VERSION "dbc-export 1 2025.20.8"

NS_ :

BS_:

BU_: ADSP APB APP APS APSB BB BMS CC CMP CMPD CP DAS DI DIF DIR DPB EPAS3P EPAS3S EPASTP EPASTS EPBL EPBR ESP EVSE FC GTW HCML HCMR HVP IBST ICR IDB LS OCS1P PARK PCS PM PMF PMR PNCD PTC RADC RCM RCM2 RCM3 RCU SCCM SCM SCS SDCR TAS TCU TPMS TRCM UI UIS UMC USM VC VCFRONT VCLEFT VCRIGHT VCSEC VEH

BO_ 969 VCSEC_BLEEndpointInfo: 8 VCSEC
 SG_ VCSEC_BLEEndpointInfoIndex M : 0|8@1+ (1,0) [0|255] "" Vector__XXX
 SG_ VCSEC_BLECENTERComponentID m1 : 8|16@1+ (1,0) [0|65535] "" Vector__XXX
 SG_ VCSEC_BLECENTERPcbaID m1 : 24|8@1+ (1,0) [0|255] "" Vector__XXX
 SG_ VCSEC_BLECENTERAssemblyID m1 : 32|8@1+ (1,0) [0|255] "" Vector__XXX
 SG_ VCSEC_BLECENTERUsageID m1 : 40|16@1+ (1,0) [0|65535] "" Vector__XXX
 SG_ VCSEC_BLECENTERCrc m2 : 8|32@1+ (1,0) [0|4294967295] "" Vector__XXX
 SG_ VCSEC_BLELEFTAppGitHashByte m3 : 8|56@1+ (1,0) [0|7.20575940379e+16] "" Vector__XXX
 SG_ VCSEC_BLELEFTComponentID m4 : 8|16@1+ (1,0) [0|65535] "" Vector__XXX
 SG_ VCSEC_BLELEFTPcbaID m4 : 24|8@1+ (1,0) [0|255] "" Vector__XXX
 SG_ VCSEC_BLELEFTAssemblyID m4 : 32|8@1+ (1,0) [0|255] "" Vector__XXX
 SG_ VCSEC_BLELEFTUsageID m4 : 40|16@1+ (1,0) [0|65535] "" Vector__XXX
 SG_ VCSEC_BLELEFTCrc m5 : 8|32@1+ (1,0) [0|4294967295] "" Vector__XXX
 SG_ VCSEC_BLERIGHTAppGitHashByte m6 : 8|56@1+ (1,0) [0|7.20575940379e+16] "" Vector__XXX
 SG_ VCSEC_BLERIGHTComponentID m7 : 8|16@1+ (1,0) [0|65535] "" Vector__XXX
 SG_ VCSEC_BLERIGHTPcbaID m7 : 24|8@1+ (1,0) [0|255] "" Vector__XXX
 SG_ VCSEC_BLERIGHTAssemblyID m7 : 32|8@1+ (1,0) [0|255] "" Vector__XXX
 SG_ VCSEC_BLERIGHTUsageID m7 : 40|16@1+ (1,0) [0|65535] "" Vector__XXX
 SG_ VCSEC_BLERIGHTCrc m8 : 8|32@1+ (1,0) [0|4294967295] "" Vector__XXX
 SG_ VCSEC_BLEREARAppGitHashByte m9 : 8|56@1+ (1,0) [0|7.20575940379e+16] "" Vector__XXX
 SG_ VCSEC_BLEREARComponentID m10 : 8|16@1+ (1,0) [0|65535] "" Vector__XXX
 SG_ VCSEC_BLEREARPcbaID m10 : 24|8@1+ (1,0) [0|255] "" Vector__XXX
 SG_ VCSEC_BLEREARAssemblyID m10 : 32|8@1+ (1,0) [0|255] "" Vector__XXX
 SG_ VCSEC_BLEREARUsageID m10 : 40|16@1+ (1,0) [0|65535] "" Vector__XXX
 SG_ VCSEC_BLEREARCrc m11 : 8|32@1+ (1,0) [0|4294967295] "" Vector__XXX
 SG_ VCSEC_UWBRightCrc m12 : 8|32@1+ (1,0) [0|4294967295] "" Vector__XXX
 SG_ VCSEC_UWBRightRadioConfigState m12 : 40|4@1+ (1,0) [0|15] "" Vector__XXX
 SG_ VCSEC_UWBRightUpdateStatus m12 : 44|3@1+ (1,0) [0|7] "" Vector__XXX
 SG_ VCSEC_UWBRightRetryLimitReached m12 : 47|1@1+ (1,0) [0|1] "" Vector__XXX
 SG_ VCSEC_UWBRightDspVersion m12 : 48|16@1+ (1,0) [0|65535] "" Vector__XXX
 SG_ VCSEC_UWBRightComponentID m13 : 8|8@1+ (1,0) [0|255] "" Vector__XXX
 SG_ VCSEC_UWBRightPcbaID m13 : 16|8@1+ (1,0) [0|255] "" Vector__XXX
 SG_ VCSEC_UWBRightAssemblyID m13 : 24|8@1+ (1,0) [0|255] "" Vector__XXX
 SG_ VCSEC_UWBRightUsageID m13 : 32|16@1+ (1,0) [0|65535] "" Vector__XXX
 SG_ VCSEC_UWBRearRightCrc m15 : 8|32@1+ (1,0) [0|4294967295] "" Vector__XXX
 SG_ VCSEC_UWBRearRightRadioConfigSta m15 : 40|4@1+ (1,0) [0|15] "" Vector__XXX
 SG_ VCSEC_UWBRearRightUpdateStatus m15 : 44|3@1+ (1,0) [0|7] "" Vector__XXX
 SG_ VCSEC_UWBRearRightRetryLimitReac m15 : 47|1@1+ (1,0) [0|1] "" Vector__XXX
 SG_ VCSEC_UWBRearRightDspVersion m15 : 48|16@1+ (1,0) [0|65535] "" Vector__XXX
 SG_ VCSEC_UWBRearRightComponentID m16 : 8|8@1+ (1,0) [0|255] "" Vector__XXX
 SG_ VCSEC_UWBRearRightPcbaID m16 : 16|8@1+ (1,0) [0|255] "" Vector__XXX
 SG_ VCSEC_UWBRearRightAssemblyID m16 : 24|8@1+ (1,0) [0|255] "" Vector__XXX
 SG_ VCSEC_UWBRearRightUsageID m16 : 32|16@1+ (1,0) [0|65535] "" Vector__XXX
 SG_ VCSEC_UWBRearLeftCrc m18 : 8|32@1+ (1,0) [0|4294967295] "" Vector__XXX
 SG_ VCSEC_UWBRearLeftRadioConfigStat m18 : 40|4@1+ (1,0) [0|15] "" Vector__XXX
 SG_ VCSEC_UWBRearLeftUpdateStatus m18 : 44|3@1+ (1,0) [0|7] "" Vector__XXX
 SG_ VCSEC_UWBRearLeftRetryLimitReach m18 : 47|1@1+ (1,0) [0|1] "" Vector__XXX
 SG_ VCSEC_UWBRearLeftDspVersion m18 : 48|16@1+ (1,0) [0|65535] "" Vector__XXX
 SG_ VCSEC_UWBRearLeftComponentID m19 : 8|8@1+ (1,0) [0|255] "" Vector__XXX
 SG_ VCSEC_UWBRearLeftPcbaID m19 : 16|8@1+ (1,0) [0|255] "" Vector__XXX
 SG_ VCSEC_UWBRearLeftAssemblyID m19 : 24|8@1+ (1,0) [0|255] "" Vector__XXX
 SG_ VCSEC_UWBRearLeftUsageID m19 : 32|16@1+ (1,0) [0|65535] "" Vector__XXX
 SG_ VCSEC_UWBRearCrc m21 : 8|32@1+ (1,0) [0|4294967295] "" Vector__XXX
 SG_ VCSEC_UWBRearRadioConfigState m21 : 40|4@1+ (1,0) [0|15] "" Vector__XXX
 SG_ VCSEC_UWBRearUpdateStatus m21 : 44|3@1+ (1,0) [0|7] "" Vector__XXX
 SG_ VCSEC_UWBRearRetryLimitReached m21 : 47|1@1+ (1,0) [0|1] "" Vector__XXX
 SG_ VCSEC_UWBRearDspVersion m21 : 48|16@1+ (1,0) [0|65535] "" Vector__XXX
 SG_ VCSEC_UWBRearComponentID m22 : 8|8@1+ (1,0) [0|255] "" Vector__XXX
 SG_ VCSEC_UWBRearPcbaID m22 : 16|8@1+ (1,0) [0|255] "" Vector__XXX
 SG_ VCSEC_UWBRearAssemblyID m22 : 24|8@1+ (1,0) [0|255] "" Vector__XXX
 SG_ VCSEC_UWBRearUsageID m22 : 32|16@1+ (1,0) [0|65535] "" Vector__XXX
 SG_ VCSEC_UWBLeftCrc m24 : 8|32@1+ (1,0) [0|4294967295] "" Vector__XXX
 SG_ VCSEC_UWBLeftRadioConfigState m24 : 40|4@1+ (1,0) [0|15] "" Vector__XXX
 SG_ VCSEC_UWBLeftUpdateStatus m24 : 44|3@1+ (1,0) [0|7] "" Vector__XXX
 SG_ VCSEC_UWBLeftRetryLimitReached m24 : 47|1@1+ (1,0) [0|1] "" Vector__XXX
 SG_ VCSEC_UWBLeftDspVersion m24 : 48|16@1+ (1,0) [0|65535] "" Vector__XXX
 SG_ VCSEC_UWBLeftComponentID m25 : 8|8@1+ (1,0) [0|255] "" Vector__XXX
 SG_ VCSEC_UWBLeftPcbaID m25 : 16|8@1+ (1,0) [0|255] "" Vector__XXX
 SG_ VCSEC_UWBLeftAssemblyID m25 : 24|8@1+ (1,0) [0|255] "" Vector__XXX
 SG_ VCSEC_UWBLeftUsageID m25 : 32|16@1+ (1,0) [0|65535] "" Vector__XXX
 SG_ VCSEC_UWBCenterCrc m27 : 8|32@1+ (1,0) [0|4294967295] "" Vector__XXX
 SG_ VCSEC_UWBCenterRadioConfigState m27 : 40|4@1+ (1,0) [0|15] "" Vector__XXX
 SG_ VCSEC_UWBCenterUpdateStatus m27 : 44|3@1+ (1,0) [0|7] "" Vector__XXX
 SG_ VCSEC_UWBCenterRetryLimitReached m27 : 47|1@1+ (1,0) [0|1] "" Vector__XXX
 SG_ VCSEC_UWBCenterDspVersion m27 : 48|16@1+ (1,0) [0|65535] "" Vector__XXX
 SG_ VCSEC_UWBCenterComponentID m28 : 8|8@1+ (1,0) [0|255] "" Vector__XXX
 SG_ VCSEC_UWBCenterPcbaID m28 : 16|8@1+ (1,0) [0|255] "" Vector__XXX
 SG_ VCSEC_UWBCenterAssemblyID m28 : 24|8@1+ (1,0) [0|255] "" Vector__XXX
 SG_ VCSEC_UWBCenterUsageID m28 : 32|16@1+ (1,0) [0|65535] "" Vector__XXX
 SG_ VCSEC_BLERIGHTREARCrc m30 : 8|32@1+ (1,0) [0|4294967295] "" Vector__XXX
 SG_ VCSEC_BLERIGHTREARComponentID m31 : 8|16@1+ (1,0) [0|65535] "" Vector__XXX
 SG_ VCSEC_BLERIGHTREARPcbaID m31 : 24|8@1+ (1,0) [0|255] "" Vector__XXX
 SG_ VCSEC_BLERIGHTREARAssemblyID m31 : 32|8@1+ (1,0) [0|255] "" Vector__XXX
 SG_ VCSEC_BLERIGHTREARUsageID m31 : 40|16@1+ (1,0) [0|65535] "" Vector__XXX
 SG_ VCSEC_BLENFCCRADLECrc m33 : 8|32@1+ (1,0) [0|4294967295] "" Vector__XXX
 SG_ VCSEC_BLENFCCRADLEComponentID m34 : 8|16@1+ (1,0) [0|65535] "" Vector__XXX
 SG_ VCSEC_BLENFCCRADLEPcbaID m34 : 24|8@1+ (1,0) [0|255] "" Vector__XXX
 SG_ VCSEC_BLENFCCRADLEAssemblyID m34 : 32|8@1+ (1,0) [0|255] "" Vector__XXX
 SG_ VCSEC_BLENFCCRADLEUsageID m34 : 40|16@1+ (1,0) [0|65535] "" Vector__XXX
 SG_ VCSEC_BLELEFTREARCrc m36 : 8|32@1+ (1,0) [0|4294967295] "" Vector__XXX
 SG_ VCSEC_BLELEFTREARComponentID m37 : 8|16@1+ (1,0) [0|65535] "" Vector__XXX
 SG_ VCSEC_BLELEFTREARPcbaID m37 : 24|8@1+ (1,0) [0|255] "" Vector__XXX
 SG_ VCSEC_BLELEFTREARAssemblyID m37 : 32|8@1+ (1,0) [0|255] "" Vector__XXX
 SG_ VCSEC_BLELEFTREARUsageID m37 : 40|16@1+ (1,0) [0|65535] "" Vector__XXX

BO_ 607 VCSEC_ChildSeatStatus: 8 VCSEC
 SG_ VCSEC_childSeat0_connectionState : 0|3@1+ (1,0) [0|7] "" Vector__XXX
 SG_ VCSEC_childSeat0_taskDisconnecti : 3|2@1+ (1,0) [0|3] "" Vector__XXX
 SG_ VCSEC_childSeat0_state : 5|4@1+ (1,0) [0|15] "" Vector__XXX
 SG_ VCSEC_childSeat0_taskErrorCode : 9|3@1+ (1,0) [0|7] "" Vector__XXX
 SG_ VCSEC_childSeat0_RSSI : 12|8@1- (1,0) [-128|127] "" Vector__XXX
 SG_ VCSEC_childSeat0_ISOFixStatus : 20|2@1+ (1,0) [0|3] "" Vector__XXX
 SG_ VCSEC_childSeat0_buckleStatus : 22|2@1+ (1,0) [0|3] "" Vector__XXX
 SG_ VCSEC_childSeat0_occupancyStatus : 24|2@1+ (1,0) [0|3] "" Vector__XXX
 SG_ VCSEC_childSeat1_connectionState : 26|3@1+ (1,0) [0|7] "" Vector__XXX
 SG_ VCSEC_childSeat1_taskDisconnecti : 29|2@1+ (1,0) [0|3] "" Vector__XXX
 SG_ VCSEC_childSeat1_state : 31|4@1+ (1,0) [0|15] "" Vector__XXX
 SG_ VCSEC_childSeat1_taskErrorCode : 35|3@1+ (1,0) [0|7] "" Vector__XXX
 SG_ VCSEC_childSeat1_RSSI : 38|8@1- (1,0) [-128|127] "" Vector__XXX
 SG_ VCSEC_childSeat1_ISOFixStatus : 46|2@1+ (1,0) [0|3] "" Vector__XXX
 SG_ VCSEC_childSeat1_buckleStatus : 48|2@1+ (1,0) [0|3] "" Vector__XXX
 SG_ VCSEC_childSeat1_occupancyStatus : 50|2@1+ (1,0) [0|3] "" Vector__XXX
 SG_ VCSEC_childPresenceDetectionWarn : 52|1@1+ (1,0) [0|1] "" Vector__XXX
 SG_ VCSEC_childSeatScanStatus : 53|2@1+ (1,0) [0|3] "" Vector__XXX
 SG_ VCSEC_childPresenceDetectionStat : 55|4@1+ (1,0) [0|15] "" Vector__XXX
 SG_ VCSEC_childPresenceDetectionSupp : 59|2@1+ (1,0) [0|3] "" Vector__XXX
 SG_ VCSEC_childPresenceDetectionNoti : 61|1@1+ (1,0) [0|1] "" Vector__XXX

BO_ 857 VCSEC_DeviceStatus: 8 VCSEC
 SG_ VCSEC_DeviceStatusIndex M : 0|7@1+ (1,0) [0|127] "" Vector__XXX
 SG_ VCSEC_Device0AuthResponseTime m0 : 7|7@1+ (50,0) [0|6300] "ms" Vector__XXX
 SG_ VCSEC_Device0Impermanent m0 : 14|1@1+ (1,0) [0|1] "" Vector__XXX
 SG_ VCSEC_Device0SELockedDown m0 : 15|1@1+ (1,0) [0|1] "" Vector__XXX
 SG_ VCSEC_Device0Version m0 : 16|16@1+ (1,0) [0|65535] "" Vector__XXX
 SG_ VCSEC_Device0WLEntry m0 : 32|5@1+ (1,0) [0|31] "" Vector__XXX
 SG_ VCSEC_Device0OSVersion m0 : 37|12@1+ (1,0) [0|4095] "" Vector__XXX
 SG_ VCSEC_Device0BatteryLevel m0 : 49|8@1+ (0.015625,0) [0|3.9] "V" Vector__XXX
 SG_ VCSEC_Device0Formfactor m0 : 57|5@1+ (1,0) [0|31] "" Vector__XXX
 SG_ VCSEC_Device0BlacklistStatus m0 : 62|1@1+ (1,0) [0|1] "" Vector__XXX
 SG_ VCSEC_Device0Stationary m0 : 63|1@1+ (1,0) [0|1] "" Vector__XXX
 SG_ VCSEC_Device0Bonded m2 : 8|1@1+ (1,0) [0|1] "" Vector__XXX
 SG_ VCSEC_Device0Role m2 : 9|4@1+ (1,0) [0|15] "" Vector__XXX
 SG_ VCSEC_Device0WhitelistActiveTime m2 : 16|16@1+ (1,0) [0|65535] "mins" Vector__XXX
 SG_ VCSEC_Device0SHA1 m2 : 32|32@1+ (1,0) [0|4294967295] "" Vector__XXX
 SG_ VCSEC_Device0Permissions m3 : 32|32@1+ (1,0) [0|4294967295] "" Vector__XXX
 SG_ VCSEC_Device0ManufacturerHashBit m5 : 8|24@1+ (1,0) [0|16777215] "" Vector__XXX
 SG_ VCSEC_Device0BuildNumberHashBits m5 : 32|32@1+ (1,0) [0|4294967295] "" Vector__XXX
 SG_ VCSEC_Device1AuthResponseTime m6 : 7|7@1+ (50,0) [0|6300] "ms" Vector__XXX
 SG_ VCSEC_Device1Impermanent m6 : 14|1@1+ (1,0) [0|1] "" Vector__XXX
 SG_ VCSEC_Device1SELockedDown m6 : 15|1@1+ (1,0) [0|1] "" Vector__XXX
 SG_ VCSEC_Device1Version m6 : 16|16@1+ (1,0) [0|65535] "" Vector__XXX
 SG_ VCSEC_Device1WLEntry m6 : 32|5@1+ (1,0) [0|31] "" Vector__XXX
 SG_ VCSEC_Device1OSVersion m6 : 37|12@1+ (1,0) [0|4095] "" Vector__XXX
 SG_ VCSEC_Device1BatteryLevel m6 : 49|8@1+ (0.015625,0) [0|3.9] "V" Vector__XXX
 SG_ VCSEC_Device1Formfactor m6 : 57|5@1+ (1,0) [0|31] "" Vector__XXX
 SG_ VCSEC_Device1BlacklistStatus m6 : 62|1@1+ (1,0) [0|1] "" Vector__XXX
 SG_ VCSEC_Device1Stationary m6 : 63|1@1+ (1,0) [0|1] "" Vector__XXX
 SG_ VCSEC_Device1Bonded m8 : 8|1@1+ (1,0) [0|1] "" Vector__XXX
 SG_ VCSEC_Device1Role m8 : 9|4@1+ (1,0) [0|15] "" Vector__XXX
 SG_ VCSEC_Device1WhitelistActiveTime m8 : 16|16@1+ (1,0) [0|65535] "mins" Vector__XXX
 SG_ VCSEC_Device1SHA1 m8 : 32|32@1+ (1,0) [0|4294967295] "" Vector__XXX
 SG_ VCSEC_Device1Permissions m9 : 32|32@1+ (1,0) [0|4294967295] "" Vector__XXX
 SG_ VCSEC_Device1ManufacturerHashBit m11 : 8|24@1+ (1,0) [0|16777215] "" Vector__XXX
 SG_ VCSEC_Device1BuildNumberHashBits m11 : 32|32@1+ (1,0) [0|4294967295] "" Vector__XXX
 SG_ VCSEC_Device2AuthResponseTime m12 : 7|7@1+ (50,0) [0|6300] "ms" Vector__XXX
 SG_ VCSEC_Device2Impermanent m12 : 14|1@1+ (1,0) [0|1] "" Vector__XXX
 SG_ VCSEC_Device2SELockedDown m12 : 15|1@1+ (1,0) [0|1] "" Vector__XXX
 SG_ VCSEC_Device2Version m12 : 16|16@1+ (1,0) [0|65535] "" Vector__XXX
 SG_ VCSEC_Device2WLEntry m12 : 32|5@1+ (1,0) [0|31] "" Vector__XXX
 SG_ VCSEC_Device2OSVersion m12 : 37|12@1+ (1,0) [0|4095] "" Vector__XXX
 SG_ VCSEC_Device2BatteryLevel m12 : 49|8@1+ (0.015625,0) [0|3.9] "V" Vector__XXX
 SG_ VCSEC_Device2Formfactor m12 : 57|5@1+ (1,0) [0|31] "" Vector__XXX
 SG_ VCSEC_Device2BlacklistStatus m12 : 62|1@1+ (1,0) [0|1] "" Vector__XXX
 SG_ VCSEC_Device2Stationary m12 : 63|1@1+ (1,0) [0|1] "" Vector__XXX
 SG_ VCSEC_Device2Bonded m14 : 8|1@1+ (1,0) [0|1] "" Vector__XXX
 SG_ VCSEC_Device2Role m14 : 9|4@1+ (1,0) [0|15] "" Vector__XXX
 SG_ VCSEC_Device2WhitelistActiveTime m14 : 16|16@1+ (1,0) [0|65535] "mins" Vector__XXX
 SG_ VCSEC_Device2SHA1 m14 : 32|32@1+ (1,0) [0|4294967295] "" Vector__XXX
 SG_ VCSEC_Device2Permissions m15 : 32|32@1+ (1,0) [0|4294967295] "" Vector__XXX
 SG_ VCSEC_Device2ManufacturerHashBit m17 : 8|24@1+ (1,0) [0|16777215] "" Vector__XXX
 SG_ VCSEC_Device2BuildNumberHashBits m17 : 32|32@1+ (1,0) [0|4294967295] "" Vector__XXX
 SG_ VCSEC_Device3AuthResponseTime m18 : 7|7@1+ (50,0) [0|6300] "ms" Vector__XXX
 SG_ VCSEC_Device3Impermanent m18 : 14|1@1+ (1,0) [0|1] "" Vector__XXX
 SG_ VCSEC_Device3SELockedDown m18 : 15|1@1+ (1,0) [0|1] "" Vector__XXX
 SG_ VCSEC_Device3Version m18 : 16|16@1+ (1,0) [0|65535] "" Vector__XXX
 SG_ VCSEC_Device3WLEntry m18 : 32|5@1+ (1,0) [0|31] "" Vector__XXX
 SG_ VCSEC_Device3OSVersion m18 : 37|12@1+ (1,0) [0|4095] "" Vector__XXX
 SG_ VCSEC_Device3BatteryLevel m18 : 49|8@1+ (0.015625,0) [0|3.9] "V" Vector__XXX
 SG_ VCSEC_Device3Formfactor m18 : 57|5@1+ (1,0) [0|31] "" Vector__XXX
 SG_ VCSEC_Device3BlacklistStatus m18 : 62|1@1+ (1,0) [0|1] "" Vector__XXX
 SG_ VCSEC_Device3Stationary m18 : 63|1@1+ (1,0) [0|1] "" Vector__XXX
 SG_ VCSEC_Device3Bonded m20 : 8|1@1+ (1,0) [0|1] "" Vector__XXX
 SG_ VCSEC_Device3Role m20 : 9|4@1+ (1,0) [0|15] "" Vector__XXX
 SG_ VCSEC_Device3WhitelistActiveTime m20 : 16|16@1+ (1,0) [0|65535] "mins" Vector__XXX
 SG_ VCSEC_Device3SHA1 m20 : 32|32@1+ (1,0) [0|4294967295] "" Vector__XXX
 SG_ VCSEC_Device3Permissions m21 : 32|32@1+ (1,0) [0|4294967295] "" Vector__XXX
 SG_ VCSEC_Device3ManufacturerHashBit m23 : 8|24@1+ (1,0) [0|16777215] "" Vector__XXX
 SG_ VCSEC_Device3BuildNumberHashBits m23 : 32|32@1+ (1,0) [0|4294967295] "" Vector__XXX
 SG_ VCSEC_Device4AuthResponseTime m24 : 7|7@1+ (50,0) [0|6300] "ms" Vector__XXX
 SG_ VCSEC_Device4Impermanent m24 : 14|1@1+ (1,0) [0|1] "" Vector__XXX
 SG_ VCSEC_Device4SELockedDown m24 : 15|1@1+ (1,0) [0|1] "" Vector__XXX
 SG_ VCSEC_Device4Version m24 : 16|16@1+ (1,0) [0|65535] "" Vector__XXX
 SG_ VCSEC_Device4WLEntry m24 : 32|5@1+ (1,0) [0|31] "" Vector__XXX
 SG_ VCSEC_Device4OSVersion m24 : 37|12@1+ (1,0) [0|4095] "" Vector__XXX
 SG_ VCSEC_Device4BatteryLevel m24 : 49|8@1+ (0.015625,0) [0|3.9] "V" Vector__XXX
 SG_ VCSEC_Device4Formfactor m24 : 57|5@1+ (1,0) [0|31] "" Vector__XXX
 SG_ VCSEC_Device4BlacklistStatus m24 : 62|1@1+ (1,0) [0|1] "" Vector__XXX
 SG_ VCSEC_Device4Stationary m24 : 63|1@1+ (1,0) [0|1] "" Vector__XXX
 SG_ VCSEC_Device4Bonded m26 : 8|1@1+ (1,0) [0|1] "" Vector__XXX
 SG_ VCSEC_Device4Role m26 : 9|4@1+ (1,0) [0|15] "" Vector__XXX
 SG_ VCSEC_Device4WhitelistActiveTime m26 : 16|16@1+ (1,0) [0|65535] "mins" Vector__XXX
 SG_ VCSEC_Device4SHA1 m26 : 32|32@1+ (1,0) [0|4294967295] "" Vector__XXX
 SG_ VCSEC_Device4Permissions m27 : 32|32@1+ (1,0) [0|4294967295] "" Vector__XXX
 SG_ VCSEC_Device4ManufacturerHashBit m29 : 8|24@1+ (1,0) [0|16777215] "" Vector__XXX
 SG_ VCSEC_Device4BuildNumberHashBits m29 : 32|32@1+ (1,0) [0|4294967295] "" Vector__XXX
 SG_ VCSEC_Device5AuthResponseTime m30 : 7|7@1+ (50,0) [0|6300] "ms" Vector__XXX
 SG_ VCSEC_Device5Impermanent m30 : 14|1@1+ (1,0) [0|1] "" Vector__XXX
 SG_ VCSEC_Device5SELockedDown m30 : 15|1@1+ (1,0) [0|1] "" Vector__XXX
 SG_ VCSEC_Device5Version m30 : 16|16@1+ (1,0) [0|65535] "" Vector__XXX
 SG_ VCSEC_Device5WLEntry m30 : 32|5@1+ (1,0) [0|31] "" Vector__XXX
 SG_ VCSEC_Device5OSVersion m30 : 37|12@1+ (1,0) [0|4095] "" Vector__XXX
 SG_ VCSEC_Device5BatteryLevel m30 : 49|8@1+ (0.015625,0) [0|3.9] "V" Vector__XXX
 SG_ VCSEC_Device5Formfactor m30 : 57|5@1+ (1,0) [0|31] "" Vector__XXX
 SG_ VCSEC_Device5BlacklistStatus m30 : 62|1@1+ (1,0) [0|1] "" Vector__XXX
 SG_ VCSEC_Device5Stationary m30 : 63|1@1+ (1,0) [0|1] "" Vector__XXX
 SG_ VCSEC_Device5Bonded m32 : 8|1@1+ (1,0) [0|1] "" Vector__XXX
 SG_ VCSEC_Device5Role m32 : 9|4@1+ (1,0) [0|15] "" Vector__XXX
 SG_ VCSEC_Device5WhitelistActiveTime m32 : 16|16@1+ (1,0) [0|65535] "mins" Vector__XXX
 SG_ VCSEC_Device5SHA1 m32 : 32|32@1+ (1,0) [0|4294967295] "" Vector__XXX
 SG_ VCSEC_Device5Permissions m33 : 32|32@1+ (1,0) [0|4294967295] "" Vector__XXX
 SG_ VCSEC_Device5ManufacturerHashBit m35 : 8|24@1+ (1,0) [0|16777215] "" Vector__XXX
 SG_ VCSEC_Device5BuildNumberHashBits m35 : 32|32@1+ (1,0) [0|4294967295] "" Vector__XXX
 SG_ VCSEC_Device6AuthResponseTime m36 : 7|7@1+ (50,0) [0|6300] "ms" Vector__XXX
 SG_ VCSEC_Device6Impermanent m36 : 14|1@1+ (1,0) [0|1] "" Vector__XXX
 SG_ VCSEC_Device6SELockedDown m36 : 15|1@1+ (1,0) [0|1] "" Vector__XXX
 SG_ VCSEC_Device6Version m36 : 16|16@1+ (1,0) [0|65535] "" Vector__XXX
 SG_ VCSEC_Device6WLEntry m36 : 32|5@1+ (1,0) [0|31] "" Vector__XXX
 SG_ VCSEC_Device6OSVersion m36 : 37|12@1+ (1,0) [0|4095] "" Vector__XXX
 SG_ VCSEC_Device6BatteryLevel m36 : 49|8@1+ (0.015625,0) [0|3.9] "V" Vector__XXX
 SG_ VCSEC_Device6Formfactor m36 : 57|5@1+ (1,0) [0|31] "" Vector__XXX
 SG_ VCSEC_Device6BlacklistStatus m36 : 62|1@1+ (1,0) [0|1] "" Vector__XXX
 SG_ VCSEC_Device6Stationary m36 : 63|1@1+ (1,0) [0|1] "" Vector__XXX
 SG_ VCSEC_Device6Bonded m38 : 8|1@1+ (1,0) [0|1] "" Vector__XXX
 SG_ VCSEC_Device6Role m38 : 9|4@1+ (1,0) [0|15] "" Vector__XXX
 SG_ VCSEC_Device6WhitelistActiveTime m38 : 16|16@1+ (1,0) [0|65535] "mins" Vector__XXX
 SG_ VCSEC_Device6SHA1 m38 : 32|32@1+ (1,0) [0|4294967295] "" Vector__XXX
 SG_ VCSEC_Device6Permissions m39 : 32|32@1+ (1,0) [0|4294967295] "" Vector__XXX
 SG_ VCSEC_Device6ManufacturerHashBit m41 : 8|24@1+ (1,0) [0|16777215] "" Vector__XXX
 SG_ VCSEC_Device6BuildNumberHashBits m41 : 32|32@1+ (1,0) [0|4294967295] "" Vector__XXX
 SG_ VCSEC_Device7AuthResponseTime m42 : 7|7@1+ (50,0) [0|6300] "ms" Vector__XXX
 SG_ VCSEC_Device7Impermanent m42 : 14|1@1+ (1,0) [0|1] "" Vector__XXX
 SG_ VCSEC_Device7SELockedDown m42 : 15|1@1+ (1,0) [0|1] "" Vector__XXX
 SG_ VCSEC_Device7Version m42 : 16|16@1+ (1,0) [0|65535] "" Vector__XXX
 SG_ VCSEC_Device7WLEntry m42 : 32|5@1+ (1,0) [0|31] "" Vector__XXX
 SG_ VCSEC_Device7OSVersion m42 : 37|12@1+ (1,0) [0|4095] "" Vector__XXX
 SG_ VCSEC_Device7BatteryLevel m42 : 49|8@1+ (0.015625,0) [0|3.9] "V" Vector__XXX
 SG_ VCSEC_Device7Formfactor m42 : 57|5@1+ (1,0) [0|31] "" Vector__XXX
 SG_ VCSEC_Device7BlacklistStatus m42 : 62|1@1+ (1,0) [0|1] "" Vector__XXX
 SG_ VCSEC_Device7Stationary m42 : 63|1@1+ (1,0) [0|1] "" Vector__XXX
 SG_ VCSEC_Device7Bonded m44 : 8|1@1+ (1,0) [0|1] "" Vector__XXX
 SG_ VCSEC_Device7Role m44 : 9|4@1+ (1,0) [0|15] "" Vector__XXX
 SG_ VCSEC_Device7WhitelistActiveTime m44 : 16|16@1+ (1,0) [0|65535] "mins" Vector__XXX
 SG_ VCSEC_Device7SHA1 m44 : 32|32@1+ (1,0) [0|4294967295] "" Vector__XXX
 SG_ VCSEC_Device7Permissions m45 : 32|32@1+ (1,0) [0|4294967295] "" Vector__XXX
 SG_ VCSEC_Device7ManufacturerHashBit m47 : 8|24@1+ (1,0) [0|16777215] "" Vector__XXX
 SG_ VCSEC_Device7BuildNumberHashBits m47 : 32|32@1+ (1,0) [0|4294967295] "" Vector__XXX
 SG_ VCSEC_Device8AuthResponseTime m48 : 7|7@1+ (50,0) [0|6300] "ms" Vector__XXX
 SG_ VCSEC_Device8Impermanent m48 : 14|1@1+ (1,0) [0|1] "" Vector__XXX
 SG_ VCSEC_Device8SELockedDown m48 : 15|1@1+ (1,0) [0|1] "" Vector__XXX
 SG_ VCSEC_Device8Version m48 : 16|16@1+ (1,0) [0|65535] "" Vector__XXX
 SG_ VCSEC_Device8WLEntry m48 : 32|5@1+ (1,0) [0|31] "" Vector__XXX
 SG_ VCSEC_Device8OSVersion m48 : 37|12@1+ (1,0) [0|4095] "" Vector__XXX
 SG_ VCSEC_Device8BatteryLevel m48 : 49|8@1+ (0.015625,0) [0|3.9] "V" Vector__XXX
 SG_ VCSEC_Device8Formfactor m48 : 57|5@1+ (1,0) [0|31] "" Vector__XXX
 SG_ VCSEC_Device8BlacklistStatus m48 : 62|1@1+ (1,0) [0|1] "" Vector__XXX
 SG_ VCSEC_Device8Stationary m48 : 63|1@1+ (1,0) [0|1] "" Vector__XXX
 SG_ VCSEC_Device8Bonded m50 : 8|1@1+ (1,0) [0|1] "" Vector__XXX
 SG_ VCSEC_Device8Role m50 : 9|4@1+ (1,0) [0|15] "" Vector__XXX
 SG_ VCSEC_Device8WhitelistActiveTime m50 : 16|16@1+ (1,0) [0|65535] "mins" Vector__XXX
 SG_ VCSEC_Device8SHA1 m50 : 32|32@1+ (1,0) [0|4294967295] "" Vector__XXX
 SG_ VCSEC_Device8Permissions m51 : 32|32@1+ (1,0) [0|4294967295] "" Vector__XXX
 SG_ VCSEC_Device8ManufacturerHashBit m53 : 8|24@1+ (1,0) [0|16777215] "" Vector__XXX
 SG_ VCSEC_Device8BuildNumberHashBits m53 : 32|32@1+ (1,0) [0|4294967295] "" Vector__XXX
 SG_ VCSEC_Device9AuthResponseTime m54 : 7|7@1+ (50,0) [0|6300] "ms" Vector__XXX
 SG_ VCSEC_Device9Impermanent m54 : 14|1@1+ (1,0) [0|1] "" Vector__XXX
 SG_ VCSEC_Device9SELockedDown m54 : 15|1@1+ (1,0) [0|1] "" Vector__XXX
 SG_ VCSEC_Device9Version m54 : 16|16@1+ (1,0) [0|65535] "" Vector__XXX
 SG_ VCSEC_Device9WLEntry m54 : 32|5@1+ (1,0) [0|31] "" Vector__XXX
 SG_ VCSEC_Device9OSVersion m54 : 37|12@1+ (1,0) [0|4095] "" Vector__XXX
 SG_ VCSEC_Device9BatteryLevel m54 : 49|8@1+ (0.015625,0) [0|3.9] "V" Vector__XXX
 SG_ VCSEC_Device9Formfactor m54 : 57|5@1+ (1,0) [0|31] "" Vector__XXX
 SG_ VCSEC_Device9BlacklistStatus m54 : 62|1@1+ (1,0) [0|1] "" Vector__XXX
 SG_ VCSEC_Device9Stationary m54 : 63|1@1+ (1,0) [0|1] "" Vector__XXX
 SG_ VCSEC_Device9Bonded m56 : 8|1@1+ (1,0) [0|1] "" Vector__XXX
 SG_ VCSEC_Device9Role m56 : 9|4@1+ (1,0) [0|15] "" Vector__XXX
 SG_ VCSEC_Device9WhitelistActiveTime m56 : 16|16@1+ (1,0) [0|65535] "mins" Vector__XXX
 SG_ VCSEC_Device9SHA1 m56 : 32|32@1+ (1,0) [0|4294967295] "" Vector__XXX
 SG_ VCSEC_Device9Permissions m57 : 32|32@1+ (1,0) [0|4294967295] "" Vector__XXX
 SG_ VCSEC_Device9ManufacturerHashBit m59 : 8|24@1+ (1,0) [0|16777215] "" Vector__XXX
 SG_ VCSEC_Device9BuildNumberHashBits m59 : 32|32@1+ (1,0) [0|4294967295] "" Vector__XXX
 SG_ VCSEC_Device10AuthResponseTime m60 : 7|7@1+ (50,0) [0|6300] "ms" Vector__XXX
 SG_ VCSEC_Device10Impermanent m60 : 14|1@1+ (1,0) [0|1] "" Vector__XXX
 SG_ VCSEC_Device10SELockedDown m60 : 15|1@1+ (1,0) [0|1] "" Vector__XXX
 SG_ VCSEC_Device10Version m60 : 16|16@1+ (1,0) [0|65535] "" Vector__XXX
 SG_ VCSEC_Device10WLEntry m60 : 32|5@1+ (1,0) [0|31] "" Vector__XXX
 SG_ VCSEC_Device10OSVersion m60 : 37|12@1+ (1,0) [0|4095] "" Vector__XXX
 SG_ VCSEC_Device10BatteryLevel m60 : 49|8@1+ (0.015625,0) [0|3.9] "V" Vector__XXX
 SG_ VCSEC_Device10Formfactor m60 : 57|5@1+ (1,0) [0|31] "" Vector__XXX
 SG_ VCSEC_Device10BlacklistStatus m60 : 62|1@1+ (1,0) [0|1] "" Vector__XXX
 SG_ VCSEC_Device10Stationary m60 : 63|1@1+ (1,0) [0|1] "" Vector__XXX
 SG_ VCSEC_Device10Bonded m62 : 8|1@1+ (1,0) [0|1] "" Vector__XXX
 SG_ VCSEC_Device10Role m62 : 9|4@1+ (1,0) [0|15] "" Vector__XXX
 SG_ VCSEC_Device10WhitelistActiveTim m62 : 16|16@1+ (1,0) [0|65535] "mins" Vector__XXX
 SG_ VCSEC_Device10SHA1 m62 : 32|32@1+ (1,0) [0|4294967295] "" Vector__XXX
 SG_ VCSEC_Device10Permissions m63 : 32|32@1+ (1,0) [0|4294967295] "" Vector__XXX
 SG_ VCSEC_Device10ManufacturerHashBi m65 : 8|24@1+ (1,0) [0|16777215] "" Vector__XXX
 SG_ VCSEC_Device10BuildNumberHashBit m65 : 32|32@1+ (1,0) [0|4294967295] "" Vector__XXX
 SG_ VCSEC_Device11AuthResponseTime m66 : 7|7@1+ (50,0) [0|6300] "ms" Vector__XXX
 SG_ VCSEC_Device11Impermanent m66 : 14|1@1+ (1,0) [0|1] "" Vector__XXX
 SG_ VCSEC_Device11SELockedDown m66 : 15|1@1+ (1,0) [0|1] "" Vector__XXX
 SG_ VCSEC_Device11Version m66 : 16|16@1+ (1,0) [0|65535] "" Vector__XXX
 SG_ VCSEC_Device11WLEntry m66 : 32|5@1+ (1,0) [0|31] "" Vector__XXX
 SG_ VCSEC_Device11OSVersion m66 : 37|12@1+ (1,0) [0|4095] "" Vector__XXX
 SG_ VCSEC_Device11BatteryLevel m66 : 49|8@1+ (0.015625,0) [0|3.9] "V" Vector__XXX
 SG_ VCSEC_Device11Formfactor m66 : 57|5@1+ (1,0) [0|31] "" Vector__XXX
 SG_ VCSEC_Device11BlacklistStatus m66 : 62|1@1+ (1,0) [0|1] "" Vector__XXX
 SG_ VCSEC_Device11Stationary m66 : 63|1@1+ (1,0) [0|1] "" Vector__XXX
 SG_ VCSEC_Device11Bonded m68 : 8|1@1+ (1,0) [0|1] "" Vector__XXX
 SG_ VCSEC_Device11Role m68 : 9|4@1+ (1,0) [0|15] "" Vector__XXX
 SG_ VCSEC_Device11WhitelistActiveTim m68 : 16|16@1+ (1,0) [0|65535] "mins" Vector__XXX
 SG_ VCSEC_Device11SHA1 m68 : 32|32@1+ (1,0) [0|4294967295] "" Vector__XXX
 SG_ VCSEC_Device11Permissions m69 : 32|32@1+ (1,0) [0|4294967295] "" Vector__XXX
 SG_ VCSEC_Device11ManufacturerHashBi m71 : 8|24@1+ (1,0) [0|16777215] "" Vector__XXX
 SG_ VCSEC_Device11BuildNumberHashBit m71 : 32|32@1+ (1,0) [0|4294967295] "" Vector__XXX
 SG_ VCSEC_Device12AuthResponseTime m72 : 7|7@1+ (50,0) [0|6300] "ms" Vector__XXX
 SG_ VCSEC_Device12Impermanent m72 : 14|1@1+ (1,0) [0|1] "" Vector__XXX
 SG_ VCSEC_Device12SELockedDown m72 : 15|1@1+ (1,0) [0|1] "" Vector__XXX
 SG_ VCSEC_Device12Version m72 : 16|16@1+ (1,0) [0|65535] "" Vector__XXX
 SG_ VCSEC_Device12WLEntry m72 : 32|5@1+ (1,0) [0|31] "" Vector__XXX
 SG_ VCSEC_Device12OSVersion m72 : 37|12@1+ (1,0) [0|4095] "" Vector__XXX
 SG_ VCSEC_Device12BatteryLevel m72 : 49|8@1+ (0.015625,0) [0|3.9] "V" Vector__XXX
 SG_ VCSEC_Device12Formfactor m72 : 57|5@1+ (1,0) [0|31] "" Vector__XXX
 SG_ VCSEC_Device12BlacklistStatus m72 : 62|1@1+ (1,0) [0|1] "" Vector__XXX
 SG_ VCSEC_Device12Stationary m72 : 63|1@1+ (1,0) [0|1] "" Vector__XXX
 SG_ VCSEC_Device12Bonded m74 : 8|1@1+ (1,0) [0|1] "" Vector__XXX
 SG_ VCSEC_Device12Role m74 : 9|4@1+ (1,0) [0|15] "" Vector__XXX
 SG_ VCSEC_Device12WhitelistActiveTim m74 : 16|16@1+ (1,0) [0|65535] "mins" Vector__XXX
 SG_ VCSEC_Device12SHA1 m74 : 32|32@1+ (1,0) [0|4294967295] "" Vector__XXX
 SG_ VCSEC_Device12Permissions m75 : 32|32@1+ (1,0) [0|4294967295] "" Vector__XXX
 SG_ VCSEC_Device12ManufacturerHashBi m77 : 8|24@1+ (1,0) [0|16777215] "" Vector__XXX
 SG_ VCSEC_Device12BuildNumberHashBit m77 : 32|32@1+ (1,0) [0|4294967295] "" Vector__XXX
 SG_ VCSEC_Device13AuthResponseTime m78 : 7|7@1+ (50,0) [0|6300] "ms" Vector__XXX
 SG_ VCSEC_Device13Impermanent m78 : 14|1@1+ (1,0) [0|1] "" Vector__XXX
 SG_ VCSEC_Device13SELockedDown m78 : 15|1@1+ (1,0) [0|1] "" Vector__XXX
 SG_ VCSEC_Device13Version m78 : 16|16@1+ (1,0) [0|65535] "" Vector__XXX
 SG_ VCSEC_Device13WLEntry m78 : 32|5@1+ (1,0) [0|31] "" Vector__XXX
 SG_ VCSEC_Device13OSVersion m78 : 37|12@1+ (1,0) [0|4095] "" Vector__XXX
 SG_ VCSEC_Device13BatteryLevel m78 : 49|8@1+ (0.015625,0) [0|3.9] "V" Vector__XXX
 SG_ VCSEC_Device13Formfactor m78 : 57|5@1+ (1,0) [0|31] "" Vector__XXX
 SG_ VCSEC_Device13BlacklistStatus m78 : 62|1@1+ (1,0) [0|1] "" Vector__XXX
 SG_ VCSEC_Device13Stationary m78 : 63|1@1+ (1,0) [0|1] "" Vector__XXX
 SG_ VCSEC_Device13Bonded m80 : 8|1@1+ (1,0) [0|1] "" Vector__XXX
 SG_ VCSEC_Device13Role m80 : 9|4@1+ (1,0) [0|15] "" Vector__XXX
 SG_ VCSEC_Device13WhitelistActiveTim m80 : 16|16@1+ (1,0) [0|65535] "mins" Vector__XXX
 SG_ VCSEC_Device13SHA1 m80 : 32|32@1+ (1,0) [0|4294967295] "" Vector__XXX
 SG_ VCSEC_Device13Permissions m81 : 32|32@1+ (1,0) [0|4294967295] "" Vector__XXX
 SG_ VCSEC_Device13ManufacturerHashBi m83 : 8|24@1+ (1,0) [0|16777215] "" Vector__XXX
 SG_ VCSEC_Device13BuildNumberHashBit m83 : 32|32@1+ (1,0) [0|4294967295] "" Vector__XXX
 SG_ VCSEC_Device14AuthResponseTime m84 : 7|7@1+ (50,0) [0|6300] "ms" Vector__XXX
 SG_ VCSEC_Device14Impermanent m84 : 14|1@1+ (1,0) [0|1] "" Vector__XXX
 SG_ VCSEC_Device14SELockedDown m84 : 15|1@1+ (1,0) [0|1] "" Vector__XXX
 SG_ VCSEC_Device14Version m84 : 16|16@1+ (1,0) [0|65535] "" Vector__XXX
 SG_ VCSEC_Device14WLEntry m84 : 32|5@1+ (1,0) [0|31] "" Vector__XXX
 SG_ VCSEC_Device14OSVersion m84 : 37|12@1+ (1,0) [0|4095] "" Vector__XXX
 SG_ VCSEC_Device14BatteryLevel m84 : 49|8@1+ (0.015625,0) [0|3.9] "V" Vector__XXX
 SG_ VCSEC_Device14Formfactor m84 : 57|5@1+ (1,0) [0|31] "" Vector__XXX
 SG_ VCSEC_Device14BlacklistStatus m84 : 62|1@1+ (1,0) [0|1] "" Vector__XXX
 SG_ VCSEC_Device14Stationary m84 : 63|1@1+ (1,0) [0|1] "" Vector__XXX
 SG_ VCSEC_Device14Bonded m86 : 8|1@1+ (1,0) [0|1] "" Vector__XXX
 SG_ VCSEC_Device14Role m86 : 9|4@1+ (1,0) [0|15] "" Vector__XXX
 SG_ VCSEC_Device14WhitelistActiveTim m86 : 16|16@1+ (1,0) [0|65535] "mins" Vector__XXX
 SG_ VCSEC_Device14SHA1 m86 : 32|32@1+ (1,0) [0|4294967295] "" Vector__XXX
 SG_ VCSEC_Device14Permissions m87 : 32|32@1+ (1,0) [0|4294967295] "" Vector__XXX
 SG_ VCSEC_Device14ManufacturerHashBi m89 : 8|24@1+ (1,0) [0|16777215] "" Vector__XXX
 SG_ VCSEC_Device14BuildNumberHashBit m89 : 32|32@1+ (1,0) [0|4294967295] "" Vector__XXX
 SG_ VCSEC_Device15AuthResponseTime m90 : 7|7@1+ (50,0) [0|6300] "ms" Vector__XXX
 SG_ VCSEC_Device15Impermanent m90 : 14|1@1+ (1,0) [0|1] "" Vector__XXX
 SG_ VCSEC_Device15SELockedDown m90 : 15|1@1+ (1,0) [0|1] "" Vector__XXX
 SG_ VCSEC_Device15Version m90 : 16|16@1+ (1,0) [0|65535] "" Vector__XXX
 SG_ VCSEC_Device15WLEntry m90 : 32|5@1+ (1,0) [0|31] "" Vector__XXX
 SG_ VCSEC_Device15OSVersion m90 : 37|12@1+ (1,0) [0|4095] "" Vector__XXX
 SG_ VCSEC_Device15BatteryLevel m90 : 49|8@1+ (0.015625,0) [0|3.9] "V" Vector__XXX
 SG_ VCSEC_Device15Formfactor m90 : 57|5@1+ (1,0) [0|31] "" Vector__XXX
 SG_ VCSEC_Device15BlacklistStatus m90 : 62|1@1+ (1,0) [0|1] "" Vector__XXX
 SG_ VCSEC_Device15Stationary m90 : 63|1@1+ (1,0) [0|1] "" Vector__XXX
 SG_ VCSEC_Device15Bonded m92 : 8|1@1+ (1,0) [0|1] "" Vector__XXX
 SG_ VCSEC_Device15Role m92 : 9|4@1+ (1,0) [0|15] "" Vector__XXX
 SG_ VCSEC_Device15WhitelistActiveTim m92 : 16|16@1+ (1,0) [0|65535] "mins" Vector__XXX
 SG_ VCSEC_Device15SHA1 m92 : 32|32@1+ (1,0) [0|4294967295] "" Vector__XXX
 SG_ VCSEC_Device15Permissions m93 : 32|32@1+ (1,0) [0|4294967295] "" Vector__XXX
 SG_ VCSEC_Device15ManufacturerHashBi m95 : 8|24@1+ (1,0) [0|16777215] "" Vector__XXX
 SG_ VCSEC_Device15BuildNumberHashBit m95 : 32|32@1+ (1,0) [0|4294967295] "" Vector__XXX
 SG_ VCSEC_Device16AuthResponseTime m96 : 7|7@1+ (50,0) [0|6300] "ms" Vector__XXX
 SG_ VCSEC_Device16Impermanent m96 : 14|1@1+ (1,0) [0|1] "" Vector__XXX
 SG_ VCSEC_Device16SELockedDown m96 : 15|1@1+ (1,0) [0|1] "" Vector__XXX
 SG_ VCSEC_Device16Version m96 : 16|16@1+ (1,0) [0|65535] "" Vector__XXX
 SG_ VCSEC_Device16WLEntry m96 : 32|5@1+ (1,0) [0|31] "" Vector__XXX
 SG_ VCSEC_Device16OSVersion m96 : 37|12@1+ (1,0) [0|4095] "" Vector__XXX
 SG_ VCSEC_Device16BatteryLevel m96 : 49|8@1+ (0.015625,0) [0|3.9] "V" Vector__XXX
 SG_ VCSEC_Device16Formfactor m96 : 57|5@1+ (1,0) [0|31] "" Vector__XXX
 SG_ VCSEC_Device16BlacklistStatus m96 : 62|1@1+ (1,0) [0|1] "" Vector__XXX
 SG_ VCSEC_Device16Stationary m96 : 63|1@1+ (1,0) [0|1] "" Vector__XXX
 SG_ VCSEC_Device16Bonded m98 : 8|1@1+ (1,0) [0|1] "" Vector__XXX
 SG_ VCSEC_Device16Role m98 : 9|4@1+ (1,0) [0|15] "" Vector__XXX
 SG_ VCSEC_Device16WhitelistActiveTim m98 : 16|16@1+ (1,0) [0|65535] "mins" Vector__XXX
 SG_ VCSEC_Device16SHA1 m98 : 32|32@1+ (1,0) [0|4294967295] "" Vector__XXX
 SG_ VCSEC_Device16Permissions m99 : 32|32@1+ (1,0) [0|4294967295] "" Vector__XXX
 SG_ VCSEC_Device16ManufacturerHashBi m101 : 8|24@1+ (1,0) [0|16777215] "" Vector__XXX
 SG_ VCSEC_Device16BuildNumberHashBit m101 : 32|32@1+ (1,0) [0|4294967295] "" Vector__XXX
 SG_ VCSEC_Device17AuthResponseTime m102 : 7|7@1+ (50,0) [0|6300] "ms" Vector__XXX
 SG_ VCSEC_Device17Impermanent m102 : 14|1@1+ (1,0) [0|1] "" Vector__XXX
 SG_ VCSEC_Device17SELockedDown m102 : 15|1@1+ (1,0) [0|1] "" Vector__XXX
 SG_ VCSEC_Device17Version m102 : 16|16@1+ (1,0) [0|65535] "" Vector__XXX
 SG_ VCSEC_Device17WLEntry m102 : 32|5@1+ (1,0) [0|31] "" Vector__XXX
 SG_ VCSEC_Device17OSVersion m102 : 37|12@1+ (1,0) [0|4095] "" Vector__XXX
 SG_ VCSEC_Device17BatteryLevel m102 : 49|8@1+ (0.015625,0) [0|3.9] "V" Vector__XXX
 SG_ VCSEC_Device17Formfactor m102 : 57|5@1+ (1,0) [0|31] "" Vector__XXX
 SG_ VCSEC_Device17BlacklistStatus m102 : 62|1@1+ (1,0) [0|1] "" Vector__XXX
 SG_ VCSEC_Device17Stationary m102 : 63|1@1+ (1,0) [0|1] "" Vector__XXX
 SG_ VCSEC_Device17Bonded m104 : 8|1@1+ (1,0) [0|1] "" Vector__XXX
 SG_ VCSEC_Device17Role m104 : 9|4@1+ (1,0) [0|15] "" Vector__XXX
 SG_ VCSEC_Device17WhitelistActiveTim m104 : 16|16@1+ (1,0) [0|65535] "mins" Vector__XXX
 SG_ VCSEC_Device17SHA1 m104 : 32|32@1+ (1,0) [0|4294967295] "" Vector__XXX
 SG_ VCSEC_Device17Permissions m105 : 32|32@1+ (1,0) [0|4294967295] "" Vector__XXX
 SG_ VCSEC_Device17ManufacturerHashBi m107 : 8|24@1+ (1,0) [0|16777215] "" Vector__XXX
 SG_ VCSEC_Device17BuildNumberHashBit m107 : 32|32@1+ (1,0) [0|4294967295] "" Vector__XXX
 SG_ VCSEC_Device18AuthResponseTime m108 : 7|7@1+ (50,0) [0|6300] "ms" Vector__XXX
 SG_ VCSEC_Device18Impermanent m108 : 14|1@1+ (1,0) [0|1] "" Vector__XXX
 SG_ VCSEC_Device18SELockedDown m108 : 15|1@1+ (1,0) [0|1] "" Vector__XXX
 SG_ VCSEC_Device18Version m108 : 16|16@1+ (1,0) [0|65535] "" Vector__XXX
 SG_ VCSEC_Device18WLEntry m108 : 32|5@1+ (1,0) [0|31] "" Vector__XXX
 SG_ VCSEC_Device18OSVersion m108 : 37|12@1+ (1,0) [0|4095] "" Vector__XXX
 SG_ VCSEC_Device18BatteryLevel m108 : 49|8@1+ (0.015625,0) [0|3.9] "V" Vector__XXX
 SG_ VCSEC_Device18Formfactor m108 : 57|5@1+ (1,0) [0|31] "" Vector__XXX
 SG_ VCSEC_Device18BlacklistStatus m108 : 62|1@1+ (1,0) [0|1] "" Vector__XXX
 SG_ VCSEC_Device18Stationary m108 : 63|1@1+ (1,0) [0|1] "" Vector__XXX
 SG_ VCSEC_Device18Bonded m110 : 8|1@1+ (1,0) [0|1] "" Vector__XXX
 SG_ VCSEC_Device18Role m110 : 9|4@1+ (1,0) [0|15] "" Vector__XXX
 SG_ VCSEC_Device18WhitelistActiveTim m110 : 16|16@1+ (1,0) [0|65535] "mins" Vector__XXX
 SG_ VCSEC_Device18SHA1 m110 : 32|32@1+ (1,0) [0|4294967295] "" Vector__XXX
 SG_ VCSEC_Device18Permissions m111 : 32|32@1+ (1,0) [0|4294967295] "" Vector__XXX
 SG_ VCSEC_Device18ManufacturerHashBi m113 : 8|24@1+ (1,0) [0|16777215] "" Vector__XXX
 SG_ VCSEC_Device18BuildNumberHashBit m113 : 32|32@1+ (1,0) [0|4294967295] "" Vector__XXX
 SG_ VCSEC_Device19AuthResponseTime m114 : 7|7@1+ (50,0) [0|6300] "ms" Vector__XXX
 SG_ VCSEC_Device19Impermanent m114 : 14|1@1+ (1,0) [0|1] "" Vector__XXX
 SG_ VCSEC_Device19SELockedDown m114 : 15|1@1+ (1,0) [0|1] "" Vector__XXX
 SG_ VCSEC_Device19Version m114 : 16|16@1+ (1,0) [0|65535] "" Vector__XXX
 SG_ VCSEC_Device19WLEntry m114 : 32|5@1+ (1,0) [0|31] "" Vector__XXX
 SG_ VCSEC_Device19OSVersion m114 : 37|12@1+ (1,0) [0|4095] "" Vector__XXX
 SG_ VCSEC_Device19BatteryLevel m114 : 49|8@1+ (0.015625,0) [0|3.9] "V" Vector__XXX
 SG_ VCSEC_Device19Formfactor m114 : 57|5@1+ (1,0) [0|31] "" Vector__XXX
 SG_ VCSEC_Device19BlacklistStatus m114 : 62|1@1+ (1,0) [0|1] "" Vector__XXX
 SG_ VCSEC_Device19Stationary m114 : 63|1@1+ (1,0) [0|1] "" Vector__XXX
 SG_ VCSEC_Device19Bonded m116 : 8|1@1+ (1,0) [0|1] "" Vector__XXX
 SG_ VCSEC_Device19Role m116 : 9|4@1+ (1,0) [0|15] "" Vector__XXX
 SG_ VCSEC_Device19WhitelistActiveTim m116 : 16|16@1+ (1,0) [0|65535] "mins" Vector__XXX
 SG_ VCSEC_Device19SHA1 m116 : 32|32@1+ (1,0) [0|4294967295] "" Vector__XXX
 SG_ VCSEC_Device19Permissions m117 : 32|32@1+ (1,0) [0|4294967295] "" Vector__XXX
 SG_ VCSEC_Device19ManufacturerHashBi m119 : 8|24@1+ (1,0) [0|16777215] "" Vector__XXX
 SG_ VCSEC_Device19BuildNumberHashBit m119 : 32|32@1+ (1,0) [0|4294967295] "" Vector__XXX

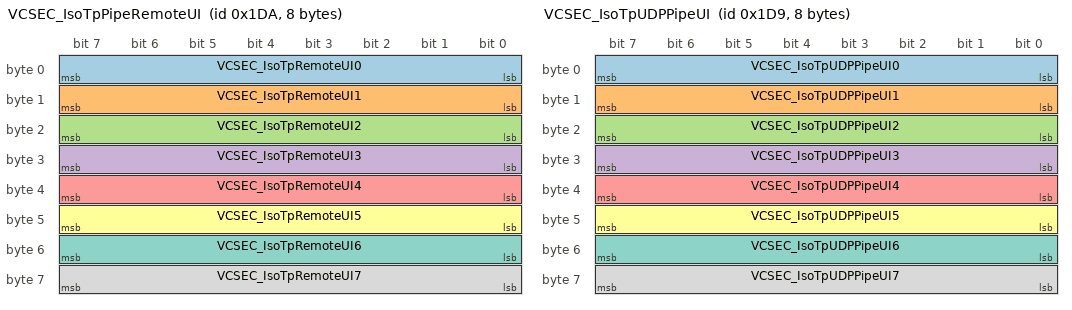
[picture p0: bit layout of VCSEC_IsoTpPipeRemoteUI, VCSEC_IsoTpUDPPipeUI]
BO_ 474 VCSEC_IsoTpPipeRemoteUI: 8 VCSEC
 SG_ VCSEC_IsoTpRemoteUI0 : 0|8@1+ (1,0) [0|255] "" Vector__XXX
 SG_ VCSEC_IsoTpRemoteUI1 : 8|8@1+ (1,0) [0|255] "" Vector__XXX
 SG_ VCSEC_IsoTpRemoteUI2 : 16|8@1+ (1,0) [0|255] "" Vector__XXX
 SG_ VCSEC_IsoTpRemoteUI3 : 24|8@1+ (1,0) [0|255] "" Vector__XXX
 SG_ VCSEC_IsoTpRemoteUI4 : 32|8@1+ (1,0) [0|255] "" Vector__XXX
 SG_ VCSEC_IsoTpRemoteUI5 : 40|8@1+ (1,0) [0|255] "" Vector__XXX
 SG_ VCSEC_IsoTpRemoteUI6 : 48|8@1+ (1,0) [0|255] "" Vector__XXX
 SG_ VCSEC_IsoTpRemoteUI7 : 56|8@1+ (1,0) [0|255] "" Vector__XXX

BO_ 473 VCSEC_IsoTpUDPPipeUI: 8 VCSEC
 SG_ VCSEC_IsoTpUDPPipeUI0 : 0|8@1+ (1,0) [0|255] "" Vector__XXX
 SG_ VCSEC_IsoTpUDPPipeUI1 : 8|8@1+ (1,0) [0|255] "" Vector__XXX
 SG_ VCSEC_IsoTpUDPPipeUI2 : 16|8@1+ (1,0) [0|255] "" Vector__XXX
 SG_ VCSEC_IsoTpUDPPipeUI3 : 24|8@1+ (1,0) [0|255] "" Vector__XXX
 SG_ VCSEC_IsoTpUDPPipeUI4 : 32|8@1+ (1,0) [0|255] "" Vector__XXX
 SG_ VCSEC_IsoTpUDPPipeUI5 : 40|8@1+ (1,0) [0|255] "" Vector__XXX
 SG_ VCSEC_IsoTpUDPPipeUI6 : 48|8@1+ (1,0) [0|255] "" Vector__XXX
 SG_ VCSEC_IsoTpUDPPipeUI7 : 56|8@1+ (1,0) [0|255] "" Vector__XXX

BO_ 1066 VCSEC_TPMSConnectionData: 8 VCSEC
 SG_ VCSEC_TPMSSensorState0 : 0|3@1+ (1,0) [0|7] "" Vector__XXX
 SG_ VCSEC_TPMSRSSI0 : 3|7@1+ (1,-127) [-127|0] "dBm" Vector__XXX
 SG_ VCSEC_TPMSConnectionTypeCurrent0 : 10|2@1+ (1,0) [0|3] "" Vector__XXX
 SG_ VCSEC_TPMSConnectionTypeDesired0 : 12|2@1+ (1,0) [0|3] "" Vector__XXX
 SG_ VCSEC_TPMSSensorState1 : 14|3@1+ (1,0) [0|7] "" Vector__XXX
 SG_ VCSEC_TPMSRSSI1 : 17|7@1+ (1,-127) [-127|0] "dBm" Vector__XXX
 SG_ VCSEC_TPMSConnectionTypeCurrent1 : 24|2@1+ (1,0) [0|3] "" Vector__XXX
 SG_ VCSEC_TPMSConnectionTypeDesired1 : 26|2@1+ (1,0) [0|3] "" Vector__XXX
 SG_ VCSEC_TPMSSensorState2 : 28|3@1+ (1,0) [0|7] "" Vector__XXX
 SG_ VCSEC_TPMSRSSI2 : 31|7@1+ (1,-127) [-127|0] "dBm" Vector__XXX
 SG_ VCSEC_TPMSConnectionTypeCurrent2 : 38|2@1+ (1,0) [0|3] "" Vector__XXX
 SG_ VCSEC_TPMSConnectionTypeDesired2 : 40|2@1+ (1,0) [0|3] "" Vector__XXX
 SG_ VCSEC_TPMSSensorState3 : 42|3@1+ (1,0) [0|7] "" Vector__XXX
 SG_ VCSEC_TPMSRSSI3 : 45|7@1+ (1,-127) [-127|0] "dBm" Vector__XXX
 SG_ VCSEC_TPMSConnectionTypeCurrent3 : 52|2@1+ (1,0) [0|3] "" Vector__XXX
 SG_ VCSEC_TPMSConnectionTypeDesired3 : 54|2@1+ (1,0) [0|3] "" Vector__XXX
 SG_ VCSEC_TPMSSensorPresence0 : 56|2@1+ (1,0) [0|3] "" Vector__XXX
 SG_ VCSEC_TPMSSensorPresence1 : 58|2@1+ (1,0) [0|3] "" Vector__XXX
 SG_ VCSEC_TPMSSensorPresence2 : 60|2@1+ (1,0) [0|3] "" Vector__XXX
 SG_ VCSEC_TPMSSensorPresence3 : 62|2@1+ (1,0) [0|3] "" Vector__XXX

BO_ 537 VCSEC_TPMSData: 8 VCSEC
 SG_ VCSEC_TPMSDataIndex M : 0|3@1+ (1,0) [0|7] "" Vector__XXX
 SG_ VCSEC_TPMSCapabilityPressureInAd m0 : 3|1@1+ (1,0) [0|1] "" Vector__XXX
 SG_ VCSEC_TPMSCapabilityConfigurable m0 : 4|1@1+ (1,0) [0|1] "" Vector__XXX
 SG_ VCSEC_TPMSPressureRateOfChange0 m0 : 5|10@1- (0.02,0) [-10.24|10.22] "kPa/S" Vector__XXX
 SG_ VCSEC_TPMSPressure0 m0 : 15|9@1+ (0.025,0) [0|12.75] "bar" Vector__XXX
 SG_ VCSEC_TPMSTemperature0 m0 : 24|8@1+ (1,-40) [-40|214] "degC" Vector__XXX
 SG_ VCSEC_TPMSBatVoltage0 m0 : 32|8@1+ (0.01,1.5) [1.5|4.04] "V" Vector__XXX
 SG_ VCSEC_TPMSLocation0 m0 : 40|3@1+ (1,0) [0|7] "" Vector__XXX
 SG_ VCSEC_TPMSTemperatureCompensated m0 : 43|9@1+ (0.025,0) [0|12.75] "bar" Vector__XXX
 SG_ VCSEC_TPMSCapabilityPressur_0001 m1 : 3|1@1+ (1,0) [0|1] "" Vector__XXX
 SG_ VCSEC_TPMSCapabilityConfigu_0001 m1 : 4|1@1+ (1,0) [0|1] "" Vector__XXX
 SG_ VCSEC_TPMSPressureRateOfChange1 m1 : 5|10@1- (0.02,0) [-10.24|10.22] "kPa/S" Vector__XXX
 SG_ VCSEC_TPMSPressure1 m1 : 15|9@1+ (0.025,0) [0|12.75] "bar" Vector__XXX
 SG_ VCSEC_TPMSTemperature1 m1 : 24|8@1+ (1,-40) [-40|214] "degC" Vector__XXX
 SG_ VCSEC_TPMSBatVoltage1 m1 : 32|8@1+ (0.01,1.5) [1.5|4.04] "V" Vector__XXX
 SG_ VCSEC_TPMSLocation1 m1 : 40|3@1+ (1,0) [0|7] "" Vector__XXX
 SG_ VCSEC_TPMSTemperatureCompen_0001 m1 : 43|9@1+ (0.025,0) [0|12.75] "bar" Vector__XXX
 SG_ VCSEC_TPMSCapabilityPressur_0002 m2 : 3|1@1+ (1,0) [0|1] "" Vector__XXX
 SG_ VCSEC_TPMSCapabilityConfigu_0002 m2 : 4|1@1+ (1,0) [0|1] "" Vector__XXX
 SG_ VCSEC_TPMSPressureRateOfChange2 m2 : 5|10@1- (0.02,0) [-10.24|10.22] "kPa/S" Vector__XXX
 SG_ VCSEC_TPMSPressure2 m2 : 15|9@1+ (0.025,0) [0|12.75] "bar" Vector__XXX
 SG_ VCSEC_TPMSTemperature2 m2 : 24|8@1+ (1,-40) [-40|214] "degC" Vector__XXX
 SG_ VCSEC_TPMSBatVoltage2 m2 : 32|8@1+ (0.01,1.5) [1.5|4.04] "V" Vector__XXX
 SG_ VCSEC_TPMSLocation2 m2 : 40|3@1+ (1,0) [0|7] "" Vector__XXX
 SG_ VCSEC_TPMSTemperatureCompen_0002 m2 : 43|9@1+ (0.025,0) [0|12.75] "bar" Vector__XXX
 SG_ VCSEC_TPMSCapabilityPressur_0003 m3 : 3|1@1+ (1,0) [0|1] "" Vector__XXX
 SG_ VCSEC_TPMSCapabilityConfigu_0003 m3 : 4|1@1+ (1,0) [0|1] "" Vector__XXX
 SG_ VCSEC_TPMSPressureRateOfChange3 m3 : 5|10@1- (0.02,0) [-10.24|10.22] "kPa/S" Vector__XXX
 SG_ VCSEC_TPMSPressure3 m3 : 15|9@1+ (0.025,0) [0|12.75] "bar" Vector__XXX
 SG_ VCSEC_TPMSTemperature3 m3 : 24|8@1+ (1,-40) [-40|214] "degC" Vector__XXX
 SG_ VCSEC_TPMSBatVoltage3 m3 : 32|8@1+ (0.01,1.5) [1.5|4.04] "V" Vector__XXX
 SG_ VCSEC_TPMSLocation3 m3 : 40|3@1+ (1,0) [0|7] "" Vector__XXX
 SG_ VCSEC_TPMSTemperatureCompen_0003 m3 : 43|9@1+ (0.025,0) [0|12.75] "bar" Vector__XXX
 SG_ VCSEC_TPMSRecommendedColdPressur m4 : 8|8@1+ (0.025,0) [0|6.35] "bar" Vector__XXX
 SG_ VCSEC_TPMSRecommendedColdPr_0001 m4 : 16|8@1+ (0.025,0) [0|6.35] "bar" Vector__XXX
 SG_ VCSEC_TPMSFeature0 m4 : 24|3@1+ (1,0) [0|7] "" Vector__XXX
 SG_ VCSEC_TPMSFeature1 m4 : 27|3@1+ (1,0) [0|7] "" Vector__XXX
 SG_ VCSEC_TPMSFeature0Count m4 : 32|4@1+ (1,0) [0|15] "" Vector__XXX
 SG_ VCSEC_TPMSFeature0TimeS m4 : 36|11@1+ (1,0) [0|2047] "" Vector__XXX

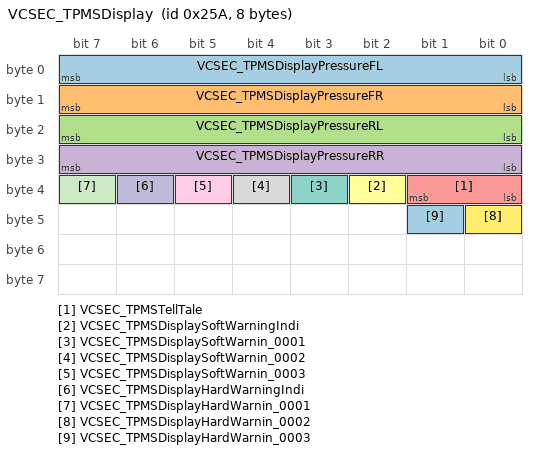
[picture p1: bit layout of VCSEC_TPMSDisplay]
BO_ 602 VCSEC_TPMSDisplay: 8 VCSEC
 SG_ VCSEC_TPMSDisplayPressureFL : 0|8@1+ (0.025,0) [0|6.35] "bar" Vector__XXX
 SG_ VCSEC_TPMSDisplayPressureFR : 8|8@1+ (0.025,0) [0|6.35] "bar" Vector__XXX
 SG_ VCSEC_TPMSDisplayPressureRL : 16|8@1+ (0.025,0) [0|6.35] "bar" Vector__XXX
 SG_ VCSEC_TPMSDisplayPressureRR : 24|8@1+ (0.025,0) [0|6.35] "bar" Vector__XXX
 SG_ VCSEC_TPMSTellTale : 32|2@1+ (1,0) [0|3] "" Vector__XXX
 SG_ VCSEC_TPMSDisplaySoftWarningIndi : 34|1@1+ (1,0) [0|1] "" Vector__XXX
 SG_ VCSEC_TPMSDisplaySoftWarnin_0001 : 35|1@1+ (1,0) [0|1] "" Vector__XXX
 SG_ VCSEC_TPMSDisplaySoftWarnin_0002 : 36|1@1+ (1,0) [0|1] "" Vector__XXX
 SG_ VCSEC_TPMSDisplaySoftWarnin_0003 : 37|1@1+ (1,0) [0|1] "" Vector__XXX
 SG_ VCSEC_TPMSDisplayHardWarningIndi : 38|1@1+ (1,0) [0|1] "" Vector__XXX
 SG_ VCSEC_TPMSDisplayHardWarnin_0001 : 39|1@1+ (1,0) [0|1] "" Vector__XXX
 SG_ VCSEC_TPMSDisplayHardWarnin_0002 : 40|1@1+ (1,0) [0|1] "" Vector__XXX
 SG_ VCSEC_TPMSDisplayHardWarnin_0003 : 41|1@1+ (1,0) [0|1] "" Vector__XXX

BO_ 570 VCSEC_TPMSStatus: 8 VCSEC
 SG_ VCSEC_TPMSStatusIndex M : 0|5@1+ (1,0) [0|31] "" Vector__XXX
 SG_ VCSEC_TPMSSystemState : 5|1@1+ (1,0) [0|1] "" Vector__XXX
 SG_ VCSEC_TPMSSensorMACAddress0 m0 : 8|48@1+ (1,0) [0|281474976710655] "" Vector__XXX
 SG_ VCSEC_TPMSSensorMACAddress1 m1 : 8|48@1+ (1,0) [0|281474976710655] "" Vector__XXX
 SG_ VCSEC_TPMSSensorMACAddress2 m2 : 8|48@1+ (1,0) [0|281474976710655] "" Vector__XXX
 SG_ VCSEC_TPMSSensorMACAddress3 m3 : 8|48@1+ (1,0) [0|281474976710655] "" Vector__XXX
 SG_ VCSEC_BLESuccessfulConnEventCoun m4 : 6|15@1+ (1,0) [0|32767] "" Vector__XXX
 SG_ VCSEC_BLEMissedConnEventCount0 m4 : 21|14@1+ (1,0) [0|16383] "" Vector__XXX
 SG_ VCSEC_BLECRCErrorConnEventCount0 m4 : 35|14@1+ (1,0) [0|16383] "" Vector__XXX
 SG_ VCSEC_BLEOtherFailuresCount0 m4 : 49|5@1+ (1,0) [0|31] "" Vector__XXX
 SG_ VCSEC_BLEUnsuccessfulConnEventRa m4 : 54|10@1+ (0.08,0) [0|81.76] "%" Vector__XXX
 SG_ VCSEC_BLESuccessfulConnEven_0001 m5 : 6|15@1+ (1,0) [0|32767] "" Vector__XXX
 SG_ VCSEC_BLEMissedConnEventCount1 m5 : 21|14@1+ (1,0) [0|16383] "" Vector__XXX
 SG_ VCSEC_BLECRCErrorConnEventCount1 m5 : 35|14@1+ (1,0) [0|16383] "" Vector__XXX
 SG_ VCSEC_BLEOtherFailuresCount1 m5 : 49|5@1+ (1,0) [0|31] "" Vector__XXX
 SG_ VCSEC_BLEUnsuccessfulConnEv_0001 m5 : 54|10@1+ (0.08,0) [0|81.76] "%" Vector__XXX
 SG_ VCSEC_BLESuccessfulConnEven_0002 m6 : 6|15@1+ (1,0) [0|32767] "" Vector__XXX
 SG_ VCSEC_BLEMissedConnEventCount2 m6 : 21|14@1+ (1,0) [0|16383] "" Vector__XXX
 SG_ VCSEC_BLECRCErrorConnEventCount2 m6 : 35|14@1+ (1,0) [0|16383] "" Vector__XXX
 SG_ VCSEC_BLEOtherFailuresCount2 m6 : 49|5@1+ (1,0) [0|31] "" Vector__XXX
 SG_ VCSEC_BLEUnsuccessfulConnEv_0002 m6 : 54|10@1+ (0.08,0) [0|81.76] "%" Vector__XXX
 SG_ VCSEC_BLESuccessfulConnEven_0003 m7 : 6|15@1+ (1,0) [0|32767] "" Vector__XXX
 SG_ VCSEC_BLEMissedConnEventCount3 m7 : 21|14@1+ (1,0) [0|16383] "" Vector__XXX
 SG_ VCSEC_BLECRCErrorConnEventCount3 m7 : 35|14@1+ (1,0) [0|16383] "" Vector__XXX
 SG_ VCSEC_BLEOtherFailuresCount3 m7 : 49|5@1+ (1,0) [0|31] "" Vector__XXX
 SG_ VCSEC_BLEUnsuccessfulConnEv_0003 m7 : 54|10@1+ (0.08,0) [0|81.76] "%" Vector__XXX
 SG_ VCSEC_TPMSSensorTIAppCRC0 m8 : 8|32@1+ (1,0) [0|4294967295] "" Vector__XXX
 SG_ VCSEC_TPMSSensorMLXAppCRC0 m8 : 40|24@1+ (1,0) [0|16777215] "" Vector__XXX
 SG_ VCSEC_TPMSSensorTIAppCRC1 m9 : 8|32@1+ (1,0) [0|4294967295] "" Vector__XXX
 SG_ VCSEC_TPMSSensorMLXAppCRC1 m9 : 40|24@1+ (1,0) [0|16777215] "" Vector__XXX
 SG_ VCSEC_TPMSSensorTIAppCRC2 m10 : 8|32@1+ (1,0) [0|4294967295] "" Vector__XXX
 SG_ VCSEC_TPMSSensorMLXAppCRC2 m10 : 40|24@1+ (1,0) [0|16777215] "" Vector__XXX
 SG_ VCSEC_TPMSSensorTIAppCRC3 m11 : 8|32@1+ (1,0) [0|4294967295] "" Vector__XXX
 SG_ VCSEC_TPMSSensorMLXAppCRC3 m11 : 40|24@1+ (1,0) [0|16777215] "" Vector__XXX
 SG_ VCSEC_TPMStotalAwakeTime0 m16 : 8|32@1+ (1,0) [0|4294967295] "" Vector__XXX
 SG_ VCSEC_TPMSTrimAdjusted0 m16 : 40|1@1+ (1,0) [0|1] "" Vector__XXX
 SG_ VCSEC_TPMSGenealogySensorState0 m16 : 41|3@1+ (1,0) [0|7] "" Vector__XXX
 SG_ VCSEC_TPMSSensorType0 m16 : 44|3@1+ (1,0) [0|7] "" Vector__XXX
 SG_ VCSEC_TPMStotalAwakeTime1 m17 : 8|32@1+ (1,0) [0|4294967295] "" Vector__XXX
 SG_ VCSEC_TPMSTrimAdjusted1 m17 : 40|1@1+ (1,0) [0|1] "" Vector__XXX
 SG_ VCSEC_TPMSGenealogySensorState1 m17 : 41|3@1+ (1,0) [0|7] "" Vector__XXX
 SG_ VCSEC_TPMSSensorType1 m17 : 44|3@1+ (1,0) [0|7] "" Vector__XXX
 SG_ VCSEC_TPMStotalAwakeTime2 m18 : 8|32@1+ (1,0) [0|4294967295] "" Vector__XXX
 SG_ VCSEC_TPMSTrimAdjusted2 m18 : 40|1@1+ (1,0) [0|1] "" Vector__XXX
 SG_ VCSEC_TPMSGenealogySensorState2 m18 : 41|3@1+ (1,0) [0|7] "" Vector__XXX
 SG_ VCSEC_TPMSSensorType2 m18 : 44|3@1+ (1,0) [0|7] "" Vector__XXX
 SG_ VCSEC_TPMStotalAwakeTime3 m19 : 8|32@1+ (1,0) [0|4294967295] "" Vector__XXX
 SG_ VCSEC_TPMSTrimAdjusted3 m19 : 40|1@1+ (1,0) [0|1] "" Vector__XXX
 SG_ VCSEC_TPMSGenealogySensorState3 m19 : 41|3@1+ (1,0) [0|7] "" Vector__XXX
 SG_ VCSEC_TPMSSensorType3 m19 : 44|3@1+ (1,0) [0|7] "" Vector__XXX

BO_ 1067 VCSEC_UWBData: 8 VCSEC
 SG_ VCSEC_UWBEndpointIndex M : 0|2@1+ (1,0) [0|3] "" Vector__XXX
 SG_ VCSEC_UWBRearRightDistance0 m0 : 2|12@1+ (1,0) [0|4095] "cm" Vector__XXX
 SG_ VCSEC_UWBRearRightDistance1 m0 : 16|12@1+ (1,0) [0|4095] "cm" Vector__XXX
 SG_ VCSEC_UWBRearRightDistance2 m0 : 28|12@1+ (1,0) [0|4095] "cm" Vector__XXX
 SG_ VCSEC_UWBLeftDistance2 m1 : 2|12@1+ (1,0) [0|4095] "cm" Vector__XXX
 SG_ VCSEC_UWBRightDistance2 m1 : 16|12@1+ (1,0) [0|4095] "cm" Vector__XXX
 SG_ VCSEC_UWBRearDistance2 m1 : 28|12@1+ (1,0) [0|4095] "cm" Vector__XXX
 SG_ VCSEC_UWBRearLeftDistance2 m1 : 40|12@1+ (1,0) [0|4095] "cm" Vector__XXX
 SG_ VCSEC_UWBCenterDistance2 m1 : 52|12@1+ (1,0) [0|4095] "cm" Vector__XXX
 SG_ VCSEC_UWBLeftDistance1 m2 : 2|12@1+ (1,0) [0|4095] "cm" Vector__XXX
 SG_ VCSEC_UWBRightDistance1 m2 : 16|12@1+ (1,0) [0|4095] "cm" Vector__XXX
 SG_ VCSEC_UWBRearDistance1 m2 : 28|12@1+ (1,0) [0|4095] "cm" Vector__XXX
 SG_ VCSEC_UWBRearLeftDistance1 m2 : 40|12@1+ (1,0) [0|4095] "cm" Vector__XXX
 SG_ VCSEC_UWBCenterDistance1 m2 : 52|12@1+ (1,0) [0|4095] "cm" Vector__XXX
 SG_ VCSEC_UWBLeftDistance0 m3 : 2|12@1+ (1,0) [0|4095] "cm" Vector__XXX
 SG_ VCSEC_UWBRightDistance0 m3 : 16|12@1+ (1,0) [0|4095] "cm" Vector__XXX
 SG_ VCSEC_UWBRearDistance0 m3 : 28|12@1+ (1,0) [0|4095] "cm" Vector__XXX
 SG_ VCSEC_UWBRearLeftDistance0 m3 : 40|12@1+ (1,0) [0|4095] "cm" Vector__XXX
 SG_ VCSEC_UWBCenterDistance0 m3 : 52|12@1+ (1,0) [0|4095] "cm" Vector__XXX

BO_ 761 VCSEC_additionalAuthInfo: 8 VCSEC
 SG_ VCSEC_activeKeyDebug : 2|5@1+ (1,0) [0|31] "" Vector__XXX
 SG_ VCSEC_bleChannelDisconnected : 7|4@1+ (1,0) [0|15] "" Vector__XXX
 SG_ VCSEC_bleDisconnectionReason : 11|8@1+ (1,0) [0|255] "" Vector__XXX
 SG_ VCSEC_bleConnetionAttemptWLEntry : 19|5@1+ (1,0) [0|31] "" Vector__XXX
 SG_ VCSEC_AdditionalAuthInfoIndex M : 27|3@1+ (1,0) [0|7] "" Vector__XXX
 SG_ VCSEC_unsecureNotificationStatus : 30|2@1+ (1,0) [0|3] "" Vector__XXX
 SG_ VCSEC_activeKeyReason m0 : 24|3@1+ (1,0) [0|7] "" Vector__XXX
 SG_ VCSEC_activeKeySHA1 m0 : 32|32@1+ (1,0) [0|4294967295] "" Vector__XXX
 SG_ VCSEC_algoUsedForSummonRange0 m1 : 0|1@1+ (1,0) [0|1] "" Vector__XXX
 SG_ VCSEC_keyWithinSummonRange0 m1 : 32|32@1+ (1,0) [0|4294967295] "" Vector__XXX
 SG_ VCSEC_algoUsedForSummonRange1 m2 : 0|1@1+ (1,0) [0|1] "" Vector__XXX
 SG_ VCSEC_keyWithinSummonRange1 m2 : 32|32@1+ (1,0) [0|4294967295] "" Vector__XXX
 SG_ VCSEC_algoUsedForSummonRange2 m3 : 0|1@1+ (1,0) [0|1] "" Vector__XXX
 SG_ VCSEC_keyWithinSummonRange2 m3 : 32|32@1+ (1,0) [0|4294967295] "" Vector__XXX
 SG_ VCSEC_BLEDeviceWithinSummonRange m4 : 32|32@1+ (1,0) [0|4294967295] "" Vector__XXX
 SG_ VCSEC_WalkupUnlockMitigationKeyI m5 : 32|5@1+ (1,0) [0|31] "" Vector__XXX
 SG_ VCSEC_WalkupUnlockMitigatio_0003 m5 : 37|5@1+ (1,0) [0|31] "" Vector__XXX
 SG_ VCSEC_WalkupUnlockMitigatio_0004 m5 : 42|5@1+ (1,0) [0|31] "" Vector__XXX
 SG_ VCSEC_WalkupUnlockMitigationDesi m5 : 47|2@1+ (1,0) [0|3] "" Vector__XXX
 SG_ VCSEC_WalkupUnlockMitigationReas m5 : 49|1@1+ (1,0) [0|1] "" Vector__XXX
 SG_ VCSEC_WalkupUnlockMitigatio_0001 m5 : 50|2@1+ (1,0) [0|3] "" Vector__XXX
 SG_ VCSEC_WalkupUnlockMitigatio_0005 m5 : 52|1@1+ (1,0) [0|1] "" Vector__XXX
 SG_ VCSEC_WalkupUnlockMitigatio_0002 m5 : 53|2@1+ (1,0) [0|3] "" Vector__XXX
 SG_ VCSEC_WalkupUnlockMitigatio_0006 m5 : 55|1@1+ (1,0) [0|1] "" Vector__XXX
 SG_ VCSEC_NFCAuthFromBPillarFormFact m5 : 56|3@1+ (1,0) [0|7] "" Vector__XXX
 SG_ VCSEC_NFCAuthFromCenterConsoleFo m5 : 59|3@1+ (1,0) [0|7] "" Vector__XXX

CM_ BO_ 969 "Vehicle security controller message: BLE endpoint info";
CM_ SG_ 969 VCSEC_BLEEndpointInfoIndex "Vehicle security controller: BLE endpoint info index";
CM_ SG_ 969 VCSEC_BLECENTERComponentID "Vehicle security controller: BLECENTER component ID";
CM_ SG_ 969 VCSEC_BLECENTERPcbaID "Vehicle security controller: BLECENTER pcba ID";
CM_ SG_ 969 VCSEC_BLECENTERAssemblyID "Vehicle security controller: BLECENTER assembly ID";
CM_ SG_ 969 VCSEC_BLECENTERUsageID "Vehicle security controller: BLECENTER usage ID";
CM_ SG_ 969 VCSEC_BLECENTERCrc "Vehicle security controller: BLECENTER crc";
CM_ SG_ 969 VCSEC_BLELEFTAppGitHashByte "Vehicle security controller: BLELEFT app git hash byte";
CM_ SG_ 969 VCSEC_BLELEFTComponentID "Vehicle security controller: BLELEFT component ID";
CM_ SG_ 969 VCSEC_BLELEFTPcbaID "Vehicle security controller: BLELEFT pcba ID";
CM_ SG_ 969 VCSEC_BLELEFTAssemblyID "Vehicle security controller: BLELEFT assembly ID";
CM_ SG_ 969 VCSEC_BLELEFTUsageID "Vehicle security controller: BLELEFT usage ID";
CM_ SG_ 969 VCSEC_BLELEFTCrc "Vehicle security controller: BLELEFT crc";
CM_ SG_ 969 VCSEC_BLERIGHTAppGitHashByte "Vehicle security controller: BLERIGHT app git hash byte";
CM_ SG_ 969 VCSEC_BLERIGHTComponentID "Vehicle security controller: BLERIGHT component ID";
CM_ SG_ 969 VCSEC_BLERIGHTPcbaID "Vehicle security controller: BLERIGHT pcba ID";
CM_ SG_ 969 VCSEC_BLERIGHTAssemblyID "Vehicle security controller: BLERIGHT assembly ID";
CM_ SG_ 969 VCSEC_BLERIGHTUsageID "Vehicle security controller: BLERIGHT usage ID";
CM_ SG_ 969 VCSEC_BLERIGHTCrc "Vehicle security controller: BLERIGHT crc";
CM_ SG_ 969 VCSEC_BLEREARAppGitHashByte "Vehicle security controller: BLEREAR app git hash byte";
CM_ SG_ 969 VCSEC_BLEREARComponentID "Vehicle security controller: BLEREAR component ID";
CM_ SG_ 969 VCSEC_BLEREARPcbaID "Vehicle security controller: BLEREAR pcba ID";
CM_ SG_ 969 VCSEC_BLEREARAssemblyID "Vehicle security controller: BLEREAR assembly ID";
CM_ SG_ 969 VCSEC_BLEREARUsageID "Vehicle security controller: BLEREAR usage ID";
CM_ SG_ 969 VCSEC_BLEREARCrc "Vehicle security controller: BLEREAR crc";
CM_ SG_ 969 VCSEC_UWBRightCrc "Vehicle security controller: UWB right crc";
CM_ SG_ 969 VCSEC_UWBRightRadioConfigState "Vehicle security controller: UWB right radio config state";
CM_ SG_ 969 VCSEC_UWBRightUpdateStatus "Vehicle security controller: UWB right update status";
CM_ SG_ 969 VCSEC_UWBRightRetryLimitReached "Vehicle security controller: UWB right retry limit reached";
CM_ SG_ 969 VCSEC_UWBRightDspVersion "Vehicle security controller: UWB right dsp version";
CM_ SG_ 969 VCSEC_UWBRightComponentID "Vehicle security controller: UWB right component ID";
CM_ SG_ 969 VCSEC_UWBRightPcbaID "Vehicle security controller: UWB right pcba ID";
CM_ SG_ 969 VCSEC_UWBRightAssemblyID "Vehicle security controller: UWB right assembly ID";
CM_ SG_ 969 VCSEC_UWBRightUsageID "Vehicle security controller: UWB right usage ID";
CM_ SG_ 969 VCSEC_UWBRearRightCrc "Vehicle security controller: UWB rear right crc";
CM_ SG_ 969 VCSEC_UWBRearRightRadioConfigSta "Vehicle security controller: UWB rear right radio config state";
CM_ SG_ 969 VCSEC_UWBRearRightUpdateStatus "Vehicle security controller: UWB rear right update status";
CM_ SG_ 969 VCSEC_UWBRearRightRetryLimitReac "Vehicle security controller: UWB rear right retry limit reached";
CM_ SG_ 969 VCSEC_UWBRearRightDspVersion "Vehicle security controller: UWB rear right dsp version";
CM_ SG_ 969 VCSEC_UWBRearRightComponentID "Vehicle security controller: UWB rear right component ID";
CM_ SG_ 969 VCSEC_UWBRearRightPcbaID "Vehicle security controller: UWB rear right pcba ID";
CM_ SG_ 969 VCSEC_UWBRearRightAssemblyID "Vehicle security controller: UWB rear right assembly ID";
CM_ SG_ 969 VCSEC_UWBRearRightUsageID "Vehicle security controller: UWB rear right usage ID";
CM_ SG_ 969 VCSEC_UWBRearLeftCrc "Vehicle security controller: UWB rear left crc";
CM_ SG_ 969 VCSEC_UWBRearLeftRadioConfigStat "Vehicle security controller: UWB rear left radio config state";
CM_ SG_ 969 VCSEC_UWBRearLeftUpdateStatus "Vehicle security controller: UWB rear left update status";
CM_ SG_ 969 VCSEC_UWBRearLeftRetryLimitReach "Vehicle security controller: UWB rear left retry limit reached";
CM_ SG_ 969 VCSEC_UWBRearLeftDspVersion "Vehicle security controller: UWB rear left dsp version";
CM_ SG_ 969 VCSEC_UWBRearLeftComponentID "Vehicle security controller: UWB rear left component ID";
CM_ SG_ 969 VCSEC_UWBRearLeftPcbaID "Vehicle security controller: UWB rear left pcba ID";
CM_ SG_ 969 VCSEC_UWBRearLeftAssemblyID "Vehicle security controller: UWB rear left assembly ID";
CM_ SG_ 969 VCSEC_UWBRearLeftUsageID "Vehicle security controller: UWB rear left usage ID";
CM_ SG_ 969 VCSEC_UWBRearCrc "Vehicle security controller: UWB rear crc";
CM_ SG_ 969 VCSEC_UWBRearRadioConfigState "Vehicle security controller: UWB rear radio config state";
CM_ SG_ 969 VCSEC_UWBRearUpdateStatus "Vehicle security controller: UWB rear update status";
CM_ SG_ 969 VCSEC_UWBRearRetryLimitReached "Vehicle security controller: UWB rear retry limit reached";
CM_ SG_ 969 VCSEC_UWBRearDspVersion "Vehicle security controller: UWB rear dsp version";
CM_ SG_ 969 VCSEC_UWBRearComponentID "Vehicle security controller: UWB rear component ID";
CM_ SG_ 969 VCSEC_UWBRearPcbaID "Vehicle security controller: UWB rear pcba ID";
CM_ SG_ 969 VCSEC_UWBRearAssemblyID "Vehicle security controller: UWB rear assembly ID";
CM_ SG_ 969 VCSEC_UWBRearUsageID "Vehicle security controller: UWB rear usage ID";
CM_ SG_ 969 VCSEC_UWBLeftCrc "Vehicle security controller: UWB left crc";
CM_ SG_ 969 VCSEC_UWBLeftRadioConfigState "Vehicle security controller: UWB left radio config state";
CM_ SG_ 969 VCSEC_UWBLeftUpdateStatus "Vehicle security controller: UWB left update status";
CM_ SG_ 969 VCSEC_UWBLeftRetryLimitReached "Vehicle security controller: UWB left retry limit reached";
CM_ SG_ 969 VCSEC_UWBLeftDspVersion "Vehicle security controller: UWB left dsp version";
CM_ SG_ 969 VCSEC_UWBLeftComponentID "Vehicle security controller: UWB left component ID";
CM_ SG_ 969 VCSEC_UWBLeftPcbaID "Vehicle security controller: UWB left pcba ID";
CM_ SG_ 969 VCSEC_UWBLeftAssemblyID "Vehicle security controller: UWB left assembly ID";
CM_ SG_ 969 VCSEC_UWBLeftUsageID "Vehicle security controller: UWB left usage ID";
CM_ SG_ 969 VCSEC_UWBCenterCrc "Vehicle security controller: UWB center crc";
CM_ SG_ 969 VCSEC_UWBCenterRadioConfigState "Vehicle security controller: UWB center radio config state";
CM_ SG_ 969 VCSEC_UWBCenterUpdateStatus "Vehicle security controller: UWB center update status";
CM_ SG_ 969 VCSEC_UWBCenterRetryLimitReached "Vehicle security controller: UWB center retry limit reached";
CM_ SG_ 969 VCSEC_UWBCenterDspVersion "Vehicle security controller: UWB center dsp version";
CM_ SG_ 969 VCSEC_UWBCenterComponentID "Vehicle security controller: UWB center component ID";
CM_ SG_ 969 VCSEC_UWBCenterPcbaID "Vehicle security controller: UWB center pcba ID";
CM_ SG_ 969 VCSEC_UWBCenterAssemblyID "Vehicle security controller: UWB center assembly ID";
CM_ SG_ 969 VCSEC_UWBCenterUsageID "Vehicle security controller: UWB center usage ID";
CM_ SG_ 969 VCSEC_BLERIGHTREARCrc "Vehicle security controller: BLERIGHTREAR crc";
CM_ SG_ 969 VCSEC_BLERIGHTREARComponentID "Vehicle security controller: BLERIGHTREAR component ID";
CM_ SG_ 969 VCSEC_BLERIGHTREARPcbaID "Vehicle security controller: BLERIGHTREAR pcba ID";
CM_ SG_ 969 VCSEC_BLERIGHTREARAssemblyID "Vehicle security controller: BLERIGHTREAR assembly ID";
CM_ SG_ 969 VCSEC_BLERIGHTREARUsageID "Vehicle security controller: BLERIGHTREAR usage ID";
CM_ SG_ 969 VCSEC_BLENFCCRADLECrc "Vehicle security controller: BLENFCCRADLE crc";
CM_ SG_ 969 VCSEC_BLENFCCRADLEComponentID "Vehicle security controller: BLENFCCRADLE component ID";
CM_ SG_ 969 VCSEC_BLENFCCRADLEPcbaID "Vehicle security controller: BLENFCCRADLE pcba ID";
CM_ SG_ 969 VCSEC_BLENFCCRADLEAssemblyID "Vehicle security controller: BLENFCCRADLE assembly ID";
CM_ SG_ 969 VCSEC_BLENFCCRADLEUsageID "Vehicle security controller: BLENFCCRADLE usage ID";
CM_ SG_ 969 VCSEC_BLELEFTREARCrc "Vehicle security controller: BLELEFTREAR crc";
CM_ SG_ 969 VCSEC_BLELEFTREARComponentID "Vehicle security controller: BLELEFTREAR component ID";
CM_ SG_ 969 VCSEC_BLELEFTREARPcbaID "Vehicle security controller: BLELEFTREAR pcba ID";
CM_ SG_ 969 VCSEC_BLELEFTREARAssemblyID "Vehicle security controller: BLELEFTREAR assembly ID";
CM_ SG_ 969 VCSEC_BLELEFTREARUsageID "Vehicle security controller: BLELEFTREAR usage ID";
CM_ BO_ 607 "Vehicle security controller message: child seat status";
CM_ SG_ 607 VCSEC_childSeat0_connectionState "Vehicle security controller: child seat0 connection state";
CM_ SG_ 607 VCSEC_childSeat0_taskDisconnecti "Vehicle security controller: child seat0 task disconnection reason";
CM_ SG_ 607 VCSEC_childSeat0_state "Vehicle security controller: child seat0 state";
CM_ SG_ 607 VCSEC_childSeat0_taskErrorCode "Vehicle security controller: child seat0 task error code";
CM_ SG_ 607 VCSEC_childSeat0_RSSI "Vehicle security controller: child seat0 RSSI";
CM_ SG_ 607 VCSEC_childSeat0_ISOFixStatus "Vehicle security controller: child seat0 ISO fix status";
CM_ SG_ 607 VCSEC_childSeat0_buckleStatus "Vehicle security controller: child seat0 buckle status";
CM_ SG_ 607 VCSEC_childSeat0_occupancyStatus "Vehicle security controller: child seat0 occupancy status";
CM_ SG_ 607 VCSEC_childSeat1_connectionState "Vehicle security controller: child seat1 connection state";
CM_ SG_ 607 VCSEC_childSeat1_taskDisconnecti "Vehicle security controller: child seat1 task disconnection reason";
CM_ SG_ 607 VCSEC_childSeat1_state "Vehicle security controller: child seat1 state";
CM_ SG_ 607 VCSEC_childSeat1_taskErrorCode "Vehicle security controller: child seat1 task error code";
CM_ SG_ 607 VCSEC_childSeat1_RSSI "Vehicle security controller: child seat1 RSSI";
CM_ SG_ 607 VCSEC_childSeat1_ISOFixStatus "Vehicle security controller: child seat1 ISO fix status";
CM_ SG_ 607 VCSEC_childSeat1_buckleStatus "Vehicle security controller: child seat1 buckle status";
CM_ SG_ 607 VCSEC_childSeat1_occupancyStatus "Vehicle security controller: child seat1 occupancy status";
CM_ SG_ 607 VCSEC_childPresenceDetectionWarn "Vehicle security controller: child presence detection warning active";
CM_ SG_ 607 VCSEC_childSeatScanStatus "Vehicle security controller: child seat scan status";
CM_ SG_ 607 VCSEC_childPresenceDetectionStat "Vehicle security controller: child presence detection state";
CM_ SG_ 607 VCSEC_childPresenceDetectionSupp "Vehicle security controller: child presence detection support type";
CM_ SG_ 607 VCSEC_childPresenceDetectionNoti "Vehicle security controller: child presence detection notification enabled";
CM_ BO_ 857 "Vehicle security controller message: device status";
CM_ SG_ 857 VCSEC_DeviceStatusIndex "Vehicle security controller: device status index";
CM_ SG_ 857 VCSEC_Device0AuthResponseTime "Slowest response of an authed key";
CM_ SG_ 857 VCSEC_Device0Impermanent "Vehicle security controller: device0 impermanent";
CM_ SG_ 857 VCSEC_Device0SELockedDown "Vehicle security controller: device0 SE locked down";
CM_ SG_ 857 VCSEC_Device0Version "Vehicle security controller: device0 version";
CM_ SG_ 857 VCSEC_Device0WLEntry "White list index of Bluetooth device 0.";
CM_ SG_ 857 VCSEC_Device0OSVersion "Vehicle security controller: device0 OS version";
CM_ SG_ 857 VCSEC_Device0BatteryLevel "Battery voltage of Bluetooth device (Only for Keyfobs)";
CM_ SG_ 857 VCSEC_Device0Formfactor "Form factor device";
CM_ SG_ 857 VCSEC_Device0BlacklistStatus "Vehicle security controller: device0 blacklist status";
CM_ SG_ 857 VCSEC_Device0Stationary "Vehicle security controller: device0 stationary";
CM_ SG_ 857 VCSEC_Device0Bonded "Vehicle security controller: device0 bonded";
CM_ SG_ 857 VCSEC_Device0Role "Vehicle security controller: device0 role";
CM_ SG_ 857 VCSEC_Device0WhitelistActiveTime "Vehicle security controller: device0 whitelist active time";
CM_ SG_ 857 VCSEC_Device0SHA1 "SHA1 of the public key of the device";
CM_ SG_ 857 VCSEC_Device0Permissions "Vehicle security controller: device0 permissions";
CM_ SG_ 857 VCSEC_Device0ManufacturerHashBit "Vehicle security controller: device0 manufacturer hash bits";
CM_ SG_ 857 VCSEC_Device0BuildNumberHashBits "Vehicle security controller: device0 build number hash bits";
CM_ SG_ 857 VCSEC_Device1AuthResponseTime "Slowest response of an authed key";
CM_ SG_ 857 VCSEC_Device1Impermanent "Vehicle security controller: device1 impermanent";
CM_ SG_ 857 VCSEC_Device1SELockedDown "Vehicle security controller: device1 SE locked down";
CM_ SG_ 857 VCSEC_Device1Version "Vehicle security controller: device1 version";
CM_ SG_ 857 VCSEC_Device1WLEntry "White list index of the device";
CM_ SG_ 857 VCSEC_Device1OSVersion "Vehicle security controller: device1 OS version";
CM_ SG_ 857 VCSEC_Device1BatteryLevel "Battery voltage of Bluetooth device (Only for Keyfobs)";
CM_ SG_ 857 VCSEC_Device1Formfactor "Form factor of the device";
CM_ SG_ 857 VCSEC_Device1BlacklistStatus "Vehicle security controller: device1 blacklist status";
CM_ SG_ 857 VCSEC_Device1Stationary "Vehicle security controller: device1 stationary";
CM_ SG_ 857 VCSEC_Device1Bonded "Vehicle security controller: device1 bonded";
CM_ SG_ 857 VCSEC_Device1Role "Vehicle security controller: device1 role";
CM_ SG_ 857 VCSEC_Device1WhitelistActiveTime "Vehicle security controller: device1 whitelist active time";
CM_ SG_ 857 VCSEC_Device1SHA1 "SHA1 of the public key of the device";
CM_ SG_ 857 VCSEC_Device1Permissions "Vehicle security controller: device1 permissions";
CM_ SG_ 857 VCSEC_Device1ManufacturerHashBit "Vehicle security controller: device1 manufacturer hash bits";
CM_ SG_ 857 VCSEC_Device1BuildNumberHashBits "Vehicle security controller: device1 build number hash bits";
CM_ SG_ 857 VCSEC_Device2AuthResponseTime "Slowest response of an authed key";
CM_ SG_ 857 VCSEC_Device2Impermanent "Vehicle security controller: device2 impermanent";
CM_ SG_ 857 VCSEC_Device2SELockedDown "Vehicle security controller: device2 SE locked down";
CM_ SG_ 857 VCSEC_Device2Version "Vehicle security controller: device2 version";
CM_ SG_ 857 VCSEC_Device2WLEntry "White list index of Bluetooth device 2.";
CM_ SG_ 857 VCSEC_Device2OSVersion "Vehicle security controller: device2 OS version";
CM_ SG_ 857 VCSEC_Device2BatteryLevel "Battery voltage of Bluetooth device (Only for Keyfobs)";
CM_ SG_ 857 VCSEC_Device2Formfactor "Form factor of the device";
CM_ SG_ 857 VCSEC_Device2BlacklistStatus "Vehicle security controller: device2 blacklist status";
CM_ SG_ 857 VCSEC_Device2Stationary "Vehicle security controller: device2 stationary";
CM_ SG_ 857 VCSEC_Device2Bonded "Vehicle security controller: device2 bonded";
CM_ SG_ 857 VCSEC_Device2Role "Vehicle security controller: device2 role";
CM_ SG_ 857 VCSEC_Device2WhitelistActiveTime "Vehicle security controller: device2 whitelist active time";
CM_ SG_ 857 VCSEC_Device2SHA1 "SHA1 of the public key of the device";
CM_ SG_ 857 VCSEC_Device2Permissions "Vehicle security controller: device2 permissions";
CM_ SG_ 857 VCSEC_Device2ManufacturerHashBit "Vehicle security controller: device2 manufacturer hash bits";
CM_ SG_ 857 VCSEC_Device2BuildNumberHashBits "Vehicle security controller: device2 build number hash bits";
CM_ SG_ 857 VCSEC_Device3AuthResponseTime "Slowest response of an authed key";
CM_ SG_ 857 VCSEC_Device3Impermanent "Vehicle security controller: device3 impermanent";
CM_ SG_ 857 VCSEC_Device3SELockedDown "Vehicle security controller: device3 SE locked down";
CM_ SG_ 857 VCSEC_Device3Version "Vehicle security controller: device3 version";
CM_ SG_ 857 VCSEC_Device3WLEntry "White list index of the device.";
CM_ SG_ 857 VCSEC_Device3OSVersion "Vehicle security controller: device3 OS version";
CM_ SG_ 857 VCSEC_Device3BatteryLevel "Battery voltage of Bluetooth device (Only for Keyfobs)";
CM_ SG_ 857 VCSEC_Device3Formfactor "Form factor of the device.";
CM_ SG_ 857 VCSEC_Device3BlacklistStatus "Vehicle security controller: device3 blacklist status";
CM_ SG_ 857 VCSEC_Device3Stationary "Vehicle security controller: device3 stationary";
CM_ SG_ 857 VCSEC_Device3Bonded "Vehicle security controller: device3 bonded";
CM_ SG_ 857 VCSEC_Device3Role "Vehicle security controller: device3 role";
CM_ SG_ 857 VCSEC_Device3WhitelistActiveTime "Vehicle security controller: device3 whitelist active time";
CM_ SG_ 857 VCSEC_Device3SHA1 "SHA1 of the public key of the device";
CM_ SG_ 857 VCSEC_Device3Permissions "Vehicle security controller: device3 permissions";
CM_ SG_ 857 VCSEC_Device3ManufacturerHashBit "Vehicle security controller: device3 manufacturer hash bits";
CM_ SG_ 857 VCSEC_Device3BuildNumberHashBits "Vehicle security controller: device3 build number hash bits";
CM_ SG_ 857 VCSEC_Device4AuthResponseTime "Slowest response of an authed key";
CM_ SG_ 857 VCSEC_Device4Impermanent "Vehicle security controller: device4 impermanent";
CM_ SG_ 857 VCSEC_Device4SELockedDown "Vehicle security controller: device4 SE locked down";
CM_ SG_ 857 VCSEC_Device4Version "Vehicle security controller: device4 version";
CM_ SG_ 857 VCSEC_Device4WLEntry "White list index of the device.";
CM_ SG_ 857 VCSEC_Device4OSVersion "Vehicle security controller: device4 OS version";
CM_ SG_ 857 VCSEC_Device4BatteryLevel "Battery voltage of Bluetooth device (Only for Keyfobs)";
CM_ SG_ 857 VCSEC_Device4Formfactor "Form factor of the device.";
CM_ SG_ 857 VCSEC_Device4BlacklistStatus "Vehicle security controller: device4 blacklist status";
CM_ SG_ 857 VCSEC_Device4Stationary "Vehicle security controller: device4 stationary";
CM_ SG_ 857 VCSEC_Device4Bonded "Vehicle security controller: device4 bonded";
CM_ SG_ 857 VCSEC_Device4Role "Vehicle security controller: device4 role";
CM_ SG_ 857 VCSEC_Device4WhitelistActiveTime "Vehicle security controller: device4 whitelist active time";
CM_ SG_ 857 VCSEC_Device4SHA1 "SHA1 of the public key of the device";
CM_ SG_ 857 VCSEC_Device4Permissions "Vehicle security controller: device4 permissions";
CM_ SG_ 857 VCSEC_Device4ManufacturerHashBit "Vehicle security controller: device4 manufacturer hash bits";
CM_ SG_ 857 VCSEC_Device4BuildNumberHashBits "Vehicle security controller: device4 build number hash bits";
CM_ SG_ 857 VCSEC_Device5AuthResponseTime "Slowest response of an authed key";
CM_ SG_ 857 VCSEC_Device5Impermanent "Vehicle security controller: device5 impermanent";
CM_ SG_ 857 VCSEC_Device5SELockedDown "Vehicle security controller: device5 SE locked down";
CM_ SG_ 857 VCSEC_Device5Version "Vehicle security controller: device5 version";
CM_ SG_ 857 VCSEC_Device5WLEntry "White list index of the device.";
CM_ SG_ 857 VCSEC_Device5OSVersion "Vehicle security controller: device5 OS version";
CM_ SG_ 857 VCSEC_Device5BatteryLevel "Battery voltage of Bluetooth device (Only for Keyfobs)";
CM_ SG_ 857 VCSEC_Device5Formfactor "Form factor of the device.";
CM_ SG_ 857 VCSEC_Device5BlacklistStatus "Vehicle security controller: device5 blacklist status";
CM_ SG_ 857 VCSEC_Device5Stationary "Vehicle security controller: device5 stationary";
CM_ SG_ 857 VCSEC_Device5Bonded "Vehicle security controller: device5 bonded";
CM_ SG_ 857 VCSEC_Device5Role "Vehicle security controller: device5 role";
CM_ SG_ 857 VCSEC_Device5WhitelistActiveTime "Vehicle security controller: device5 whitelist active time";
CM_ SG_ 857 VCSEC_Device5SHA1 "SHA1 of the public key of the device";
CM_ SG_ 857 VCSEC_Device5Permissions "Vehicle security controller: device5 permissions";
CM_ SG_ 857 VCSEC_Device5ManufacturerHashBit "Vehicle security controller: device5 manufacturer hash bits";
CM_ SG_ 857 VCSEC_Device5BuildNumberHashBits "Vehicle security controller: device5 build number hash bits";
CM_ SG_ 857 VCSEC_Device6AuthResponseTime "Slowest response of an authed key";
CM_ SG_ 857 VCSEC_Device6Impermanent "Vehicle security controller: device6 impermanent";
CM_ SG_ 857 VCSEC_Device6SELockedDown "Vehicle security controller: device6 SE locked down";
CM_ SG_ 857 VCSEC_Device6Version "Vehicle security controller: device6 version";
CM_ SG_ 857 VCSEC_Device6WLEntry "White list index of the device.";
CM_ SG_ 857 VCSEC_Device6OSVersion "Vehicle security controller: device6 OS version";
CM_ SG_ 857 VCSEC_Device6BatteryLevel "Battery voltage of Bluetooth device (Only for Keyfobs)";
CM_ SG_ 857 VCSEC_Device6Formfactor "Form factor of the device.";
CM_ SG_ 857 VCSEC_Device6BlacklistStatus "Vehicle security controller: device6 blacklist status";
CM_ SG_ 857 VCSEC_Device6Stationary "Vehicle security controller: device6 stationary";
CM_ SG_ 857 VCSEC_Device6Bonded "Vehicle security controller: device6 bonded";
CM_ SG_ 857 VCSEC_Device6Role "Vehicle security controller: device6 role";
CM_ SG_ 857 VCSEC_Device6WhitelistActiveTime "Vehicle security controller: device6 whitelist active time";
CM_ SG_ 857 VCSEC_Device6SHA1 "SHA1 of the public key of the device";
CM_ SG_ 857 VCSEC_Device6Permissions "Vehicle security controller: device6 permissions";
CM_ SG_ 857 VCSEC_Device6ManufacturerHashBit "Vehicle security controller: device6 manufacturer hash bits";
CM_ SG_ 857 VCSEC_Device6BuildNumberHashBits "Vehicle security controller: device6 build number hash bits";
CM_ SG_ 857 VCSEC_Device7AuthResponseTime "Slowest response of an authed key";
CM_ SG_ 857 VCSEC_Device7Impermanent "Vehicle security controller: device7 impermanent";
CM_ SG_ 857 VCSEC_Device7SELockedDown "Vehicle security controller: device7 SE locked down";
CM_ SG_ 857 VCSEC_Device7Version "Vehicle security controller: device7 version";
CM_ SG_ 857 VCSEC_Device7WLEntry "White list index of the device.";
CM_ SG_ 857 VCSEC_Device7OSVersion "Vehicle security controller: device7 OS version";
CM_ SG_ 857 VCSEC_Device7BatteryLevel "Battery voltage of Bluetooth device (Only for Keyfobs)";
CM_ SG_ 857 VCSEC_Device7Formfactor "Form factor of the device.";
CM_ SG_ 857 VCSEC_Device7BlacklistStatus "Vehicle security controller: device7 blacklist status";
CM_ SG_ 857 VCSEC_Device7Stationary "Vehicle security controller: device7 stationary";
CM_ SG_ 857 VCSEC_Device7Bonded "Vehicle security controller: device7 bonded";
CM_ SG_ 857 VCSEC_Device7Role "Vehicle security controller: device7 role";
CM_ SG_ 857 VCSEC_Device7WhitelistActiveTime "Vehicle security controller: device7 whitelist active time";
CM_ SG_ 857 VCSEC_Device7SHA1 "SHA1 of the public key of the device";
CM_ SG_ 857 VCSEC_Device7Permissions "Vehicle security controller: device7 permissions";
CM_ SG_ 857 VCSEC_Device7ManufacturerHashBit "Vehicle security controller: device7 manufacturer hash bits";
CM_ SG_ 857 VCSEC_Device7BuildNumberHashBits "Vehicle security controller: device7 build number hash bits";
CM_ SG_ 857 VCSEC_Device8AuthResponseTime "Slowest response of an authed key";
CM_ SG_ 857 VCSEC_Device8Impermanent "Vehicle security controller: device8 impermanent";
CM_ SG_ 857 VCSEC_Device8SELockedDown "Vehicle security controller: device8 SE locked down";
CM_ SG_ 857 VCSEC_Device8Version "Vehicle security controller: device8 version";
CM_ SG_ 857 VCSEC_Device8WLEntry "White list index of the device.";
CM_ SG_ 857 VCSEC_Device8OSVersion "Vehicle security controller: device8 OS version";
CM_ SG_ 857 VCSEC_Device8BatteryLevel "Battery voltage of Bluetooth device (Only for Keyfobs)";
CM_ SG_ 857 VCSEC_Device8Formfactor "Form factor of the device.";
CM_ SG_ 857 VCSEC_Device8BlacklistStatus "Vehicle security controller: device8 blacklist status";
CM_ SG_ 857 VCSEC_Device8Stationary "Vehicle security controller: device8 stationary";
CM_ SG_ 857 VCSEC_Device8Bonded "Vehicle security controller: device8 bonded";
CM_ SG_ 857 VCSEC_Device8Role "Vehicle security controller: device8 role";
CM_ SG_ 857 VCSEC_Device8WhitelistActiveTime "Vehicle security controller: device8 whitelist active time";
CM_ SG_ 857 VCSEC_Device8SHA1 "SHA1 of the public key of the device";
CM_ SG_ 857 VCSEC_Device8Permissions "Vehicle security controller: device8 permissions";
CM_ SG_ 857 VCSEC_Device8ManufacturerHashBit "Vehicle security controller: device8 manufacturer hash bits";
CM_ SG_ 857 VCSEC_Device8BuildNumberHashBits "Vehicle security controller: device8 build number hash bits";
CM_ SG_ 857 VCSEC_Device9AuthResponseTime "Slowest response of an authed key";
CM_ SG_ 857 VCSEC_Device9Impermanent "Vehicle security controller: device9 impermanent";
CM_ SG_ 857 VCSEC_Device9SELockedDown "Vehicle security controller: device9 SE locked down";
CM_ SG_ 857 VCSEC_Device9Version "Vehicle security controller: device9 version";
CM_ SG_ 857 VCSEC_Device9WLEntry "White list index of the device.";
CM_ SG_ 857 VCSEC_Device9OSVersion "Vehicle security controller: device9 OS version";
CM_ SG_ 857 VCSEC_Device9BatteryLevel "Battery voltage of Bluetooth device (Only for Keyfobs)";
CM_ SG_ 857 VCSEC_Device9Formfactor "Form factor of the device.";
CM_ SG_ 857 VCSEC_Device9BlacklistStatus "Vehicle security controller: device9 blacklist status";
CM_ SG_ 857 VCSEC_Device9Stationary "Vehicle security controller: device9 stationary";
CM_ SG_ 857 VCSEC_Device9Bonded "Vehicle security controller: device9 bonded";
CM_ SG_ 857 VCSEC_Device9Role "Vehicle security controller: device9 role";
CM_ SG_ 857 VCSEC_Device9WhitelistActiveTime "Vehicle security controller: device9 whitelist active time";
CM_ SG_ 857 VCSEC_Device9SHA1 "SHA1 of the public key of the device";
CM_ SG_ 857 VCSEC_Device9Permissions "Vehicle security controller: device9 permissions";
CM_ SG_ 857 VCSEC_Device9ManufacturerHashBit "Vehicle security controller: device9 manufacturer hash bits";
CM_ SG_ 857 VCSEC_Device9BuildNumberHashBits "Vehicle security controller: device9 build number hash bits";
CM_ SG_ 857 VCSEC_Device10AuthResponseTime "Slowest response of an authed key";
CM_ SG_ 857 VCSEC_Device10Impermanent "Vehicle security controller: device10 impermanent";
CM_ SG_ 857 VCSEC_Device10SELockedDown "Vehicle security controller: device10 SE locked down";
CM_ SG_ 857 VCSEC_Device10Version "Vehicle security controller: device10 version";
CM_ SG_ 857 VCSEC_Device10WLEntry "White list index of the device.";
CM_ SG_ 857 VCSEC_Device10OSVersion "Vehicle security controller: device10 OS version";
CM_ SG_ 857 VCSEC_Device10BatteryLevel "Battery voltage of Bluetooth device (Only for Keyfobs)";
CM_ SG_ 857 VCSEC_Device10Formfactor "Form factor of the device.";
CM_ SG_ 857 VCSEC_Device10BlacklistStatus "Vehicle security controller: device10 blacklist status";
CM_ SG_ 857 VCSEC_Device10Stationary "Vehicle security controller: device10 stationary";
CM_ SG_ 857 VCSEC_Device10Bonded "Vehicle security controller: device10 bonded";
CM_ SG_ 857 VCSEC_Device10Role "Vehicle security controller: device10 role";
CM_ SG_ 857 VCSEC_Device10WhitelistActiveTim "Vehicle security controller: device10 whitelist active time";
CM_ SG_ 857 VCSEC_Device10SHA1 "SHA1 of the public key of the device";
CM_ SG_ 857 VCSEC_Device10Permissions "Vehicle security controller: device10 permissions";
CM_ SG_ 857 VCSEC_Device10ManufacturerHashBi "Vehicle security controller: device10 manufacturer hash bits";
CM_ SG_ 857 VCSEC_Device10BuildNumberHashBit "Vehicle security controller: device10 build number hash bits";
CM_ SG_ 857 VCSEC_Device11AuthResponseTime "Slowest response of an authed key";
CM_ SG_ 857 VCSEC_Device11Impermanent "Vehicle security controller: device11 impermanent";
CM_ SG_ 857 VCSEC_Device11SELockedDown "Vehicle security controller: device11 SE locked down";
CM_ SG_ 857 VCSEC_Device11Version "Vehicle security controller: device11 version";
CM_ SG_ 857 VCSEC_Device11WLEntry "White list index of the device.";
CM_ SG_ 857 VCSEC_Device11OSVersion "Vehicle security controller: device11 OS version";
CM_ SG_ 857 VCSEC_Device11BatteryLevel "Battery voltage of Bluetooth device (Only for Keyfobs)";
CM_ SG_ 857 VCSEC_Device11Formfactor "Form factor of the device.";
CM_ SG_ 857 VCSEC_Device11BlacklistStatus "Vehicle security controller: device11 blacklist status";
CM_ SG_ 857 VCSEC_Device11Stationary "Vehicle security controller: device11 stationary";
CM_ SG_ 857 VCSEC_Device11Bonded "Vehicle security controller: device11 bonded";
CM_ SG_ 857 VCSEC_Device11Role "Vehicle security controller: device11 role";
CM_ SG_ 857 VCSEC_Device11WhitelistActiveTim "Vehicle security controller: device11 whitelist active time";
CM_ SG_ 857 VCSEC_Device11SHA1 "SHA1 of the public key of the device";
CM_ SG_ 857 VCSEC_Device11Permissions "Vehicle security controller: device11 permissions";
CM_ SG_ 857 VCSEC_Device11ManufacturerHashBi "Vehicle security controller: device11 manufacturer hash bits";
CM_ SG_ 857 VCSEC_Device11BuildNumberHashBit "Vehicle security controller: device11 build number hash bits";
CM_ SG_ 857 VCSEC_Device12AuthResponseTime "Slowest response of an authed key";
CM_ SG_ 857 VCSEC_Device12Impermanent "Vehicle security controller: device12 impermanent";
CM_ SG_ 857 VCSEC_Device12SELockedDown "Vehicle security controller: device12 SE locked down";
CM_ SG_ 857 VCSEC_Device12Version "Vehicle security controller: device12 version";
CM_ SG_ 857 VCSEC_Device12WLEntry "White list index of the device.";
CM_ SG_ 857 VCSEC_Device12OSVersion "Vehicle security controller: device12 OS version";
CM_ SG_ 857 VCSEC_Device12BatteryLevel "Battery voltage of Bluetooth device (Only for Keyfobs)";
CM_ SG_ 857 VCSEC_Device12Formfactor "Form factor of the device.";
CM_ SG_ 857 VCSEC_Device12BlacklistStatus "Vehicle security controller: device12 blacklist status";
CM_ SG_ 857 VCSEC_Device12Stationary "Vehicle security controller: device12 stationary";
CM_ SG_ 857 VCSEC_Device12Bonded "Vehicle security controller: device12 bonded";
CM_ SG_ 857 VCSEC_Device12Role "Vehicle security controller: device12 role";
CM_ SG_ 857 VCSEC_Device12WhitelistActiveTim "Vehicle security controller: device12 whitelist active time";
CM_ SG_ 857 VCSEC_Device12SHA1 "SHA1 of the public key of the device";
CM_ SG_ 857 VCSEC_Device12Permissions "Vehicle security controller: device12 permissions";
CM_ SG_ 857 VCSEC_Device12ManufacturerHashBi "Vehicle security controller: device12 manufacturer hash bits";
CM_ SG_ 857 VCSEC_Device12BuildNumberHashBit "Vehicle security controller: device12 build number hash bits";
CM_ SG_ 857 VCSEC_Device13AuthResponseTime "Slowest response of an authed key";
CM_ SG_ 857 VCSEC_Device13Impermanent "Vehicle security controller: device13 impermanent";
CM_ SG_ 857 VCSEC_Device13SELockedDown "Vehicle security controller: device13 SE locked down";
CM_ SG_ 857 VCSEC_Device13Version "Vehicle security controller: device13 version";
CM_ SG_ 857 VCSEC_Device13WLEntry "White list index of the device.";
CM_ SG_ 857 VCSEC_Device13OSVersion "Vehicle security controller: device13 OS version";
CM_ SG_ 857 VCSEC_Device13BatteryLevel "Battery voltage of Bluetooth device (Only for Keyfobs)";
CM_ SG_ 857 VCSEC_Device13Formfactor "Form factor of the device.";
CM_ SG_ 857 VCSEC_Device13BlacklistStatus "Vehicle security controller: device13 blacklist status";
CM_ SG_ 857 VCSEC_Device13Stationary "Vehicle security controller: device13 stationary";
CM_ SG_ 857 VCSEC_Device13Bonded "Vehicle security controller: device13 bonded";
CM_ SG_ 857 VCSEC_Device13Role "Vehicle security controller: device13 role";
CM_ SG_ 857 VCSEC_Device13WhitelistActiveTim "Vehicle security controller: device13 whitelist active time";
CM_ SG_ 857 VCSEC_Device13SHA1 "SHA1 of the public key of the device";
CM_ SG_ 857 VCSEC_Device13Permissions "Vehicle security controller: device13 permissions";
CM_ SG_ 857 VCSEC_Device13ManufacturerHashBi "Vehicle security controller: device13 manufacturer hash bits";
CM_ SG_ 857 VCSEC_Device13BuildNumberHashBit "Vehicle security controller: device13 build number hash bits";
CM_ SG_ 857 VCSEC_Device14AuthResponseTime "Slowest response of an authed key";
CM_ SG_ 857 VCSEC_Device14Impermanent "Vehicle security controller: device14 impermanent";
CM_ SG_ 857 VCSEC_Device14SELockedDown "Vehicle security controller: device14 SE locked down";
CM_ SG_ 857 VCSEC_Device14Version "Vehicle security controller: device14 version";
CM_ SG_ 857 VCSEC_Device14WLEntry "White list index of the device.";
CM_ SG_ 857 VCSEC_Device14OSVersion "Vehicle security controller: device14 OS version";
CM_ SG_ 857 VCSEC_Device14BatteryLevel "Battery voltage of Bluetooth device (Only for Keyfobs)";
CM_ SG_ 857 VCSEC_Device14Formfactor "Form factor of the device.";
CM_ SG_ 857 VCSEC_Device14BlacklistStatus "Vehicle security controller: device14 blacklist status";
CM_ SG_ 857 VCSEC_Device14Stationary "Vehicle security controller: device14 stationary";
CM_ SG_ 857 VCSEC_Device14Bonded "Vehicle security controller: device14 bonded";
CM_ SG_ 857 VCSEC_Device14Role "Vehicle security controller: device14 role";
CM_ SG_ 857 VCSEC_Device14WhitelistActiveTim "Vehicle security controller: device14 whitelist active time";
CM_ SG_ 857 VCSEC_Device14SHA1 "SHA1 of the public key of the device";
CM_ SG_ 857 VCSEC_Device14Permissions "Vehicle security controller: device14 permissions";
CM_ SG_ 857 VCSEC_Device14ManufacturerHashBi "Vehicle security controller: device14 manufacturer hash bits";
CM_ SG_ 857 VCSEC_Device14BuildNumberHashBit "Vehicle security controller: device14 build number hash bits";
CM_ SG_ 857 VCSEC_Device15AuthResponseTime "Slowest response of an authed key";
CM_ SG_ 857 VCSEC_Device15Impermanent "Vehicle security controller: device15 impermanent";
CM_ SG_ 857 VCSEC_Device15SELockedDown "Vehicle security controller: device15 SE locked down";
CM_ SG_ 857 VCSEC_Device15Version "Vehicle security controller: device15 version";
CM_ SG_ 857 VCSEC_Device15WLEntry "White list index of the device.";
CM_ SG_ 857 VCSEC_Device15OSVersion "Vehicle security controller: device15 OS version";
CM_ SG_ 857 VCSEC_Device15BatteryLevel "Battery voltage of Bluetooth device (Only for Keyfobs)";
CM_ SG_ 857 VCSEC_Device15Formfactor "Form factor of the device.";
CM_ SG_ 857 VCSEC_Device15BlacklistStatus "Vehicle security controller: device15 blacklist status";
CM_ SG_ 857 VCSEC_Device15Stationary "Vehicle security controller: device15 stationary";
CM_ SG_ 857 VCSEC_Device15Bonded "Vehicle security controller: device15 bonded";
CM_ SG_ 857 VCSEC_Device15Role "Vehicle security controller: device15 role";
CM_ SG_ 857 VCSEC_Device15WhitelistActiveTim "Vehicle security controller: device15 whitelist active time";
CM_ SG_ 857 VCSEC_Device15SHA1 "SHA1 of the public key of the device";
CM_ SG_ 857 VCSEC_Device15Permissions "Vehicle security controller: device15 permissions";
CM_ SG_ 857 VCSEC_Device15ManufacturerHashBi "Vehicle security controller: device15 manufacturer hash bits";
CM_ SG_ 857 VCSEC_Device15BuildNumberHashBit "Vehicle security controller: device15 build number hash bits";
CM_ SG_ 857 VCSEC_Device16AuthResponseTime "Slowest response of an authed key";
CM_ SG_ 857 VCSEC_Device16Impermanent "Vehicle security controller: device16 impermanent";
CM_ SG_ 857 VCSEC_Device16SELockedDown "Vehicle security controller: device16 SE locked down";
CM_ SG_ 857 VCSEC_Device16Version "Vehicle security controller: device16 version";
CM_ SG_ 857 VCSEC_Device16WLEntry "White list index of the device.";
CM_ SG_ 857 VCSEC_Device16OSVersion "Vehicle security controller: device16 OS version";
CM_ SG_ 857 VCSEC_Device16BatteryLevel "Battery voltage of Bluetooth device (Only for Keyfobs)";
CM_ SG_ 857 VCSEC_Device16Formfactor "Form factor of the device.";
CM_ SG_ 857 VCSEC_Device16BlacklistStatus "Vehicle security controller: device16 blacklist status";
CM_ SG_ 857 VCSEC_Device16Stationary "Vehicle security controller: device16 stationary";
CM_ SG_ 857 VCSEC_Device16Bonded "Vehicle security controller: device16 bonded";
CM_ SG_ 857 VCSEC_Device16Role "Vehicle security controller: device16 role";
CM_ SG_ 857 VCSEC_Device16WhitelistActiveTim "Vehicle security controller: device16 whitelist active time";
CM_ SG_ 857 VCSEC_Device16SHA1 "SHA1 of the public key of the device";
CM_ SG_ 857 VCSEC_Device16Permissions "Vehicle security controller: device16 permissions";
CM_ SG_ 857 VCSEC_Device16ManufacturerHashBi "Vehicle security controller: device16 manufacturer hash bits";
CM_ SG_ 857 VCSEC_Device16BuildNumberHashBit "Vehicle security controller: device16 build number hash bits";
CM_ SG_ 857 VCSEC_Device17AuthResponseTime "Slowest response of an authed key";
CM_ SG_ 857 VCSEC_Device17Impermanent "Vehicle security controller: device17 impermanent";
CM_ SG_ 857 VCSEC_Device17SELockedDown "Vehicle security controller: device17 SE locked down";
CM_ SG_ 857 VCSEC_Device17Version "Vehicle security controller: device17 version";
CM_ SG_ 857 VCSEC_Device17WLEntry "White list index of the device.";
CM_ SG_ 857 VCSEC_Device17OSVersion "Vehicle security controller: device17 OS version";
CM_ SG_ 857 VCSEC_Device17BatteryLevel "Battery voltage of Bluetooth device (Only for Keyfobs)";
CM_ SG_ 857 VCSEC_Device17Formfactor "Form factor of the device.";
CM_ SG_ 857 VCSEC_Device17BlacklistStatus "Vehicle security controller: device17 blacklist status";
CM_ SG_ 857 VCSEC_Device17Stationary "Vehicle security controller: device17 stationary";
CM_ SG_ 857 VCSEC_Device17Bonded "Vehicle security controller: device17 bonded";
CM_ SG_ 857 VCSEC_Device17Role "Vehicle security controller: device17 role";
CM_ SG_ 857 VCSEC_Device17WhitelistActiveTim "Vehicle security controller: device17 whitelist active time";
CM_ SG_ 857 VCSEC_Device17SHA1 "SHA1 of the public key of the device";
CM_ SG_ 857 VCSEC_Device17Permissions "Vehicle security controller: device17 permissions";
CM_ SG_ 857 VCSEC_Device17ManufacturerHashBi "Vehicle security controller: device17 manufacturer hash bits";
CM_ SG_ 857 VCSEC_Device17BuildNumberHashBit "Vehicle security controller: device17 build number hash bits";
CM_ SG_ 857 VCSEC_Device18AuthResponseTime "Slowest response of an authed key";
CM_ SG_ 857 VCSEC_Device18Impermanent "Vehicle security controller: device18 impermanent";
CM_ SG_ 857 VCSEC_Device18SELockedDown "Vehicle security controller: device18 SE locked down";
CM_ SG_ 857 VCSEC_Device18Version "Vehicle security controller: device18 version";
CM_ SG_ 857 VCSEC_Device18WLEntry "White list index of the device.";
CM_ SG_ 857 VCSEC_Device18OSVersion "Vehicle security controller: device18 OS version";
CM_ SG_ 857 VCSEC_Device18BatteryLevel "Battery voltage of Bluetooth device (Only for Keyfobs)";
CM_ SG_ 857 VCSEC_Device18Formfactor "Form factor of the device.";
CM_ SG_ 857 VCSEC_Device18BlacklistStatus "Vehicle security controller: device18 blacklist status";
CM_ SG_ 857 VCSEC_Device18Stationary "Vehicle security controller: device18 stationary";
CM_ SG_ 857 VCSEC_Device18Bonded "Vehicle security controller: device18 bonded";
CM_ SG_ 857 VCSEC_Device18Role "Vehicle security controller: device18 role";
CM_ SG_ 857 VCSEC_Device18WhitelistActiveTim "Vehicle security controller: device18 whitelist active time";
CM_ SG_ 857 VCSEC_Device18SHA1 "SHA1 of the public key of the device";
CM_ SG_ 857 VCSEC_Device18Permissions "Vehicle security controller: device18 permissions";
CM_ SG_ 857 VCSEC_Device18ManufacturerHashBi "Vehicle security controller: device18 manufacturer hash bits";
CM_ SG_ 857 VCSEC_Device18BuildNumberHashBit "Vehicle security controller: device18 build number hash bits";
CM_ SG_ 857 VCSEC_Device19AuthResponseTime "Slowest response of an authed key";
CM_ SG_ 857 VCSEC_Device19Impermanent "Vehicle security controller: device19 impermanent";
CM_ SG_ 857 VCSEC_Device19SELockedDown "Vehicle security controller: device19 SE locked down";
CM_ SG_ 857 VCSEC_Device19Version "Vehicle security controller: device19 version";
CM_ SG_ 857 VCSEC_Device19WLEntry "White list index of the device.";
CM_ SG_ 857 VCSEC_Device19OSVersion "Vehicle security controller: device19 OS version";
CM_ SG_ 857 VCSEC_Device19BatteryLevel "Battery voltage of Bluetooth device (Only for Keyfobs)";
CM_ SG_ 857 VCSEC_Device19Formfactor "Form factor of the device.";
CM_ SG_ 857 VCSEC_Device19BlacklistStatus "Vehicle security controller: device19 blacklist status";
CM_ SG_ 857 VCSEC_Device19Stationary "Vehicle security controller: device19 stationary";
CM_ SG_ 857 VCSEC_Device19Bonded "Vehicle security controller: device19 bonded";
CM_ SG_ 857 VCSEC_Device19Role "Vehicle security controller: device19 role";
CM_ SG_ 857 VCSEC_Device19WhitelistActiveTim "Vehicle security controller: device19 whitelist active time";
CM_ SG_ 857 VCSEC_Device19SHA1 "SHA1 of the public key of the device";
CM_ SG_ 857 VCSEC_Device19Permissions "Vehicle security controller: device19 permissions";
CM_ SG_ 857 VCSEC_Device19ManufacturerHashBi "Vehicle security controller: device19 manufacturer hash bits";
CM_ SG_ 857 VCSEC_Device19BuildNumberHashBit "Vehicle security controller: device19 build number hash bits";
CM_ BO_ 474 "Vehicle security controller message: iso tp pipe remote UI";
CM_ SG_ 474 VCSEC_IsoTpRemoteUI0 "Vehicle security controller: iso tp remote UI0";
CM_ SG_ 474 VCSEC_IsoTpRemoteUI1 "Vehicle security controller: iso tp remote UI1";
CM_ SG_ 474 VCSEC_IsoTpRemoteUI2 "Vehicle security controller: iso tp remote UI2";
CM_ SG_ 474 VCSEC_IsoTpRemoteUI3 "Vehicle security controller: iso tp remote UI3";
CM_ SG_ 474 VCSEC_IsoTpRemoteUI4 "Vehicle security controller: iso tp remote UI4";
CM_ SG_ 474 VCSEC_IsoTpRemoteUI5 "Vehicle security controller: iso tp remote UI5";
CM_ SG_ 474 VCSEC_IsoTpRemoteUI6 "Vehicle security controller: iso tp remote UI6";
CM_ SG_ 474 VCSEC_IsoTpRemoteUI7 "Vehicle security controller: iso tp remote UI7";
CM_ BO_ 473 "Vehicle security controller message: iso tp UDP pipe UI";
CM_ SG_ 473 VCSEC_IsoTpUDPPipeUI0 "Vehicle security controller: iso tp UDP pipe UI0";
CM_ SG_ 473 VCSEC_IsoTpUDPPipeUI1 "Vehicle security controller: iso tp UDP pipe UI1";
CM_ SG_ 473 VCSEC_IsoTpUDPPipeUI2 "Vehicle security controller: iso tp UDP pipe UI2";
CM_ SG_ 473 VCSEC_IsoTpUDPPipeUI3 "Vehicle security controller: iso tp UDP pipe UI3";
CM_ SG_ 473 VCSEC_IsoTpUDPPipeUI4 "Vehicle security controller: iso tp UDP pipe UI4";
CM_ SG_ 473 VCSEC_IsoTpUDPPipeUI5 "Vehicle security controller: iso tp UDP pipe UI5";
CM_ SG_ 473 VCSEC_IsoTpUDPPipeUI6 "Vehicle security controller: iso tp UDP pipe UI6";
CM_ SG_ 473 VCSEC_IsoTpUDPPipeUI7 "Vehicle security controller: iso tp UDP pipe UI7";
CM_ BO_ 1066 "Vehicle security controller message: TPMS connection data";
CM_ SG_ 1066 VCSEC_TPMSSensorState0 "Indicates the sensors pairing/connectivity status";
CM_ SG_ 1066 VCSEC_TPMSRSSI0 "Received Signal Strength Index reported by sensor.";
CM_ SG_ 1066 VCSEC_TPMSConnectionTypeCurrent0 "Vehicle security controller: TPMS connection type current0";
CM_ SG_ 1066 VCSEC_TPMSConnectionTypeDesired0 "Vehicle security controller: TPMS connection type desired0";
CM_ SG_ 1066 VCSEC_TPMSSensorState1 "Indicates the sensors pairing/connectivity status";
CM_ SG_ 1066 VCSEC_TPMSRSSI1 "Received Signal Strength Index reported by sensor.";
CM_ SG_ 1066 VCSEC_TPMSConnectionTypeCurrent1 "Vehicle security controller: TPMS connection type current1";
CM_ SG_ 1066 VCSEC_TPMSConnectionTypeDesired1 "Vehicle security controller: TPMS connection type desired1";
CM_ SG_ 1066 VCSEC_TPMSSensorState2 "Indicates the sensors pairing/connectivity status";
CM_ SG_ 1066 VCSEC_TPMSRSSI2 "Received Signal Strength Index reported by sensor.";
CM_ SG_ 1066 VCSEC_TPMSConnectionTypeCurrent2 "Vehicle security controller: TPMS connection type current2";
CM_ SG_ 1066 VCSEC_TPMSConnectionTypeDesired2 "Vehicle security controller: TPMS connection type desired2";
CM_ SG_ 1066 VCSEC_TPMSSensorState3 "Indicates the sensors pairing/connectivity status";
CM_ SG_ 1066 VCSEC_TPMSRSSI3 "Received Signal Strength Index reported by sensor.";
CM_ SG_ 1066 VCSEC_TPMSConnectionTypeCurrent3 "Vehicle security controller: TPMS connection type current3";
CM_ SG_ 1066 VCSEC_TPMSConnectionTypeDesired3 "Vehicle security controller: TPMS connection type desired3";
CM_ SG_ 1066 VCSEC_TPMSSensorPresence0 "Indicates the sensors detection status";
CM_ SG_ 1066 VCSEC_TPMSSensorPresence1 "Indicates the sensors detection status";
CM_ SG_ 1066 VCSEC_TPMSSensorPresence2 "Indicates the sensors detection status";
CM_ SG_ 1066 VCSEC_TPMSSensorPresence3 "Indicates the sensors detection status";
CM_ BO_ 537 "Vehicle security controller message: TPMS data";
CM_ SG_ 537 VCSEC_TPMSDataIndex "Vehicle security controller: TPMS data index";
CM_ SG_ 537 VCSEC_TPMSCapabilityPressureInAd "Vehicle security controller: TPMS capability pressure in adv0";
CM_ SG_ 537 VCSEC_TPMSCapabilityConfigurable "Vehicle security controller: TPMS capability configurable pressure0";
CM_ SG_ 537 VCSEC_TPMSPressureRateOfChange0 "Reports the raw pressure value of TPMS sensor 0.";
CM_ SG_ 537 VCSEC_TPMSPressure0 "Indicates Absolute pressure measured by wheel unit.";
CM_ SG_ 537 VCSEC_TPMSTemperature0 "Indicates temperature in tire.";
CM_ SG_ 537 VCSEC_TPMSBatVoltage0 "Sensor battery voltage.";
CM_ SG_ 537 VCSEC_TPMSLocation0 "Indicates the localization result";
CM_ SG_ 537 VCSEC_TPMSTemperatureCompensated "Indicates Absolute pressure measured by wheel unit.";
CM_ SG_ 537 VCSEC_TPMSCapabilityPressur_0001 "Vehicle security controller: TPMS capability pressure in adv1";
CM_ SG_ 537 VCSEC_TPMSCapabilityConfigu_0001 "Vehicle security controller: TPMS capability configurable pressure1";
CM_ SG_ 537 VCSEC_TPMSPressureRateOfChange1 "Reports the raw pressure value of TPMS sensor 1.";
CM_ SG_ 537 VCSEC_TPMSPressure1 "Indicates Absolute pressure measured by wheel unit.";
CM_ SG_ 537 VCSEC_TPMSTemperature1 "Indicates temperature in tire.";
CM_ SG_ 537 VCSEC_TPMSBatVoltage1 "Sensor battery voltage.";
CM_ SG_ 537 VCSEC_TPMSLocation1 "Indicates the localization result";
CM_ SG_ 537 VCSEC_TPMSTemperatureCompen_0001 "Indicates Absolute pressure measured by wheel unit.";
CM_ SG_ 537 VCSEC_TPMSCapabilityPressur_0002 "Vehicle security controller: TPMS capability pressure in adv2";
CM_ SG_ 537 VCSEC_TPMSCapabilityConfigu_0002 "Vehicle security controller: TPMS capability configurable pressure2";
CM_ SG_ 537 VCSEC_TPMSPressureRateOfChange2 "Reports the raw pressure value of TPMS sensor 2.";
CM_ SG_ 537 VCSEC_TPMSPressure2 "Indicates Absolute pressure measured by wheel unit.";
CM_ SG_ 537 VCSEC_TPMSTemperature2 "Indicates temperature in tire.";
CM_ SG_ 537 VCSEC_TPMSBatVoltage2 "Sensor battery voltage.";
CM_ SG_ 537 VCSEC_TPMSLocation2 "Indicates the localization result";
CM_ SG_ 537 VCSEC_TPMSTemperatureCompen_0002 "Indicates Absolute pressure measured by wheel unit.";
CM_ SG_ 537 VCSEC_TPMSCapabilityPressur_0003 "Vehicle security controller: TPMS capability pressure in adv3";
CM_ SG_ 537 VCSEC_TPMSCapabilityConfigu_0003 "Vehicle security controller: TPMS capability configurable pressure3";
CM_ SG_ 537 VCSEC_TPMSPressureRateOfChange3 "Reports the raw pressure value of TPMS sensor 3.";
CM_ SG_ 537 VCSEC_TPMSPressure3 "Indicates Absolute pressure measured by wheel unit.";
CM_ SG_ 537 VCSEC_TPMSTemperature3 "Indicates temperature in tire.";
CM_ SG_ 537 VCSEC_TPMSBatVoltage3 "Sensor battery voltage.";
CM_ SG_ 537 VCSEC_TPMSLocation3 "Indicates the localization result";
CM_ SG_ 537 VCSEC_TPMSTemperatureCompen_0003 "Indicates Absolute pressure measured by wheel unit.";
CM_ SG_ 537 VCSEC_TPMSRecommendedColdPressur "Indicates Absolute pressure measured by wheel unit.";
CM_ SG_ 537 VCSEC_TPMSRecommendedColdPr_0001 "Indicates Absolute pressure measured by wheel unit.";
CM_ SG_ 537 VCSEC_TPMSFeature0 "Vehicle security controller: TPMS feature0";
CM_ SG_ 537 VCSEC_TPMSFeature1 "Vehicle security controller: TPMS feature1";
CM_ SG_ 537 VCSEC_TPMSFeature0Count "Vehicle security controller: TPMS feature0 count";
CM_ SG_ 537 VCSEC_TPMSFeature0TimeS "Vehicle security controller: TPMS feature0 time s";
CM_ BO_ 602 "Vehicle security controller message: TPMS display";
CM_ SG_ 602 VCSEC_TPMSDisplayPressureFL "Indicates Absolute pressure measured by wheel unit.";
CM_ SG_ 602 VCSEC_TPMSDisplayPressureFR "Indicates Absolute pressure measured by wheel unit.";
CM_ SG_ 602 VCSEC_TPMSDisplayPressureRL "Indicates Absolute pressure measured by wheel unit.";
CM_ SG_ 602 VCSEC_TPMSDisplayPressureRR "Indicates Absolute pressure measured by wheel unit.";
CM_ SG_ 602 VCSEC_TPMSTellTale "TPMS UI telltale status to indicate";
CM_ SG_ 602 VCSEC_TPMSDisplaySoftWarningIndi "UI should indicate soft warning";
CM_ SG_ 602 VCSEC_TPMSDisplaySoftWarnin_0001 "UI should indicate soft warning";
CM_ SG_ 602 VCSEC_TPMSDisplaySoftWarnin_0002 "UI should indicate soft warning";
CM_ SG_ 602 VCSEC_TPMSDisplaySoftWarnin_0003 "UI should indicate soft warning";
CM_ SG_ 602 VCSEC_TPMSDisplayHardWarningIndi "UI should indicate soft warning";
CM_ SG_ 602 VCSEC_TPMSDisplayHardWarnin_0001 "UI should indicate soft warning";
CM_ SG_ 602 VCSEC_TPMSDisplayHardWarnin_0002 "UI should indicate soft warning";
CM_ SG_ 602 VCSEC_TPMSDisplayHardWarnin_0003 "UI should indicate soft warning";
CM_ BO_ 570 "Vehicle security controller message: TPMS status";
CM_ SG_ 570 VCSEC_TPMSStatusIndex "Vehicle security controller: TPMS status index";
CM_ SG_ 570 VCSEC_TPMSSystemState "High level state the TPMS system is in currently";
CM_ SG_ 570 VCSEC_TPMSSensorMACAddress0 "Vehicle security controller: TPMS sensor MAC address0";
CM_ SG_ 570 VCSEC_TPMSSensorMACAddress1 "Vehicle security controller: TPMS sensor MAC address1";
CM_ SG_ 570 VCSEC_TPMSSensorMACAddress2 "Vehicle security controller: TPMS sensor MAC address2";
CM_ SG_ 570 VCSEC_TPMSSensorMACAddress3 "Vehicle security controller: TPMS sensor MAC address3";
CM_ SG_ 570 VCSEC_BLESuccessfulConnEventCoun "Count of successful BLE connection events";
CM_ SG_ 570 VCSEC_BLEMissedConnEventCount0 "Count of missed BLE connection events";
CM_ SG_ 570 VCSEC_BLECRCErrorConnEventCount0 "Count of BLE connection events ended with a CRC error";
CM_ SG_ 570 VCSEC_BLEOtherFailuresCount0 "Count of other radio related failures";
CM_ SG_ 570 VCSEC_BLEUnsuccessfulConnEventRa "Vehicle security controller: BLE unsuccessful conn event rate0";
CM_ SG_ 570 VCSEC_BLESuccessfulConnEven_0001 "Count of successful BLE connection events";
CM_ SG_ 570 VCSEC_BLEMissedConnEventCount1 "Count of missed BLE connection events";
CM_ SG_ 570 VCSEC_BLECRCErrorConnEventCount1 "Count of BLE connection events ended with a CRC error";
CM_ SG_ 570 VCSEC_BLEOtherFailuresCount1 "Count of other radio related failures";
CM_ SG_ 570 VCSEC_BLEUnsuccessfulConnEv_0001 "Vehicle security controller: BLE unsuccessful conn event rate1";
CM_ SG_ 570 VCSEC_BLESuccessfulConnEven_0002 "Count of successful BLE connection events";
CM_ SG_ 570 VCSEC_BLEMissedConnEventCount2 "Count of missed BLE connection events";
CM_ SG_ 570 VCSEC_BLECRCErrorConnEventCount2 "Count of BLE connection events ended with a CRC error";
CM_ SG_ 570 VCSEC_BLEOtherFailuresCount2 "Count of other radio related failures";
CM_ SG_ 570 VCSEC_BLEUnsuccessfulConnEv_0002 "Vehicle security controller: BLE unsuccessful conn event rate2";
CM_ SG_ 570 VCSEC_BLESuccessfulConnEven_0003 "Count of successful BLE connection events";
CM_ SG_ 570 VCSEC_BLEMissedConnEventCount3 "Count of missed BLE connection events";
CM_ SG_ 570 VCSEC_BLECRCErrorConnEventCount3 "Count of BLE connection events ended with a CRC error";
CM_ SG_ 570 VCSEC_BLEOtherFailuresCount3 "Count of other radio related failures";
CM_ SG_ 570 VCSEC_BLEUnsuccessfulConnEv_0003 "Vehicle security controller: BLE unsuccessful conn event rate3";
CM_ SG_ 570 VCSEC_TPMSSensorTIAppCRC0 "Vehicle security controller: TPMS sensor TI app CRC0";
CM_ SG_ 570 VCSEC_TPMSSensorMLXAppCRC0 "Vehicle security controller: TPMS sensor MLX app CRC0";
CM_ SG_ 570 VCSEC_TPMSSensorTIAppCRC1 "Vehicle security controller: TPMS sensor TI app CRC1";
CM_ SG_ 570 VCSEC_TPMSSensorMLXAppCRC1 "Vehicle security controller: TPMS sensor MLX app CRC1";
CM_ SG_ 570 VCSEC_TPMSSensorTIAppCRC2 "Vehicle security controller: TPMS sensor TI app CRC2";
CM_ SG_ 570 VCSEC_TPMSSensorMLXAppCRC2 "Vehicle security controller: TPMS sensor MLX app CRC2";
CM_ SG_ 570 VCSEC_TPMSSensorTIAppCRC3 "Vehicle security controller: TPMS sensor TI app CRC3";
CM_ SG_ 570 VCSEC_TPMSSensorMLXAppCRC3 "Vehicle security controller: TPMS sensor MLX app CRC3";
CM_ SG_ 570 VCSEC_TPMStotalAwakeTime0 "Sleep and CPU time count";
CM_ SG_ 570 VCSEC_TPMSTrimAdjusted0 "Vehicle security controller: TPMS trim adjusted0";
CM_ SG_ 570 VCSEC_TPMSGenealogySensorState0 "TPMS genealogy state";
CM_ SG_ 570 VCSEC_TPMSSensorType0 "Tesla TPMS type";
CM_ SG_ 570 VCSEC_TPMStotalAwakeTime1 "Sleep and CPU time count";
CM_ SG_ 570 VCSEC_TPMSTrimAdjusted1 "Vehicle security controller: TPMS trim adjusted1";
CM_ SG_ 570 VCSEC_TPMSGenealogySensorState1 "TPMS genealogy state";
CM_ SG_ 570 VCSEC_TPMSSensorType1 "Tesla TPMS type";
CM_ SG_ 570 VCSEC_TPMStotalAwakeTime2 "Sleep and CPU time count";
CM_ SG_ 570 VCSEC_TPMSTrimAdjusted2 "Vehicle security controller: TPMS trim adjusted2";
CM_ SG_ 570 VCSEC_TPMSGenealogySensorState2 "TPMS genealogy state";
CM_ SG_ 570 VCSEC_TPMSSensorType2 "Tesla TPMS type";
CM_ SG_ 570 VCSEC_TPMStotalAwakeTime3 "Sleep and CPU time count";
CM_ SG_ 570 VCSEC_TPMSTrimAdjusted3 "Vehicle security controller: TPMS trim adjusted3";
CM_ SG_ 570 VCSEC_TPMSGenealogySensorState3 "TPMS genealogy state";
CM_ SG_ 570 VCSEC_TPMSSensorType3 "Tesla TPMS type";
CM_ BO_ 1067 "Vehicle security controller message: UWB data";
CM_ SG_ 1067 VCSEC_UWBEndpointIndex "Vehicle security controller: UWB endpoint index";
CM_ SG_ 1067 VCSEC_UWBRearRightDistance0 "Reports distance between the customer's phone and the endpoint.";
CM_ SG_ 1067 VCSEC_UWBRearRightDistance1 "Reports distance between the customer's phone and the endpoint.";
CM_ SG_ 1067 VCSEC_UWBRearRightDistance2 "Reports distance between the customer's phone and the endpoint.";
CM_ SG_ 1067 VCSEC_UWBLeftDistance2 "Reports distance between the customer's phone and the endpoint.";
CM_ SG_ 1067 VCSEC_UWBRightDistance2 "Reports distance between the customer's phone and the endpoint.";
CM_ SG_ 1067 VCSEC_UWBRearDistance2 "Reports distance between the customer's phone and the endpoint.";
CM_ SG_ 1067 VCSEC_UWBRearLeftDistance2 "Reports distance between the customer's phone and the endpoint.";
CM_ SG_ 1067 VCSEC_UWBCenterDistance2 "Reports distance between the customer's phone and the endpoint.";
CM_ SG_ 1067 VCSEC_UWBLeftDistance1 "Reports distance between the customer's phone and the endpoint.";
CM_ SG_ 1067 VCSEC_UWBRightDistance1 "Reports distance between the customer's phone and the endpoint.";
CM_ SG_ 1067 VCSEC_UWBRearDistance1 "Reports distance between the customer's phone and the endpoint.";
CM_ SG_ 1067 VCSEC_UWBRearLeftDistance1 "Reports distance between the customer's phone and the endpoint.";
CM_ SG_ 1067 VCSEC_UWBCenterDistance1 "Reports distance between the customer's phone and the endpoint.";
CM_ SG_ 1067 VCSEC_UWBLeftDistance0 "Reports distance between the customer's phone and the endpoint.";
CM_ SG_ 1067 VCSEC_UWBRightDistance0 "Reports distance between the customer's phone and the endpoint.";
CM_ SG_ 1067 VCSEC_UWBRearDistance0 "Reports distance between the customer's phone and the endpoint.";
CM_ SG_ 1067 VCSEC_UWBRearLeftDistance0 "Reports distance between the customer's phone and the endpoint.";
CM_ SG_ 1067 VCSEC_UWBCenterDistance0 "Reports distance between the customer's phone and the endpoint.";
CM_ BO_ 761 "Vehicle security controller message: additional auth info";
CM_ SG_ 761 VCSEC_activeKeyDebug "Vehicle security controller: active key debug";
CM_ SG_ 761 VCSEC_bleChannelDisconnected "Connection between vehicle and the BLE authentication device is interrupted.";
CM_ SG_ 761 VCSEC_bleDisconnectionReason "Reasons of the disconnection between vehicle and BLE authentication device.";
CM_ SG_ 761 VCSEC_bleConnetionAttemptWLEntry "Vehicle security controller: ble connetion attempt WL entry";
CM_ SG_ 761 VCSEC_AdditionalAuthInfoIndex "Vehicle security controller: additional auth info index";
CM_ SG_ 761 VCSEC_unsecureNotificationStatus "Vehicle security controller: unsecure notification status";
CM_ SG_ 761 VCSEC_activeKeyReason "Reason for picking the currently active key";
CM_ SG_ 761 VCSEC_activeKeySHA1 "Vehicle security controller: active key SHA1";
CM_ SG_ 761 VCSEC_algoUsedForSummonRange0 "Vehicle security controller: algo used for summon range0";
CM_ SG_ 761 VCSEC_keyWithinSummonRange0 "Vehicle security controller: key within summon range0";
CM_ SG_ 761 VCSEC_algoUsedForSummonRange1 "Vehicle security controller: algo used for summon range1";
CM_ SG_ 761 VCSEC_keyWithinSummonRange1 "Vehicle security controller: key within summon range1";
CM_ SG_ 761 VCSEC_algoUsedForSummonRange2 "Vehicle security controller: algo used for summon range2";
CM_ SG_ 761 VCSEC_keyWithinSummonRange2 "Vehicle security controller: key within summon range2";
CM_ SG_ 761 VCSEC_BLEDeviceWithinSummonRange "Vehicle security controller: BLE device within summon range";
CM_ SG_ 761 VCSEC_WalkupUnlockMitigationKeyI "Vehicle security controller: walkup unlock mitigation key index0";
CM_ SG_ 761 VCSEC_WalkupUnlockMitigatio_0003 "Vehicle security controller: walkup unlock mitigation key index1";
CM_ SG_ 761 VCSEC_WalkupUnlockMitigatio_0004 "Vehicle security controller: walkup unlock mitigation key index2";
CM_ SG_ 761 VCSEC_WalkupUnlockMitigationDesi "Vehicle security controller: walkup unlock mitigation desire0";
CM_ SG_ 761 VCSEC_WalkupUnlockMitigationReas "Vehicle security controller: walkup unlock mitigation reason0";
CM_ SG_ 761 VCSEC_WalkupUnlockMitigatio_0001 "Vehicle security controller: walkup unlock mitigation desire1";
CM_ SG_ 761 VCSEC_WalkupUnlockMitigatio_0005 "Vehicle security controller: walkup unlock mitigation reason1";
CM_ SG_ 761 VCSEC_WalkupUnlockMitigatio_0002 "Vehicle security controller: walkup unlock mitigation desire2";
CM_ SG_ 761 VCSEC_WalkupUnlockMitigatio_0006 "Vehicle security controller: walkup unlock mitigation reason2";
CM_ SG_ 761 VCSEC_NFCAuthFromBPillarFormFact "Reports the form factor authentication at B-pillar Near Field Communication (NFC) reader.";
CM_ SG_ 761 VCSEC_NFCAuthFromCenterConsoleFo "Reports the form factor authenticating at center console Near Field Communication (NFC) reader.";
BA_DEF_ BO_ "GenMsgCycleTime" INT 0 3600000;
BA_DEF_ BO_ "GenMsgSendType" ENUM "Cyclic","NotUsed","NotUsed","NotUsed","NotUsed","NotUsed","NotUsed","IfActive","NoMsgSendType","NotUsed";
BA_DEF_ BO_ "VFrameFormat" ENUM "StandardCAN","ExtendedCAN","reserved","J1939PG","reserved","reserved","reserved","reserved","reserved","reserved","reserved","reserved","reserved","reserved","StandardCAN_FD","ExtendedCAN_FD";
BA_DEF_ BO_ "CANFD_BRS" ENUM "0","1";
BA_DEF_ SG_ "SystemSignalLongSymbol" STRING;
BA_DEF_ SG_ "Confidence" ENUM "layout-only","plausible","validated";
BA_DEF_DEF_ "GenMsgCycleTime" 0;
BA_DEF_DEF_ "GenMsgSendType" "NoMsgSendType";
BA_DEF_DEF_ "VFrameFormat" "StandardCAN";
BA_DEF_DEF_ "CANFD_BRS" "1";
BA_DEF_DEF_ "SystemSignalLongSymbol" "";
BA_DEF_DEF_ "Confidence" "layout-only";
BA_ "Confidence" SG_ 969 VCSEC_UWBRightRadioConfigState 1;
BA_ "Confidence" SG_ 969 VCSEC_UWBRightUpdateStatus 1;
BA_ "Confidence" SG_ 969 VCSEC_UWBRearRightRadioConfigSta 1;
BA_ "SystemSignalLongSymbol" SG_ 969 VCSEC_UWBRearRightRadioConfigSta "VCSEC_UWBRearRightRadioConfigState";
BA_ "Confidence" SG_ 969 VCSEC_UWBRearRightUpdateStatus 1;
BA_ "SystemSignalLongSymbol" SG_ 969 VCSEC_UWBRearRightRetryLimitReac "VCSEC_UWBRearRightRetryLimitReached";
BA_ "Confidence" SG_ 969 VCSEC_UWBRearLeftRadioConfigStat 1;
BA_ "SystemSignalLongSymbol" SG_ 969 VCSEC_UWBRearLeftRadioConfigStat "VCSEC_UWBRearLeftRadioConfigState";
BA_ "Confidence" SG_ 969 VCSEC_UWBRearLeftUpdateStatus 1;
BA_ "SystemSignalLongSymbol" SG_ 969 VCSEC_UWBRearLeftRetryLimitReach "VCSEC_UWBRearLeftRetryLimitReached";
BA_ "Confidence" SG_ 969 VCSEC_UWBRearRadioConfigState 1;
BA_ "Confidence" SG_ 969 VCSEC_UWBRearUpdateStatus 1;
BA_ "Confidence" SG_ 969 VCSEC_UWBLeftRadioConfigState 1;
BA_ "Confidence" SG_ 969 VCSEC_UWBLeftUpdateStatus 1;
BA_ "Confidence" SG_ 969 VCSEC_UWBCenterRadioConfigState 1;
BA_ "Confidence" SG_ 969 VCSEC_UWBCenterUpdateStatus 1;
BA_ "Confidence" SG_ 607 VCSEC_childSeat0_connectionState 1;
BA_ "Confidence" SG_ 607 VCSEC_childSeat0_taskDisconnecti 1;
BA_ "SystemSignalLongSymbol" SG_ 607 VCSEC_childSeat0_taskDisconnecti "VCSEC_childSeat0_taskDisconnectionReason";
BA_ "Confidence" SG_ 607 VCSEC_childSeat0_state 1;
BA_ "Confidence" SG_ 607 VCSEC_childSeat0_taskErrorCode 1;
BA_ "Confidence" SG_ 607 VCSEC_childSeat0_ISOFixStatus 1;
BA_ "Confidence" SG_ 607 VCSEC_childSeat0_buckleStatus 1;
BA_ "Confidence" SG_ 607 VCSEC_childSeat0_occupancyStatus 1;
BA_ "Confidence" SG_ 607 VCSEC_childSeat1_connectionState 1;
BA_ "Confidence" SG_ 607 VCSEC_childSeat1_taskDisconnecti 1;
BA_ "SystemSignalLongSymbol" SG_ 607 VCSEC_childSeat1_taskDisconnecti "VCSEC_childSeat1_taskDisconnectionReason";
BA_ "Confidence" SG_ 607 VCSEC_childSeat1_state 1;
BA_ "Confidence" SG_ 607 VCSEC_childSeat1_taskErrorCode 1;
BA_ "Confidence" SG_ 607 VCSEC_childSeat1_ISOFixStatus 1;
BA_ "Confidence" SG_ 607 VCSEC_childSeat1_buckleStatus 1;
BA_ "Confidence" SG_ 607 VCSEC_childSeat1_occupancyStatus 1;
BA_ "SystemSignalLongSymbol" SG_ 607 VCSEC_childPresenceDetectionWarn "VCSEC_childPresenceDetectionWarningActive";
BA_ "Confidence" SG_ 607 VCSEC_childSeatScanStatus 1;
BA_ "Confidence" SG_ 607 VCSEC_childPresenceDetectionStat 1;
BA_ "SystemSignalLongSymbol" SG_ 607 VCSEC_childPresenceDetectionStat "VCSEC_childPresenceDetectionState";
BA_ "Confidence" SG_ 607 VCSEC_childPresenceDetectionSupp 1;
BA_ "SystemSignalLongSymbol" SG_ 607 VCSEC_childPresenceDetectionSupp "VCSEC_childPresenceDetectionSupportType";
BA_ "SystemSignalLongSymbol" SG_ 607 VCSEC_childPresenceDetectionNoti "VCSEC_childPresenceDetectionNotificationEnabled";
BA_ "Confidence" SG_ 857 VCSEC_Device0AuthResponseTime 1;
BA_ "Confidence" SG_ 857 VCSEC_Device0WLEntry 1;
BA_ "Confidence" SG_ 857 VCSEC_Device0BatteryLevel 1;
BA_ "Confidence" SG_ 857 VCSEC_Device0Formfactor 1;
BA_ "Confidence" SG_ 857 VCSEC_Device0Role 1;
BA_ "Confidence" SG_ 857 VCSEC_Device0WhitelistActiveTime 1;
BA_ "Confidence" SG_ 857 VCSEC_Device0SHA1 1;
BA_ "SystemSignalLongSymbol" SG_ 857 VCSEC_Device0ManufacturerHashBit "VCSEC_Device0ManufacturerHashBits";
BA_ "Confidence" SG_ 857 VCSEC_Device1AuthResponseTime 1;
BA_ "Confidence" SG_ 857 VCSEC_Device1WLEntry 1;
BA_ "Confidence" SG_ 857 VCSEC_Device1BatteryLevel 1;
BA_ "Confidence" SG_ 857 VCSEC_Device1Formfactor 1;
BA_ "Confidence" SG_ 857 VCSEC_Device1Role 1;
BA_ "Confidence" SG_ 857 VCSEC_Device1WhitelistActiveTime 1;
BA_ "Confidence" SG_ 857 VCSEC_Device1SHA1 1;
BA_ "SystemSignalLongSymbol" SG_ 857 VCSEC_Device1ManufacturerHashBit "VCSEC_Device1ManufacturerHashBits";
BA_ "Confidence" SG_ 857 VCSEC_Device2AuthResponseTime 1;
BA_ "Confidence" SG_ 857 VCSEC_Device2WLEntry 1;
BA_ "Confidence" SG_ 857 VCSEC_Device2BatteryLevel 1;
BA_ "Confidence" SG_ 857 VCSEC_Device2Formfactor 1;
BA_ "Confidence" SG_ 857 VCSEC_Device2Role 1;
BA_ "Confidence" SG_ 857 VCSEC_Device2WhitelistActiveTime 1;
BA_ "Confidence" SG_ 857 VCSEC_Device2SHA1 1;
BA_ "SystemSignalLongSymbol" SG_ 857 VCSEC_Device2ManufacturerHashBit "VCSEC_Device2ManufacturerHashBits";
BA_ "Confidence" SG_ 857 VCSEC_Device3AuthResponseTime 1;
BA_ "Confidence" SG_ 857 VCSEC_Device3WLEntry 1;
BA_ "Confidence" SG_ 857 VCSEC_Device3BatteryLevel 1;
BA_ "Confidence" SG_ 857 VCSEC_Device3Formfactor 1;
BA_ "Confidence" SG_ 857 VCSEC_Device3Role 1;
BA_ "Confidence" SG_ 857 VCSEC_Device3WhitelistActiveTime 1;
BA_ "Confidence" SG_ 857 VCSEC_Device3SHA1 1;
BA_ "SystemSignalLongSymbol" SG_ 857 VCSEC_Device3ManufacturerHashBit "VCSEC_Device3ManufacturerHashBits";
BA_ "Confidence" SG_ 857 VCSEC_Device4AuthResponseTime 1;
BA_ "Confidence" SG_ 857 VCSEC_Device4WLEntry 1;
BA_ "Confidence" SG_ 857 VCSEC_Device4BatteryLevel 1;
BA_ "Confidence" SG_ 857 VCSEC_Device4Formfactor 1;
BA_ "Confidence" SG_ 857 VCSEC_Device4Role 1;
BA_ "Confidence" SG_ 857 VCSEC_Device4WhitelistActiveTime 1;
BA_ "Confidence" SG_ 857 VCSEC_Device4SHA1 1;
BA_ "SystemSignalLongSymbol" SG_ 857 VCSEC_Device4ManufacturerHashBit "VCSEC_Device4ManufacturerHashBits";
BA_ "Confidence" SG_ 857 VCSEC_Device5AuthResponseTime 1;
BA_ "Confidence" SG_ 857 VCSEC_Device5WLEntry 1;
BA_ "Confidence" SG_ 857 VCSEC_Device5BatteryLevel 1;
BA_ "Confidence" SG_ 857 VCSEC_Device5Formfactor 1;
BA_ "Confidence" SG_ 857 VCSEC_Device5Role 1;
BA_ "Confidence" SG_ 857 VCSEC_Device5WhitelistActiveTime 1;
BA_ "Confidence" SG_ 857 VCSEC_Device5SHA1 1;
BA_ "SystemSignalLongSymbol" SG_ 857 VCSEC_Device5ManufacturerHashBit "VCSEC_Device5ManufacturerHashBits";
BA_ "Confidence" SG_ 857 VCSEC_Device6AuthResponseTime 1;
BA_ "Confidence" SG_ 857 VCSEC_Device6WLEntry 1;
BA_ "Confidence" SG_ 857 VCSEC_Device6BatteryLevel 1;
BA_ "Confidence" SG_ 857 VCSEC_Device6Formfactor 1;
BA_ "Confidence" SG_ 857 VCSEC_Device6Role 1;
BA_ "Confidence" SG_ 857 VCSEC_Device6WhitelistActiveTime 1;
BA_ "Confidence" SG_ 857 VCSEC_Device6SHA1 1;
BA_ "SystemSignalLongSymbol" SG_ 857 VCSEC_Device6ManufacturerHashBit "VCSEC_Device6ManufacturerHashBits";
BA_ "Confidence" SG_ 857 VCSEC_Device7AuthResponseTime 1;
BA_ "Confidence" SG_ 857 VCSEC_Device7WLEntry 1;
BA_ "Confidence" SG_ 857 VCSEC_Device7BatteryLevel 1;
BA_ "Confidence" SG_ 857 VCSEC_Device7Formfactor 1;
BA_ "Confidence" SG_ 857 VCSEC_Device7Role 1;
BA_ "Confidence" SG_ 857 VCSEC_Device7WhitelistActiveTime 1;
BA_ "Confidence" SG_ 857 VCSEC_Device7SHA1 1;
BA_ "SystemSignalLongSymbol" SG_ 857 VCSEC_Device7ManufacturerHashBit "VCSEC_Device7ManufacturerHashBits";
BA_ "Confidence" SG_ 857 VCSEC_Device8AuthResponseTime 1;
BA_ "Confidence" SG_ 857 VCSEC_Device8WLEntry 1;
BA_ "Confidence" SG_ 857 VCSEC_Device8BatteryLevel 1;
BA_ "Confidence" SG_ 857 VCSEC_Device8Formfactor 1;
BA_ "Confidence" SG_ 857 VCSEC_Device8Role 1;
BA_ "Confidence" SG_ 857 VCSEC_Device8WhitelistActiveTime 1;
BA_ "Confidence" SG_ 857 VCSEC_Device8SHA1 1;
BA_ "SystemSignalLongSymbol" SG_ 857 VCSEC_Device8ManufacturerHashBit "VCSEC_Device8ManufacturerHashBits";
BA_ "Confidence" SG_ 857 VCSEC_Device9AuthResponseTime 1;
BA_ "Confidence" SG_ 857 VCSEC_Device9WLEntry 1;
BA_ "Confidence" SG_ 857 VCSEC_Device9BatteryLevel 1;
BA_ "Confidence" SG_ 857 VCSEC_Device9Formfactor 1;
BA_ "Confidence" SG_ 857 VCSEC_Device9Role 1;
BA_ "Confidence" SG_ 857 VCSEC_Device9WhitelistActiveTime 1;
BA_ "Confidence" SG_ 857 VCSEC_Device9SHA1 1;
BA_ "SystemSignalLongSymbol" SG_ 857 VCSEC_Device9ManufacturerHashBit "VCSEC_Device9ManufacturerHashBits";
BA_ "Confidence" SG_ 857 VCSEC_Device10AuthResponseTime 1;
BA_ "Confidence" SG_ 857 VCSEC_Device10WLEntry 1;
BA_ "Confidence" SG_ 857 VCSEC_Device10BatteryLevel 1;
BA_ "Confidence" SG_ 857 VCSEC_Device10Formfactor 1;
BA_ "Confidence" SG_ 857 VCSEC_Device10Role 1;
BA_ "Confidence" SG_ 857 VCSEC_Device10WhitelistActiveTim 1;
BA_ "SystemSignalLongSymbol" SG_ 857 VCSEC_Device10WhitelistActiveTim "VCSEC_Device10WhitelistActiveTime";
BA_ "Confidence" SG_ 857 VCSEC_Device10SHA1 1;
BA_ "SystemSignalLongSymbol" SG_ 857 VCSEC_Device10ManufacturerHashBi "VCSEC_Device10ManufacturerHashBits";
BA_ "SystemSignalLongSymbol" SG_ 857 VCSEC_Device10BuildNumberHashBit "VCSEC_Device10BuildNumberHashBits";
BA_ "Confidence" SG_ 857 VCSEC_Device11AuthResponseTime 1;
BA_ "Confidence" SG_ 857 VCSEC_Device11WLEntry 1;
BA_ "Confidence" SG_ 857 VCSEC_Device11BatteryLevel 1;
BA_ "Confidence" SG_ 857 VCSEC_Device11Formfactor 1;
BA_ "Confidence" SG_ 857 VCSEC_Device11Role 1;
BA_ "Confidence" SG_ 857 VCSEC_Device11WhitelistActiveTim 1;
BA_ "SystemSignalLongSymbol" SG_ 857 VCSEC_Device11WhitelistActiveTim "VCSEC_Device11WhitelistActiveTime";
BA_ "Confidence" SG_ 857 VCSEC_Device11SHA1 1;
BA_ "SystemSignalLongSymbol" SG_ 857 VCSEC_Device11ManufacturerHashBi "VCSEC_Device11ManufacturerHashBits";
BA_ "SystemSignalLongSymbol" SG_ 857 VCSEC_Device11BuildNumberHashBit "VCSEC_Device11BuildNumberHashBits";
BA_ "Confidence" SG_ 857 VCSEC_Device12AuthResponseTime 1;
BA_ "Confidence" SG_ 857 VCSEC_Device12WLEntry 1;
BA_ "Confidence" SG_ 857 VCSEC_Device12BatteryLevel 1;
BA_ "Confidence" SG_ 857 VCSEC_Device12Formfactor 1;
BA_ "Confidence" SG_ 857 VCSEC_Device12Role 1;
BA_ "Confidence" SG_ 857 VCSEC_Device12WhitelistActiveTim 1;
BA_ "SystemSignalLongSymbol" SG_ 857 VCSEC_Device12WhitelistActiveTim "VCSEC_Device12WhitelistActiveTime";
BA_ "Confidence" SG_ 857 VCSEC_Device12SHA1 1;
BA_ "SystemSignalLongSymbol" SG_ 857 VCSEC_Device12ManufacturerHashBi "VCSEC_Device12ManufacturerHashBits";
BA_ "SystemSignalLongSymbol" SG_ 857 VCSEC_Device12BuildNumberHashBit "VCSEC_Device12BuildNumberHashBits";
BA_ "Confidence" SG_ 857 VCSEC_Device13AuthResponseTime 1;
BA_ "Confidence" SG_ 857 VCSEC_Device13WLEntry 1;
BA_ "Confidence" SG_ 857 VCSEC_Device13BatteryLevel 1;
BA_ "Confidence" SG_ 857 VCSEC_Device13Formfactor 1;
BA_ "Confidence" SG_ 857 VCSEC_Device13Role 1;
BA_ "Confidence" SG_ 857 VCSEC_Device13WhitelistActiveTim 1;
BA_ "SystemSignalLongSymbol" SG_ 857 VCSEC_Device13WhitelistActiveTim "VCSEC_Device13WhitelistActiveTime";
BA_ "Confidence" SG_ 857 VCSEC_Device13SHA1 1;
BA_ "SystemSignalLongSymbol" SG_ 857 VCSEC_Device13ManufacturerHashBi "VCSEC_Device13ManufacturerHashBits";
BA_ "SystemSignalLongSymbol" SG_ 857 VCSEC_Device13BuildNumberHashBit "VCSEC_Device13BuildNumberHashBits";
BA_ "Confidence" SG_ 857 VCSEC_Device14AuthResponseTime 1;
BA_ "Confidence" SG_ 857 VCSEC_Device14WLEntry 1;
BA_ "Confidence" SG_ 857 VCSEC_Device14BatteryLevel 1;
BA_ "Confidence" SG_ 857 VCSEC_Device14Formfactor 1;
BA_ "Confidence" SG_ 857 VCSEC_Device14Role 1;
BA_ "Confidence" SG_ 857 VCSEC_Device14WhitelistActiveTim 1;
BA_ "SystemSignalLongSymbol" SG_ 857 VCSEC_Device14WhitelistActiveTim "VCSEC_Device14WhitelistActiveTime";
BA_ "Confidence" SG_ 857 VCSEC_Device14SHA1 1;
BA_ "SystemSignalLongSymbol" SG_ 857 VCSEC_Device14ManufacturerHashBi "VCSEC_Device14ManufacturerHashBits";
BA_ "SystemSignalLongSymbol" SG_ 857 VCSEC_Device14BuildNumberHashBit "VCSEC_Device14BuildNumberHashBits";
BA_ "Confidence" SG_ 857 VCSEC_Device15AuthResponseTime 1;
BA_ "Confidence" SG_ 857 VCSEC_Device15WLEntry 1;
BA_ "Confidence" SG_ 857 VCSEC_Device15BatteryLevel 1;
BA_ "Confidence" SG_ 857 VCSEC_Device15Formfactor 1;
BA_ "Confidence" SG_ 857 VCSEC_Device15Role 1;
BA_ "Confidence" SG_ 857 VCSEC_Device15WhitelistActiveTim 1;
BA_ "SystemSignalLongSymbol" SG_ 857 VCSEC_Device15WhitelistActiveTim "VCSEC_Device15WhitelistActiveTime";
BA_ "Confidence" SG_ 857 VCSEC_Device15SHA1 1;
BA_ "SystemSignalLongSymbol" SG_ 857 VCSEC_Device15ManufacturerHashBi "VCSEC_Device15ManufacturerHashBits";
BA_ "SystemSignalLongSymbol" SG_ 857 VCSEC_Device15BuildNumberHashBit "VCSEC_Device15BuildNumberHashBits";
BA_ "Confidence" SG_ 857 VCSEC_Device16AuthResponseTime 1;
BA_ "Confidence" SG_ 857 VCSEC_Device16WLEntry 1;
BA_ "Confidence" SG_ 857 VCSEC_Device16BatteryLevel 1;
BA_ "Confidence" SG_ 857 VCSEC_Device16Formfactor 1;
BA_ "Confidence" SG_ 857 VCSEC_Device16Role 1;
BA_ "Confidence" SG_ 857 VCSEC_Device16WhitelistActiveTim 1;
BA_ "SystemSignalLongSymbol" SG_ 857 VCSEC_Device16WhitelistActiveTim "VCSEC_Device16WhitelistActiveTime";
BA_ "Confidence" SG_ 857 VCSEC_Device16SHA1 1;
BA_ "SystemSignalLongSymbol" SG_ 857 VCSEC_Device16ManufacturerHashBi "VCSEC_Device16ManufacturerHashBits";
BA_ "SystemSignalLongSymbol" SG_ 857 VCSEC_Device16BuildNumberHashBit "VCSEC_Device16BuildNumberHashBits";
BA_ "Confidence" SG_ 857 VCSEC_Device17AuthResponseTime 1;
BA_ "Confidence" SG_ 857 VCSEC_Device17WLEntry 1;
BA_ "Confidence" SG_ 857 VCSEC_Device17BatteryLevel 1;
BA_ "Confidence" SG_ 857 VCSEC_Device17Formfactor 1;
BA_ "Confidence" SG_ 857 VCSEC_Device17Role 1;
BA_ "Confidence" SG_ 857 VCSEC_Device17WhitelistActiveTim 1;
BA_ "SystemSignalLongSymbol" SG_ 857 VCSEC_Device17WhitelistActiveTim "VCSEC_Device17WhitelistActiveTime";
BA_ "Confidence" SG_ 857 VCSEC_Device17SHA1 1;
BA_ "SystemSignalLongSymbol" SG_ 857 VCSEC_Device17ManufacturerHashBi "VCSEC_Device17ManufacturerHashBits";
BA_ "SystemSignalLongSymbol" SG_ 857 VCSEC_Device17BuildNumberHashBit "VCSEC_Device17BuildNumberHashBits";
BA_ "Confidence" SG_ 857 VCSEC_Device18AuthResponseTime 1;
BA_ "Confidence" SG_ 857 VCSEC_Device18WLEntry 1;
BA_ "Confidence" SG_ 857 VCSEC_Device18BatteryLevel 1;
BA_ "Confidence" SG_ 857 VCSEC_Device18Formfactor 1;
BA_ "Confidence" SG_ 857 VCSEC_Device18Role 1;
BA_ "Confidence" SG_ 857 VCSEC_Device18WhitelistActiveTim 1;
BA_ "SystemSignalLongSymbol" SG_ 857 VCSEC_Device18WhitelistActiveTim "VCSEC_Device18WhitelistActiveTime";
BA_ "Confidence" SG_ 857 VCSEC_Device18SHA1 1;
BA_ "SystemSignalLongSymbol" SG_ 857 VCSEC_Device18ManufacturerHashBi "VCSEC_Device18ManufacturerHashBits";
BA_ "SystemSignalLongSymbol" SG_ 857 VCSEC_Device18BuildNumberHashBit "VCSEC_Device18BuildNumberHashBits";
BA_ "Confidence" SG_ 857 VCSEC_Device19AuthResponseTime 1;
BA_ "Confidence" SG_ 857 VCSEC_Device19WLEntry 1;
BA_ "Confidence" SG_ 857 VCSEC_Device19BatteryLevel 1;
BA_ "Confidence" SG_ 857 VCSEC_Device19Formfactor 1;
BA_ "Confidence" SG_ 857 VCSEC_Device19Role 1;
BA_ "Confidence" SG_ 857 VCSEC_Device19WhitelistActiveTim 1;
BA_ "SystemSignalLongSymbol" SG_ 857 VCSEC_Device19WhitelistActiveTim "VCSEC_Device19WhitelistActiveTime";
BA_ "Confidence" SG_ 857 VCSEC_Device19SHA1 1;
BA_ "SystemSignalLongSymbol" SG_ 857 VCSEC_Device19ManufacturerHashBi "VCSEC_Device19ManufacturerHashBits";
BA_ "SystemSignalLongSymbol" SG_ 857 VCSEC_Device19BuildNumberHashBit "VCSEC_Device19BuildNumberHashBits";
BA_ "Confidence" SG_ 1066 VCSEC_TPMSSensorState0 1;
BA_ "Confidence" SG_ 1066 VCSEC_TPMSRSSI0 1;
BA_ "Confidence" SG_ 1066 VCSEC_TPMSConnectionTypeCurrent0 1;
BA_ "Confidence" SG_ 1066 VCSEC_TPMSConnectionTypeDesired0 1;
BA_ "Confidence" SG_ 1066 VCSEC_TPMSSensorState1 1;
BA_ "Confidence" SG_ 1066 VCSEC_TPMSRSSI1 1;
BA_ "Confidence" SG_ 1066 VCSEC_TPMSConnectionTypeCurrent1 1;
BA_ "Confidence" SG_ 1066 VCSEC_TPMSConnectionTypeDesired1 1;
BA_ "Confidence" SG_ 1066 VCSEC_TPMSSensorState2 1;
BA_ "Confidence" SG_ 1066 VCSEC_TPMSRSSI2 1;
BA_ "Confidence" SG_ 1066 VCSEC_TPMSConnectionTypeCurrent2 1;
BA_ "Confidence" SG_ 1066 VCSEC_TPMSConnectionTypeDesired2 1;
BA_ "Confidence" SG_ 1066 VCSEC_TPMSSensorState3 1;
BA_ "Confidence" SG_ 1066 VCSEC_TPMSRSSI3 1;
BA_ "Confidence" SG_ 1066 VCSEC_TPMSConnectionTypeCurrent3 1;
BA_ "Confidence" SG_ 1066 VCSEC_TPMSConnectionTypeDesired3 1;
BA_ "Confidence" SG_ 1066 VCSEC_TPMSSensorPresence0 1;
BA_ "Confidence" SG_ 1066 VCSEC_TPMSSensorPresence1 1;
BA_ "Confidence" SG_ 1066 VCSEC_TPMSSensorPresence2 1;
BA_ "Confidence" SG_ 1066 VCSEC_TPMSSensorPresence3 1;
BA_ "SystemSignalLongSymbol" SG_ 537 VCSEC_TPMSCapabilityPressureInAd "VCSEC_TPMSCapabilityPressureInAdv0";
BA_ "SystemSignalLongSymbol" SG_ 537 VCSEC_TPMSCapabilityConfigurable "VCSEC_TPMSCapabilityConfigurablePressure0";
BA_ "Confidence" SG_ 537 VCSEC_TPMSPressureRateOfChange0 1;
BA_ "Confidence" SG_ 537 VCSEC_TPMSPressure0 1;
BA_ "Confidence" SG_ 537 VCSEC_TPMSTemperature0 1;
BA_ "Confidence" SG_ 537 VCSEC_TPMSBatVoltage0 1;
BA_ "Confidence" SG_ 537 VCSEC_TPMSLocation0 1;
BA_ "Confidence" SG_ 537 VCSEC_TPMSTemperatureCompensated 1;
BA_ "SystemSignalLongSymbol" SG_ 537 VCSEC_TPMSTemperatureCompensated "VCSEC_TPMSTemperatureCompensatedPressure0";
BA_ "SystemSignalLongSymbol" SG_ 537 VCSEC_TPMSCapabilityPressur_0001 "VCSEC_TPMSCapabilityPressureInAdv1";
BA_ "SystemSignalLongSymbol" SG_ 537 VCSEC_TPMSCapabilityConfigu_0001 "VCSEC_TPMSCapabilityConfigurablePressure1";
BA_ "Confidence" SG_ 537 VCSEC_TPMSPressureRateOfChange1 1;
BA_ "Confidence" SG_ 537 VCSEC_TPMSPressure1 1;
BA_ "Confidence" SG_ 537 VCSEC_TPMSTemperature1 1;
BA_ "Confidence" SG_ 537 VCSEC_TPMSBatVoltage1 1;
BA_ "Confidence" SG_ 537 VCSEC_TPMSLocation1 1;
BA_ "Confidence" SG_ 537 VCSEC_TPMSTemperatureCompen_0001 1;
BA_ "SystemSignalLongSymbol" SG_ 537 VCSEC_TPMSTemperatureCompen_0001 "VCSEC_TPMSTemperatureCompensatedPressure1";
BA_ "SystemSignalLongSymbol" SG_ 537 VCSEC_TPMSCapabilityPressur_0002 "VCSEC_TPMSCapabilityPressureInAdv2";
BA_ "SystemSignalLongSymbol" SG_ 537 VCSEC_TPMSCapabilityConfigu_0002 "VCSEC_TPMSCapabilityConfigurablePressure2";
BA_ "Confidence" SG_ 537 VCSEC_TPMSPressureRateOfChange2 1;
BA_ "Confidence" SG_ 537 VCSEC_TPMSPressure2 1;
BA_ "Confidence" SG_ 537 VCSEC_TPMSTemperature2 1;
BA_ "Confidence" SG_ 537 VCSEC_TPMSBatVoltage2 1;
BA_ "Confidence" SG_ 537 VCSEC_TPMSLocation2 1;
BA_ "Confidence" SG_ 537 VCSEC_TPMSTemperatureCompen_0002 1;
BA_ "SystemSignalLongSymbol" SG_ 537 VCSEC_TPMSTemperatureCompen_0002 "VCSEC_TPMSTemperatureCompensatedPressure2";
BA_ "SystemSignalLongSymbol" SG_ 537 VCSEC_TPMSCapabilityPressur_0003 "VCSEC_TPMSCapabilityPressureInAdv3";
BA_ "SystemSignalLongSymbol" SG_ 537 VCSEC_TPMSCapabilityConfigu_0003 "VCSEC_TPMSCapabilityConfigurablePressure3";
BA_ "Confidence" SG_ 537 VCSEC_TPMSPressureRateOfChange3 1;
BA_ "Confidence" SG_ 537 VCSEC_TPMSPressure3 1;
BA_ "Confidence" SG_ 537 VCSEC_TPMSTemperature3 1;
BA_ "Confidence" SG_ 537 VCSEC_TPMSBatVoltage3 1;
BA_ "Confidence" SG_ 537 VCSEC_TPMSLocation3 1;
BA_ "Confidence" SG_ 537 VCSEC_TPMSTemperatureCompen_0003 1;
BA_ "SystemSignalLongSymbol" SG_ 537 VCSEC_TPMSTemperatureCompen_0003 "VCSEC_TPMSTemperatureCompensatedPressure3";
BA_ "Confidence" SG_ 537 VCSEC_TPMSRecommendedColdPressur 1;
BA_ "SystemSignalLongSymbol" SG_ 537 VCSEC_TPMSRecommendedColdPressur "VCSEC_TPMSRecommendedColdPressureFront";
BA_ "Confidence" SG_ 537 VCSEC_TPMSRecommendedColdPr_0001 1;
BA_ "SystemSignalLongSymbol" SG_ 537 VCSEC_TPMSRecommendedColdPr_0001 "VCSEC_TPMSRecommendedColdPressureRear";
BA_ "Confidence" SG_ 537 VCSEC_TPMSFeature0 1;
BA_ "Confidence" SG_ 537 VCSEC_TPMSFeature1 1;
BA_ "Confidence" SG_ 602 VCSEC_TPMSDisplayPressureFL 1;
BA_ "Confidence" SG_ 602 VCSEC_TPMSDisplayPressureFR 1;
BA_ "Confidence" SG_ 602 VCSEC_TPMSDisplayPressureRL 1;
BA_ "Confidence" SG_ 602 VCSEC_TPMSDisplayPressureRR 1;
BA_ "Confidence" SG_ 602 VCSEC_TPMSTellTale 1;
BA_ "Confidence" SG_ 602 VCSEC_TPMSDisplaySoftWarningIndi 1;
BA_ "SystemSignalLongSymbol" SG_ 602 VCSEC_TPMSDisplaySoftWarningIndi "VCSEC_TPMSDisplaySoftWarningIndicationFL";
BA_ "Confidence" SG_ 602 VCSEC_TPMSDisplaySoftWarnin_0001 1;
BA_ "SystemSignalLongSymbol" SG_ 602 VCSEC_TPMSDisplaySoftWarnin_0001 "VCSEC_TPMSDisplaySoftWarningIndicationFR";
BA_ "Confidence" SG_ 602 VCSEC_TPMSDisplaySoftWarnin_0002 1;
BA_ "SystemSignalLongSymbol" SG_ 602 VCSEC_TPMSDisplaySoftWarnin_0002 "VCSEC_TPMSDisplaySoftWarningIndicationRL";
BA_ "Confidence" SG_ 602 VCSEC_TPMSDisplaySoftWarnin_0003 1;
BA_ "SystemSignalLongSymbol" SG_ 602 VCSEC_TPMSDisplaySoftWarnin_0003 "VCSEC_TPMSDisplaySoftWarningIndicationRR";
BA_ "Confidence" SG_ 602 VCSEC_TPMSDisplayHardWarningIndi 1;
BA_ "SystemSignalLongSymbol" SG_ 602 VCSEC_TPMSDisplayHardWarningIndi "VCSEC_TPMSDisplayHardWarningIndicationFL";
BA_ "Confidence" SG_ 602 VCSEC_TPMSDisplayHardWarnin_0001 1;
BA_ "SystemSignalLongSymbol" SG_ 602 VCSEC_TPMSDisplayHardWarnin_0001 "VCSEC_TPMSDisplayHardWarningIndicationFR";
BA_ "Confidence" SG_ 602 VCSEC_TPMSDisplayHardWarnin_0002 1;
BA_ "SystemSignalLongSymbol" SG_ 602 VCSEC_TPMSDisplayHardWarnin_0002 "VCSEC_TPMSDisplayHardWarningIndicationRL";
BA_ "Confidence" SG_ 602 VCSEC_TPMSDisplayHardWarnin_0003 1;
BA_ "SystemSignalLongSymbol" SG_ 602 VCSEC_TPMSDisplayHardWarnin_0003 "VCSEC_TPMSDisplayHardWarningIndicationRR";
BA_ "Confidence" SG_ 570 VCSEC_TPMSSystemState 1;
BA_ "Confidence" SG_ 570 VCSEC_BLESuccessfulConnEventCoun 1;
BA_ "SystemSignalLongSymbol" SG_ 570 VCSEC_BLESuccessfulConnEventCoun "VCSEC_BLESuccessfulConnEventCount0";
BA_ "Confidence" SG_ 570 VCSEC_BLEMissedConnEventCount0 1;
BA_ "Confidence" SG_ 570 VCSEC_BLECRCErrorConnEventCount0 1;
BA_ "Confidence" SG_ 570 VCSEC_BLEOtherFailuresCount0 1;
BA_ "Confidence" SG_ 570 VCSEC_BLEUnsuccessfulConnEventRa 1;
BA_ "SystemSignalLongSymbol" SG_ 570 VCSEC_BLEUnsuccessfulConnEventRa "VCSEC_BLEUnsuccessfulConnEventRate0";
BA_ "Confidence" SG_ 570 VCSEC_BLESuccessfulConnEven_0001 1;
BA_ "SystemSignalLongSymbol" SG_ 570 VCSEC_BLESuccessfulConnEven_0001 "VCSEC_BLESuccessfulConnEventCount1";
BA_ "Confidence" SG_ 570 VCSEC_BLEMissedConnEventCount1 1;
BA_ "Confidence" SG_ 570 VCSEC_BLECRCErrorConnEventCount1 1;
BA_ "Confidence" SG_ 570 VCSEC_BLEOtherFailuresCount1 1;
BA_ "Confidence" SG_ 570 VCSEC_BLEUnsuccessfulConnEv_0001 1;
BA_ "SystemSignalLongSymbol" SG_ 570 VCSEC_BLEUnsuccessfulConnEv_0001 "VCSEC_BLEUnsuccessfulConnEventRate1";
BA_ "Confidence" SG_ 570 VCSEC_BLESuccessfulConnEven_0002 1;
BA_ "SystemSignalLongSymbol" SG_ 570 VCSEC_BLESuccessfulConnEven_0002 "VCSEC_BLESuccessfulConnEventCount2";
BA_ "Confidence" SG_ 570 VCSEC_BLEMissedConnEventCount2 1;
BA_ "Confidence" SG_ 570 VCSEC_BLECRCErrorConnEventCount2 1;
BA_ "Confidence" SG_ 570 VCSEC_BLEOtherFailuresCount2 1;
BA_ "Confidence" SG_ 570 VCSEC_BLEUnsuccessfulConnEv_0002 1;
BA_ "SystemSignalLongSymbol" SG_ 570 VCSEC_BLEUnsuccessfulConnEv_0002 "VCSEC_BLEUnsuccessfulConnEventRate2";
BA_ "Confidence" SG_ 570 VCSEC_BLESuccessfulConnEven_0003 1;
BA_ "SystemSignalLongSymbol" SG_ 570 VCSEC_BLESuccessfulConnEven_0003 "VCSEC_BLESuccessfulConnEventCount3";
BA_ "Confidence" SG_ 570 VCSEC_BLEMissedConnEventCount3 1;
BA_ "Confidence" SG_ 570 VCSEC_BLECRCErrorConnEventCount3 1;
BA_ "Confidence" SG_ 570 VCSEC_BLEOtherFailuresCount3 1;
BA_ "Confidence" SG_ 570 VCSEC_BLEUnsuccessfulConnEv_0003 1;
BA_ "SystemSignalLongSymbol" SG_ 570 VCSEC_BLEUnsuccessfulConnEv_0003 "VCSEC_BLEUnsuccessfulConnEventRate3";
BA_ "Confidence" SG_ 570 VCSEC_TPMStotalAwakeTime0 1;
BA_ "Confidence" SG_ 570 VCSEC_TPMSGenealogySensorState0 1;
BA_ "Confidence" SG_ 570 VCSEC_TPMSSensorType0 1;
BA_ "Confidence" SG_ 570 VCSEC_TPMStotalAwakeTime1 1;
BA_ "Confidence" SG_ 570 VCSEC_TPMSGenealogySensorState1 1;
BA_ "Confidence" SG_ 570 VCSEC_TPMSSensorType1 1;
BA_ "Confidence" SG_ 570 VCSEC_TPMStotalAwakeTime2 1;
BA_ "Confidence" SG_ 570 VCSEC_TPMSGenealogySensorState2 1;
BA_ "Confidence" SG_ 570 VCSEC_TPMSSensorType2 1;
BA_ "Confidence" SG_ 570 VCSEC_TPMStotalAwakeTime3 1;
BA_ "Confidence" SG_ 570 VCSEC_TPMSGenealogySensorState3 1;
BA_ "Confidence" SG_ 570 VCSEC_TPMSSensorType3 1;
BA_ "Confidence" SG_ 1067 VCSEC_UWBRearRightDistance0 1;
BA_ "Confidence" SG_ 1067 VCSEC_UWBRearRightDistance1 1;
BA_ "Confidence" SG_ 1067 VCSEC_UWBRearRightDistance2 1;
BA_ "Confidence" SG_ 1067 VCSEC_UWBLeftDistance2 1;
BA_ "Confidence" SG_ 1067 VCSEC_UWBRightDistance2 1;
BA_ "Confidence" SG_ 1067 VCSEC_UWBRearDistance2 1;
BA_ "Confidence" SG_ 1067 VCSEC_UWBRearLeftDistance2 1;
BA_ "Confidence" SG_ 1067 VCSEC_UWBCenterDistance2 1;
BA_ "Confidence" SG_ 1067 VCSEC_UWBLeftDistance1 1;
BA_ "Confidence" SG_ 1067 VCSEC_UWBRightDistance1 1;
BA_ "Confidence" SG_ 1067 VCSEC_UWBRearDistance1 1;
BA_ "Confidence" SG_ 1067 VCSEC_UWBRearLeftDistance1 1;
BA_ "Confidence" SG_ 1067 VCSEC_UWBCenterDistance1 1;
BA_ "Confidence" SG_ 1067 VCSEC_UWBLeftDistance0 1;
BA_ "Confidence" SG_ 1067 VCSEC_UWBRightDistance0 1;
BA_ "Confidence" SG_ 1067 VCSEC_UWBRearDistance0 1;
BA_ "Confidence" SG_ 1067 VCSEC_UWBRearLeftDistance0 1;
BA_ "Confidence" SG_ 1067 VCSEC_UWBCenterDistance0 1;
BA_ "Confidence" SG_ 761 VCSEC_bleChannelDisconnected 1;
BA_ "Confidence" SG_ 761 VCSEC_bleDisconnectionReason 1;
BA_ "Confidence" SG_ 761 VCSEC_activeKeyReason 1;
BA_ "Confidence" SG_ 761 VCSEC_algoUsedForSummonRange0 1;
BA_ "Confidence" SG_ 761 VCSEC_algoUsedForSummonRange1 1;
BA_ "Confidence" SG_ 761 VCSEC_algoUsedForSummonRange2 1;
BA_ "SystemSignalLongSymbol" SG_ 761 VCSEC_WalkupUnlockMitigationKeyI "VCSEC_WalkupUnlockMitigationKeyIndex0";
BA_ "SystemSignalLongSymbol" SG_ 761 VCSEC_WalkupUnlockMitigatio_0003 "VCSEC_WalkupUnlockMitigationKeyIndex1";
BA_ "SystemSignalLongSymbol" SG_ 761 VCSEC_WalkupUnlockMitigatio_0004 "VCSEC_WalkupUnlockMitigationKeyIndex2";
BA_ "SystemSignalLongSymbol" SG_ 761 VCSEC_WalkupUnlockMitigationDesi "VCSEC_WalkupUnlockMitigationDesire0";
BA_ "SystemSignalLongSymbol" SG_ 761 VCSEC_WalkupUnlockMitigationReas "VCSEC_WalkupUnlockMitigationReason0";
BA_ "SystemSignalLongSymbol" SG_ 761 VCSEC_WalkupUnlockMitigatio_0001 "VCSEC_WalkupUnlockMitigationDesire1";
BA_ "SystemSignalLongSymbol" SG_ 761 VCSEC_WalkupUnlockMitigatio_0005 "VCSEC_WalkupUnlockMitigationReason1";
BA_ "SystemSignalLongSymbol" SG_ 761 VCSEC_WalkupUnlockMitigatio_0002 "VCSEC_WalkupUnlockMitigationDesire2";
BA_ "SystemSignalLongSymbol" SG_ 761 VCSEC_WalkupUnlockMitigatio_0006 "VCSEC_WalkupUnlockMitigationReason2";
BA_ "Confidence" SG_ 761 VCSEC_NFCAuthFromBPillarFormFact 1;
BA_ "SystemSignalLongSymbol" SG_ 761 VCSEC_NFCAuthFromBPillarFormFact "VCSEC_NFCAuthFromBPillarFormFactor";
BA_ "Confidence" SG_ 761 VCSEC_NFCAuthFromCenterConsoleFo 1;
BA_ "SystemSignalLongSymbol" SG_ 761 VCSEC_NFCAuthFromCenterConsoleFo "VCSEC_NFCAuthFromCenterConsoleFormFactor";
VAL_ 969 VCSEC_UWBRightRadioConfigState 13 "DONE_VERIFYING_RADIO_CONFIG" 12 "WAIT_FOR_LOOPBACK_CALIBRATION" 11 "START_LOOPBACK_CALIBRATION" 10 "WAIT_FOR_PROGRAM_FLASH" 9 "PROGRAM_FLASH" 8 "WAIT_FOR_DOWNLOAD_DATA" 7 "DOWNLOAD_DATA" 6 "WAIT_FOR_INIT_CONFIGURATION" 5 "INIT_CONFIGURATION" 4 "PREPARE_UPDATE" 3 "WAIT_TO_GET_CURRENT_CRC" 2 "GET_CURRENT_CRC" 1 "WAIT_AFTER_TRIGGER" 0 "WAIT_FOR_TRIGGER" ;
VAL_ 969 VCSEC_UWBRightUpdateStatus 3 "IN_PROGRESS" 2 "FAIL" 1 "UP_TO_DATE" 0 "NOT_STARTED" ;
VAL_ 969 VCSEC_UWBRearRightRadioConfigSta 13 "DONE_VERIFYING_RADIO_CONFIG" 12 "WAIT_FOR_LOOPBACK_CALIBRATION" 11 "START_LOOPBACK_CALIBRATION" 10 "WAIT_FOR_PROGRAM_FLASH" 9 "PROGRAM_FLASH" 8 "WAIT_FOR_DOWNLOAD_DATA" 7 "DOWNLOAD_DATA" 6 "WAIT_FOR_INIT_CONFIGURATION" 5 "INIT_CONFIGURATION" 4 "PREPARE_UPDATE" 3 "WAIT_TO_GET_CURRENT_CRC" 2 "GET_CURRENT_CRC" 1 "WAIT_AFTER_TRIGGER" 0 "WAIT_FOR_TRIGGER" ;
VAL_ 969 VCSEC_UWBRearRightUpdateStatus 3 "IN_PROGRESS" 2 "FAIL" 1 "UP_TO_DATE" 0 "NOT_STARTED" ;
VAL_ 969 VCSEC_UWBRearLeftRadioConfigStat 13 "DONE_VERIFYING_RADIO_CONFIG" 12 "WAIT_FOR_LOOPBACK_CALIBRATION" 11 "START_LOOPBACK_CALIBRATION" 10 "WAIT_FOR_PROGRAM_FLASH" 9 "PROGRAM_FLASH" 8 "WAIT_FOR_DOWNLOAD_DATA" 7 "DOWNLOAD_DATA" 6 "WAIT_FOR_INIT_CONFIGURATION" 5 "INIT_CONFIGURATION" 4 "PREPARE_UPDATE" 3 "WAIT_TO_GET_CURRENT_CRC" 2 "GET_CURRENT_CRC" 1 "WAIT_AFTER_TRIGGER" 0 "WAIT_FOR_TRIGGER" ;
VAL_ 969 VCSEC_UWBRearLeftUpdateStatus 3 "IN_PROGRESS" 2 "FAIL" 1 "UP_TO_DATE" 0 "NOT_STARTED" ;
VAL_ 969 VCSEC_UWBRearRadioConfigState 13 "DONE_VERIFYING_RADIO_CONFIG" 12 "WAIT_FOR_LOOPBACK_CALIBRATION" 11 "START_LOOPBACK_CALIBRATION" 10 "WAIT_FOR_PROGRAM_FLASH" 9 "PROGRAM_FLASH" 8 "WAIT_FOR_DOWNLOAD_DATA" 7 "DOWNLOAD_DATA" 6 "WAIT_FOR_INIT_CONFIGURATION" 5 "INIT_CONFIGURATION" 4 "PREPARE_UPDATE" 3 "WAIT_TO_GET_CURRENT_CRC" 2 "GET_CURRENT_CRC" 1 "WAIT_AFTER_TRIGGER" 0 "WAIT_FOR_TRIGGER" ;
VAL_ 969 VCSEC_UWBRearUpdateStatus 3 "IN_PROGRESS" 2 "FAIL" 1 "UP_TO_DATE" 0 "NOT_STARTED" ;
VAL_ 969 VCSEC_UWBLeftRadioConfigState 13 "DONE_VERIFYING_RADIO_CONFIG" 12 "WAIT_FOR_LOOPBACK_CALIBRATION" 11 "START_LOOPBACK_CALIBRATION" 10 "WAIT_FOR_PROGRAM_FLASH" 9 "PROGRAM_FLASH" 8 "WAIT_FOR_DOWNLOAD_DATA" 7 "DOWNLOAD_DATA" 6 "WAIT_FOR_INIT_CONFIGURATION" 5 "INIT_CONFIGURATION" 4 "PREPARE_UPDATE" 3 "WAIT_TO_GET_CURRENT_CRC" 2 "GET_CURRENT_CRC" 1 "WAIT_AFTER_TRIGGER" 0 "WAIT_FOR_TRIGGER" ;
VAL_ 969 VCSEC_UWBLeftUpdateStatus 3 "IN_PROGRESS" 2 "FAIL" 1 "UP_TO_DATE" 0 "NOT_STARTED" ;
VAL_ 969 VCSEC_UWBCenterRadioConfigState 13 "DONE_VERIFYING_RADIO_CONFIG" 12 "WAIT_FOR_LOOPBACK_CALIBRATION" 11 "START_LOOPBACK_CALIBRATION" 10 "WAIT_FOR_PROGRAM_FLASH" 9 "PROGRAM_FLASH" 8 "WAIT_FOR_DOWNLOAD_DATA" 7 "DOWNLOAD_DATA" 6 "WAIT_FOR_INIT_CONFIGURATION" 5 "INIT_CONFIGURATION" 4 "PREPARE_UPDATE" 3 "WAIT_TO_GET_CURRENT_CRC" 2 "GET_CURRENT_CRC" 1 "WAIT_AFTER_TRIGGER" 0 "WAIT_FOR_TRIGGER" ;
VAL_ 969 VCSEC_UWBCenterUpdateStatus 3 "IN_PROGRESS" 2 "FAIL" 1 "UP_TO_DATE" 0 "NOT_STARTED" ;
VAL_ 607 VCSEC_childSeat0_connectionState 5 "DISCONNECTING" 4 "CONNECTED" 3 "WAIT_FOR_CONNECTION" 2 "CONNECTION_REQUEST" 1 "WAIT_FOR_ADV" 0 "INVALID" ;
VAL_ 607 VCSEC_childSeat0_taskDisconnecti 3 "CONNECTION_STATE_MISMATCH" 2 "BAD_CONNECTION_DROPPED" 1 "REQUESTED" 0 "NONE" ;
VAL_ 607 VCSEC_childSeat0_state 8 "DEVICE_READY" 7 "DEVICE_READ_STATUS_WAIT_FOR_RESPONSE" 6 "DEVICE_READ_STATUS" 5 "DEVICE_SIGNUP_NOTIFICATION_WAIT_FOR_RESPONSE" 4 "DEVICE_SIGNUP_NOTIFICATION" 3 "DEVICE_INIT_RESPONSE" 2 "DEVICE_INIT_WAIT_FOR_RESPONSE" 1 "DEVICE_INIT_REQUEST" 0 "DEVICE_IDLE" ;
VAL_ 607 VCSEC_childSeat0_taskErrorCode 4 "TIMEOUT" 3 "READ_STATUS_ERROR" 2 "SIGN_UP_NOTIFICATION_ERROR" 1 "INIT_ERROR" 0 "NONE" ;
VAL_ 607 VCSEC_childSeat0_ISOFixStatus 2 "INSTALLED" 1 "NOT_INSTALLED" 0 "INVALID" ;
VAL_ 607 VCSEC_childSeat0_buckleStatus 2 "BUCKLED" 1 "NOT_BUCKLED" 0 "INVALID" ;
VAL_ 607 VCSEC_childSeat0_occupancyStatus 2 "OCCUPIED" 1 "NOT_OCCUPIED" 0 "INVALID" ;
VAL_ 607 VCSEC_childSeat1_connectionState 5 "DISCONNECTING" 4 "CONNECTED" 3 "WAIT_FOR_CONNECTION" 2 "CONNECTION_REQUEST" 1 "WAIT_FOR_ADV" 0 "INVALID" ;
VAL_ 607 VCSEC_childSeat1_taskDisconnecti 3 "CONNECTION_STATE_MISMATCH" 2 "BAD_CONNECTION_DROPPED" 1 "REQUESTED" 0 "NONE" ;
VAL_ 607 VCSEC_childSeat1_state 8 "DEVICE_READY" 7 "DEVICE_READ_STATUS_WAIT_FOR_RESPONSE" 6 "DEVICE_READ_STATUS" 5 "DEVICE_SIGNUP_NOTIFICATION_WAIT_FOR_RESPONSE" 4 "DEVICE_SIGNUP_NOTIFICATION" 3 "DEVICE_INIT_RESPONSE" 2 "DEVICE_INIT_WAIT_FOR_RESPONSE" 1 "DEVICE_INIT_REQUEST" 0 "DEVICE_IDLE" ;
VAL_ 607 VCSEC_childSeat1_taskErrorCode 4 "TIMEOUT" 3 "READ_STATUS_ERROR" 2 "SIGN_UP_NOTIFICATION_ERROR" 1 "INIT_ERROR" 0 "NONE" ;
VAL_ 607 VCSEC_childSeat1_ISOFixStatus 2 "INSTALLED" 1 "NOT_INSTALLED" 0 "INVALID" ;
VAL_ 607 VCSEC_childSeat1_buckleStatus 2 "BUCKLED" 1 "NOT_BUCKLED" 0 "INVALID" ;
VAL_ 607 VCSEC_childSeat1_occupancyStatus 2 "OCCUPIED" 1 "NOT_OCCUPIED" 0 "INVALID" ;
VAL_ 607 VCSEC_childSeatScanStatus 2 "TIMEOUT" 1 "SCANNING" 0 "IDLE" ;
VAL_ 607 VCSEC_childPresenceDetectionStat 8 "ESCALATED_WARNING" 7 "INTERVENTION" 6 "INITIAL_WARNING" 5 "ARMED" 4 "WAIT_FOR_LOCK" 3 "IDLE" 2 "DEACTIVE" 1 "FAULTED" 0 "NOT_CONFIGURED" ;
VAL_ 607 VCSEC_childPresenceDetectionSupp 2 "EU_REG" 1 "CN_REG" 0 "NONE" ;
VAL_ 857 VCSEC_Device0Formfactor 19 "KEY_FORM_FACTOR_HARMONY_OS_NEXT_DEVICE" 18 "KEY_FORM_FACTOR_NFC_CARD_WATCHDATA_PLASTIC_CARD" 17 "KEY_FORM_FACTOR_APPLE_WATCH" 16 "KEY_FORM_FACTOR_NFC_CARD_IDEMIA_PLASTIC_CARD" 15 "KEY_FORM_FACTOR_NFC_CARD_IDEMIA_METAL_CARD" 14 "KEY_FORM_FACTOR_NFC_CARD_P71" 13 "KEY_FORM_FACTOR_3_BUTTON_GEN2_CAR_KEYFOB_P60_V3" 12 "KEY_FORM_FACTOR_3_BUTTON_GEN2_CAR_KEYFOB_P60_V2" 11 "KEY_FORM_FACTOR_5_BUTTON_GEN2_CAR_KEYFOB_P60" 10 "KEY_FORM_FACTOR_3_BUTTON_GEN2_CAR_KEYFOB_P60" 9 "KEY_FORM_FACTOR_CLOUD_KEY" 8 "KEY_FORM_FACTOR_3_BUTTON_BLE_CAR_KEYFOB_P60" 7 "KEY_FORM_FACTOR_ANDROID_DEVICE" 6 "KEY_FORM_FACTOR_IOS_DEVICE" 5 "KEY_FORM_FACTOR_BLE_AND_NFC_DEVICE" 4 "KEY_FORM_FACTOR_NFC_DEVICE" 3 "KEY_FORM_FACTOR_BLE_DEVICE" 2 "KEY_FORM_FACTOR_3_BUTTON_BLE_CAR_KEYFOB" 1 "KEY_FORM_FACTOR_NFC_CARD" 0 "KEY_FORM_FACTOR_UNKNOWN" ;
VAL_ 857 VCSEC_Device0Role 10 "DEVICE_ROLE_PREDELIVERY_KEY" 9 "DEVICE_ROLE_RIDER_KEY" 8 "DEVICE_ROLE_GUEST_KEY" 7 "DEVICE_ROLE_SERVICE_TECH_KEY" 6 "DEVICE_ROLE_CHARGING_MANAGER_KEY" 5 "DEVICE_ROLE_VEHICLE_MONITOR_KEY" 4 "DEVICE_ROLE_FM_KEY" 3 "DEVICE_ROLE_DRIVER_KEY" 2 "DEVICE_ROLE_OWNER_KEY" 1 "DEVICE_ROLE_SERVICE_KEY" 0 "DEVICE_ROLE_NONE" ;
VAL_ 857 VCSEC_Device1Formfactor 19 "KEY_FORM_FACTOR_HARMONY_OS_NEXT_DEVICE" 18 "KEY_FORM_FACTOR_NFC_CARD_WATCHDATA_PLASTIC_CARD" 17 "KEY_FORM_FACTOR_APPLE_WATCH" 16 "KEY_FORM_FACTOR_NFC_CARD_IDEMIA_PLASTIC_CARD" 15 "KEY_FORM_FACTOR_NFC_CARD_IDEMIA_METAL_CARD" 14 "KEY_FORM_FACTOR_NFC_CARD_P71" 13 "KEY_FORM_FACTOR_3_BUTTON_GEN2_CAR_KEYFOB_P60_V3" 12 "KEY_FORM_FACTOR_3_BUTTON_GEN2_CAR_KEYFOB_P60_V2" 11 "KEY_FORM_FACTOR_5_BUTTON_GEN2_CAR_KEYFOB_P60" 10 "KEY_FORM_FACTOR_3_BUTTON_GEN2_CAR_KEYFOB_P60" 9 "KEY_FORM_FACTOR_CLOUD_KEY" 8 "KEY_FORM_FACTOR_3_BUTTON_BLE_CAR_KEYFOB_P60" 7 "KEY_FORM_FACTOR_ANDROID_DEVICE" 6 "KEY_FORM_FACTOR_IOS_DEVICE" 5 "KEY_FORM_FACTOR_BLE_AND_NFC_DEVICE" 4 "KEY_FORM_FACTOR_NFC_DEVICE" 3 "KEY_FORM_FACTOR_BLE_DEVICE" 2 "KEY_FORM_FACTOR_3_BUTTON_BLE_CAR_KEYFOB" 1 "KEY_FORM_FACTOR_NFC_CARD" 0 "KEY_FORM_FACTOR_UNKNOWN" ;
VAL_ 857 VCSEC_Device1Role 10 "DEVICE_ROLE_PREDELIVERY_KEY" 9 "DEVICE_ROLE_RIDER_KEY" 8 "DEVICE_ROLE_GUEST_KEY" 7 "DEVICE_ROLE_SERVICE_TECH_KEY" 6 "DEVICE_ROLE_CHARGING_MANAGER_KEY" 5 "DEVICE_ROLE_VEHICLE_MONITOR_KEY" 4 "DEVICE_ROLE_FM_KEY" 3 "DEVICE_ROLE_DRIVER_KEY" 2 "DEVICE_ROLE_OWNER_KEY" 1 "DEVICE_ROLE_SERVICE_KEY" 0 "DEVICE_ROLE_NONE" ;
VAL_ 857 VCSEC_Device2Formfactor 19 "KEY_FORM_FACTOR_HARMONY_OS_NEXT_DEVICE" 18 "KEY_FORM_FACTOR_NFC_CARD_WATCHDATA_PLASTIC_CARD" 17 "KEY_FORM_FACTOR_APPLE_WATCH" 16 "KEY_FORM_FACTOR_NFC_CARD_IDEMIA_PLASTIC_CARD" 15 "KEY_FORM_FACTOR_NFC_CARD_IDEMIA_METAL_CARD" 14 "KEY_FORM_FACTOR_NFC_CARD_P71" 13 "KEY_FORM_FACTOR_3_BUTTON_GEN2_CAR_KEYFOB_P60_V3" 12 "KEY_FORM_FACTOR_3_BUTTON_GEN2_CAR_KEYFOB_P60_V2" 11 "KEY_FORM_FACTOR_5_BUTTON_GEN2_CAR_KEYFOB_P60" 10 "KEY_FORM_FACTOR_3_BUTTON_GEN2_CAR_KEYFOB_P60" 9 "KEY_FORM_FACTOR_CLOUD_KEY" 8 "KEY_FORM_FACTOR_3_BUTTON_BLE_CAR_KEYFOB_P60" 7 "KEY_FORM_FACTOR_ANDROID_DEVICE" 6 "KEY_FORM_FACTOR_IOS_DEVICE" 5 "KEY_FORM_FACTOR_BLE_AND_NFC_DEVICE" 4 "KEY_FORM_FACTOR_NFC_DEVICE" 3 "KEY_FORM_FACTOR_BLE_DEVICE" 2 "KEY_FORM_FACTOR_3_BUTTON_BLE_CAR_KEYFOB" 1 "KEY_FORM_FACTOR_NFC_CARD" 0 "KEY_FORM_FACTOR_UNKNOWN" ;
VAL_ 857 VCSEC_Device2Role 10 "DEVICE_ROLE_PREDELIVERY_KEY" 9 "DEVICE_ROLE_RIDER_KEY" 8 "DEVICE_ROLE_GUEST_KEY" 7 "DEVICE_ROLE_SERVICE_TECH_KEY" 6 "DEVICE_ROLE_CHARGING_MANAGER_KEY" 5 "DEVICE_ROLE_VEHICLE_MONITOR_KEY" 4 "DEVICE_ROLE_FM_KEY" 3 "DEVICE_ROLE_DRIVER_KEY" 2 "DEVICE_ROLE_OWNER_KEY" 1 "DEVICE_ROLE_SERVICE_KEY" 0 "DEVICE_ROLE_NONE" ;
VAL_ 857 VCSEC_Device3Formfactor 19 "KEY_FORM_FACTOR_HARMONY_OS_NEXT_DEVICE" 18 "KEY_FORM_FACTOR_NFC_CARD_WATCHDATA_PLASTIC_CARD" 17 "KEY_FORM_FACTOR_APPLE_WATCH" 16 "KEY_FORM_FACTOR_NFC_CARD_IDEMIA_PLASTIC_CARD" 15 "KEY_FORM_FACTOR_NFC_CARD_IDEMIA_METAL_CARD" 14 "KEY_FORM_FACTOR_NFC_CARD_P71" 13 "KEY_FORM_FACTOR_3_BUTTON_GEN2_CAR_KEYFOB_P60_V3" 12 "KEY_FORM_FACTOR_3_BUTTON_GEN2_CAR_KEYFOB_P60_V2" 11 "KEY_FORM_FACTOR_5_BUTTON_GEN2_CAR_KEYFOB_P60" 10 "KEY_FORM_FACTOR_3_BUTTON_GEN2_CAR_KEYFOB_P60" 9 "KEY_FORM_FACTOR_CLOUD_KEY" 8 "KEY_FORM_FACTOR_3_BUTTON_BLE_CAR_KEYFOB_P60" 7 "KEY_FORM_FACTOR_ANDROID_DEVICE" 6 "KEY_FORM_FACTOR_IOS_DEVICE" 5 "KEY_FORM_FACTOR_BLE_AND_NFC_DEVICE" 4 "KEY_FORM_FACTOR_NFC_DEVICE" 3 "KEY_FORM_FACTOR_BLE_DEVICE" 2 "KEY_FORM_FACTOR_3_BUTTON_BLE_CAR_KEYFOB" 1 "KEY_FORM_FACTOR_NFC_CARD" 0 "KEY_FORM_FACTOR_UNKNOWN" ;
VAL_ 857 VCSEC_Device3Role 10 "DEVICE_ROLE_PREDELIVERY_KEY" 9 "DEVICE_ROLE_RIDER_KEY" 8 "DEVICE_ROLE_GUEST_KEY" 7 "DEVICE_ROLE_SERVICE_TECH_KEY" 6 "DEVICE_ROLE_CHARGING_MANAGER_KEY" 5 "DEVICE_ROLE_VEHICLE_MONITOR_KEY" 4 "DEVICE_ROLE_FM_KEY" 3 "DEVICE_ROLE_DRIVER_KEY" 2 "DEVICE_ROLE_OWNER_KEY" 1 "DEVICE_ROLE_SERVICE_KEY" 0 "DEVICE_ROLE_NONE" ;
VAL_ 857 VCSEC_Device4Formfactor 19 "KEY_FORM_FACTOR_HARMONY_OS_NEXT_DEVICE" 18 "KEY_FORM_FACTOR_NFC_CARD_WATCHDATA_PLASTIC_CARD" 17 "KEY_FORM_FACTOR_APPLE_WATCH" 16 "KEY_FORM_FACTOR_NFC_CARD_IDEMIA_PLASTIC_CARD" 15 "KEY_FORM_FACTOR_NFC_CARD_IDEMIA_METAL_CARD" 14 "KEY_FORM_FACTOR_NFC_CARD_P71" 13 "KEY_FORM_FACTOR_3_BUTTON_GEN2_CAR_KEYFOB_P60_V3" 12 "KEY_FORM_FACTOR_3_BUTTON_GEN2_CAR_KEYFOB_P60_V2" 11 "KEY_FORM_FACTOR_5_BUTTON_GEN2_CAR_KEYFOB_P60" 10 "KEY_FORM_FACTOR_3_BUTTON_GEN2_CAR_KEYFOB_P60" 9 "KEY_FORM_FACTOR_CLOUD_KEY" 8 "KEY_FORM_FACTOR_3_BUTTON_BLE_CAR_KEYFOB_P60" 7 "KEY_FORM_FACTOR_ANDROID_DEVICE" 6 "KEY_FORM_FACTOR_IOS_DEVICE" 5 "KEY_FORM_FACTOR_BLE_AND_NFC_DEVICE" 4 "KEY_FORM_FACTOR_NFC_DEVICE" 3 "KEY_FORM_FACTOR_BLE_DEVICE" 2 "KEY_FORM_FACTOR_3_BUTTON_BLE_CAR_KEYFOB" 1 "KEY_FORM_FACTOR_NFC_CARD" 0 "KEY_FORM_FACTOR_UNKNOWN" ;
VAL_ 857 VCSEC_Device4Role 10 "DEVICE_ROLE_PREDELIVERY_KEY" 9 "DEVICE_ROLE_RIDER_KEY" 8 "DEVICE_ROLE_GUEST_KEY" 7 "DEVICE_ROLE_SERVICE_TECH_KEY" 6 "DEVICE_ROLE_CHARGING_MANAGER_KEY" 5 "DEVICE_ROLE_VEHICLE_MONITOR_KEY" 4 "DEVICE_ROLE_FM_KEY" 3 "DEVICE_ROLE_DRIVER_KEY" 2 "DEVICE_ROLE_OWNER_KEY" 1 "DEVICE_ROLE_SERVICE_KEY" 0 "DEVICE_ROLE_NONE" ;
VAL_ 857 VCSEC_Device5Formfactor 19 "KEY_FORM_FACTOR_HARMONY_OS_NEXT_DEVICE" 18 "KEY_FORM_FACTOR_NFC_CARD_WATCHDATA_PLASTIC_CARD" 17 "KEY_FORM_FACTOR_APPLE_WATCH" 16 "KEY_FORM_FACTOR_NFC_CARD_IDEMIA_PLASTIC_CARD" 15 "KEY_FORM_FACTOR_NFC_CARD_IDEMIA_METAL_CARD" 14 "KEY_FORM_FACTOR_NFC_CARD_P71" 13 "KEY_FORM_FACTOR_3_BUTTON_GEN2_CAR_KEYFOB_P60_V3" 12 "KEY_FORM_FACTOR_3_BUTTON_GEN2_CAR_KEYFOB_P60_V2" 11 "KEY_FORM_FACTOR_5_BUTTON_GEN2_CAR_KEYFOB_P60" 10 "KEY_FORM_FACTOR_3_BUTTON_GEN2_CAR_KEYFOB_P60" 9 "KEY_FORM_FACTOR_CLOUD_KEY" 8 "KEY_FORM_FACTOR_3_BUTTON_BLE_CAR_KEYFOB_P60" 7 "KEY_FORM_FACTOR_ANDROID_DEVICE" 6 "KEY_FORM_FACTOR_IOS_DEVICE" 5 "KEY_FORM_FACTOR_BLE_AND_NFC_DEVICE" 4 "KEY_FORM_FACTOR_NFC_DEVICE" 3 "KEY_FORM_FACTOR_BLE_DEVICE" 2 "KEY_FORM_FACTOR_3_BUTTON_BLE_CAR_KEYFOB" 1 "KEY_FORM_FACTOR_NFC_CARD" 0 "KEY_FORM_FACTOR_UNKNOWN" ;
VAL_ 857 VCSEC_Device5Role 10 "DEVICE_ROLE_PREDELIVERY_KEY" 9 "DEVICE_ROLE_RIDER_KEY" 8 "DEVICE_ROLE_GUEST_KEY" 7 "DEVICE_ROLE_SERVICE_TECH_KEY" 6 "DEVICE_ROLE_CHARGING_MANAGER_KEY" 5 "DEVICE_ROLE_VEHICLE_MONITOR_KEY" 4 "DEVICE_ROLE_FM_KEY" 3 "DEVICE_ROLE_DRIVER_KEY" 2 "DEVICE_ROLE_OWNER_KEY" 1 "DEVICE_ROLE_SERVICE_KEY" 0 "DEVICE_ROLE_NONE" ;
VAL_ 857 VCSEC_Device6Formfactor 19 "KEY_FORM_FACTOR_HARMONY_OS_NEXT_DEVICE" 18 "KEY_FORM_FACTOR_NFC_CARD_WATCHDATA_PLASTIC_CARD" 17 "KEY_FORM_FACTOR_APPLE_WATCH" 16 "KEY_FORM_FACTOR_NFC_CARD_IDEMIA_PLASTIC_CARD" 15 "KEY_FORM_FACTOR_NFC_CARD_IDEMIA_METAL_CARD" 14 "KEY_FORM_FACTOR_NFC_CARD_P71" 13 "KEY_FORM_FACTOR_3_BUTTON_GEN2_CAR_KEYFOB_P60_V3" 12 "KEY_FORM_FACTOR_3_BUTTON_GEN2_CAR_KEYFOB_P60_V2" 11 "KEY_FORM_FACTOR_5_BUTTON_GEN2_CAR_KEYFOB_P60" 10 "KEY_FORM_FACTOR_3_BUTTON_GEN2_CAR_KEYFOB_P60" 9 "KEY_FORM_FACTOR_CLOUD_KEY" 8 "KEY_FORM_FACTOR_3_BUTTON_BLE_CAR_KEYFOB_P60" 7 "KEY_FORM_FACTOR_ANDROID_DEVICE" 6 "KEY_FORM_FACTOR_IOS_DEVICE" 5 "KEY_FORM_FACTOR_BLE_AND_NFC_DEVICE" 4 "KEY_FORM_FACTOR_NFC_DEVICE" 3 "KEY_FORM_FACTOR_BLE_DEVICE" 2 "KEY_FORM_FACTOR_3_BUTTON_BLE_CAR_KEYFOB" 1 "KEY_FORM_FACTOR_NFC_CARD" 0 "KEY_FORM_FACTOR_UNKNOWN" ;
VAL_ 857 VCSEC_Device6Role 10 "DEVICE_ROLE_PREDELIVERY_KEY" 9 "DEVICE_ROLE_RIDER_KEY" 8 "DEVICE_ROLE_GUEST_KEY" 7 "DEVICE_ROLE_SERVICE_TECH_KEY" 6 "DEVICE_ROLE_CHARGING_MANAGER_KEY" 5 "DEVICE_ROLE_VEHICLE_MONITOR_KEY" 4 "DEVICE_ROLE_FM_KEY" 3 "DEVICE_ROLE_DRIVER_KEY" 2 "DEVICE_ROLE_OWNER_KEY" 1 "DEVICE_ROLE_SERVICE_KEY" 0 "DEVICE_ROLE_NONE" ;
VAL_ 857 VCSEC_Device7Formfactor 19 "KEY_FORM_FACTOR_HARMONY_OS_NEXT_DEVICE" 18 "KEY_FORM_FACTOR_NFC_CARD_WATCHDATA_PLASTIC_CARD" 17 "KEY_FORM_FACTOR_APPLE_WATCH" 16 "KEY_FORM_FACTOR_NFC_CARD_IDEMIA_PLASTIC_CARD" 15 "KEY_FORM_FACTOR_NFC_CARD_IDEMIA_METAL_CARD" 14 "KEY_FORM_FACTOR_NFC_CARD_P71" 13 "KEY_FORM_FACTOR_3_BUTTON_GEN2_CAR_KEYFOB_P60_V3" 12 "KEY_FORM_FACTOR_3_BUTTON_GEN2_CAR_KEYFOB_P60_V2" 11 "KEY_FORM_FACTOR_5_BUTTON_GEN2_CAR_KEYFOB_P60" 10 "KEY_FORM_FACTOR_3_BUTTON_GEN2_CAR_KEYFOB_P60" 9 "KEY_FORM_FACTOR_CLOUD_KEY" 8 "KEY_FORM_FACTOR_3_BUTTON_BLE_CAR_KEYFOB_P60" 7 "KEY_FORM_FACTOR_ANDROID_DEVICE" 6 "KEY_FORM_FACTOR_IOS_DEVICE" 5 "KEY_FORM_FACTOR_BLE_AND_NFC_DEVICE" 4 "KEY_FORM_FACTOR_NFC_DEVICE" 3 "KEY_FORM_FACTOR_BLE_DEVICE" 2 "KEY_FORM_FACTOR_3_BUTTON_BLE_CAR_KEYFOB" 1 "KEY_FORM_FACTOR_NFC_CARD" 0 "KEY_FORM_FACTOR_UNKNOWN" ;
VAL_ 857 VCSEC_Device7Role 10 "DEVICE_ROLE_PREDELIVERY_KEY" 9 "DEVICE_ROLE_RIDER_KEY" 8 "DEVICE_ROLE_GUEST_KEY" 7 "DEVICE_ROLE_SERVICE_TECH_KEY" 6 "DEVICE_ROLE_CHARGING_MANAGER_KEY" 5 "DEVICE_ROLE_VEHICLE_MONITOR_KEY" 4 "DEVICE_ROLE_FM_KEY" 3 "DEVICE_ROLE_DRIVER_KEY" 2 "DEVICE_ROLE_OWNER_KEY" 1 "DEVICE_ROLE_SERVICE_KEY" 0 "DEVICE_ROLE_NONE" ;
VAL_ 857 VCSEC_Device8Formfactor 19 "KEY_FORM_FACTOR_HARMONY_OS_NEXT_DEVICE" 18 "KEY_FORM_FACTOR_NFC_CARD_WATCHDATA_PLASTIC_CARD" 17 "KEY_FORM_FACTOR_APPLE_WATCH" 16 "KEY_FORM_FACTOR_NFC_CARD_IDEMIA_PLASTIC_CARD" 15 "KEY_FORM_FACTOR_NFC_CARD_IDEMIA_METAL_CARD" 14 "KEY_FORM_FACTOR_NFC_CARD_P71" 13 "KEY_FORM_FACTOR_3_BUTTON_GEN2_CAR_KEYFOB_P60_V3" 12 "KEY_FORM_FACTOR_3_BUTTON_GEN2_CAR_KEYFOB_P60_V2" 11 "KEY_FORM_FACTOR_5_BUTTON_GEN2_CAR_KEYFOB_P60" 10 "KEY_FORM_FACTOR_3_BUTTON_GEN2_CAR_KEYFOB_P60" 9 "KEY_FORM_FACTOR_CLOUD_KEY" 8 "KEY_FORM_FACTOR_3_BUTTON_BLE_CAR_KEYFOB_P60" 7 "KEY_FORM_FACTOR_ANDROID_DEVICE" 6 "KEY_FORM_FACTOR_IOS_DEVICE" 5 "KEY_FORM_FACTOR_BLE_AND_NFC_DEVICE" 4 "KEY_FORM_FACTOR_NFC_DEVICE" 3 "KEY_FORM_FACTOR_BLE_DEVICE" 2 "KEY_FORM_FACTOR_3_BUTTON_BLE_CAR_KEYFOB" 1 "KEY_FORM_FACTOR_NFC_CARD" 0 "KEY_FORM_FACTOR_UNKNOWN" ;
VAL_ 857 VCSEC_Device8Role 10 "DEVICE_ROLE_PREDELIVERY_KEY" 9 "DEVICE_ROLE_RIDER_KEY" 8 "DEVICE_ROLE_GUEST_KEY" 7 "DEVICE_ROLE_SERVICE_TECH_KEY" 6 "DEVICE_ROLE_CHARGING_MANAGER_KEY" 5 "DEVICE_ROLE_VEHICLE_MONITOR_KEY" 4 "DEVICE_ROLE_FM_KEY" 3 "DEVICE_ROLE_DRIVER_KEY" 2 "DEVICE_ROLE_OWNER_KEY" 1 "DEVICE_ROLE_SERVICE_KEY" 0 "DEVICE_ROLE_NONE" ;
VAL_ 857 VCSEC_Device9Formfactor 19 "KEY_FORM_FACTOR_HARMONY_OS_NEXT_DEVICE" 18 "KEY_FORM_FACTOR_NFC_CARD_WATCHDATA_PLASTIC_CARD" 17 "KEY_FORM_FACTOR_APPLE_WATCH" 16 "KEY_FORM_FACTOR_NFC_CARD_IDEMIA_PLASTIC_CARD" 15 "KEY_FORM_FACTOR_NFC_CARD_IDEMIA_METAL_CARD" 14 "KEY_FORM_FACTOR_NFC_CARD_P71" 13 "KEY_FORM_FACTOR_3_BUTTON_GEN2_CAR_KEYFOB_P60_V3" 12 "KEY_FORM_FACTOR_3_BUTTON_GEN2_CAR_KEYFOB_P60_V2" 11 "KEY_FORM_FACTOR_5_BUTTON_GEN2_CAR_KEYFOB_P60" 10 "KEY_FORM_FACTOR_3_BUTTON_GEN2_CAR_KEYFOB_P60" 9 "KEY_FORM_FACTOR_CLOUD_KEY" 8 "KEY_FORM_FACTOR_3_BUTTON_BLE_CAR_KEYFOB_P60" 7 "KEY_FORM_FACTOR_ANDROID_DEVICE" 6 "KEY_FORM_FACTOR_IOS_DEVICE" 5 "KEY_FORM_FACTOR_BLE_AND_NFC_DEVICE" 4 "KEY_FORM_FACTOR_NFC_DEVICE" 3 "KEY_FORM_FACTOR_BLE_DEVICE" 2 "KEY_FORM_FACTOR_3_BUTTON_BLE_CAR_KEYFOB" 1 "KEY_FORM_FACTOR_NFC_CARD" 0 "KEY_FORM_FACTOR_UNKNOWN" ;
VAL_ 857 VCSEC_Device9Role 10 "DEVICE_ROLE_PREDELIVERY_KEY" 9 "DEVICE_ROLE_RIDER_KEY" 8 "DEVICE_ROLE_GUEST_KEY" 7 "DEVICE_ROLE_SERVICE_TECH_KEY" 6 "DEVICE_ROLE_CHARGING_MANAGER_KEY" 5 "DEVICE_ROLE_VEHICLE_MONITOR_KEY" 4 "DEVICE_ROLE_FM_KEY" 3 "DEVICE_ROLE_DRIVER_KEY" 2 "DEVICE_ROLE_OWNER_KEY" 1 "DEVICE_ROLE_SERVICE_KEY" 0 "DEVICE_ROLE_NONE" ;
VAL_ 857 VCSEC_Device10Formfactor 19 "KEY_FORM_FACTOR_HARMONY_OS_NEXT_DEVICE" 18 "KEY_FORM_FACTOR_NFC_CARD_WATCHDATA_PLASTIC_CARD" 17 "KEY_FORM_FACTOR_APPLE_WATCH" 16 "KEY_FORM_FACTOR_NFC_CARD_IDEMIA_PLASTIC_CARD" 15 "KEY_FORM_FACTOR_NFC_CARD_IDEMIA_METAL_CARD" 14 "KEY_FORM_FACTOR_NFC_CARD_P71" 13 "KEY_FORM_FACTOR_3_BUTTON_GEN2_CAR_KEYFOB_P60_V3" 12 "KEY_FORM_FACTOR_3_BUTTON_GEN2_CAR_KEYFOB_P60_V2" 11 "KEY_FORM_FACTOR_5_BUTTON_GEN2_CAR_KEYFOB_P60" 10 "KEY_FORM_FACTOR_3_BUTTON_GEN2_CAR_KEYFOB_P60" 9 "KEY_FORM_FACTOR_CLOUD_KEY" 8 "KEY_FORM_FACTOR_3_BUTTON_BLE_CAR_KEYFOB_P60" 7 "KEY_FORM_FACTOR_ANDROID_DEVICE" 6 "KEY_FORM_FACTOR_IOS_DEVICE" 5 "KEY_FORM_FACTOR_BLE_AND_NFC_DEVICE" 4 "KEY_FORM_FACTOR_NFC_DEVICE" 3 "KEY_FORM_FACTOR_BLE_DEVICE" 2 "KEY_FORM_FACTOR_3_BUTTON_BLE_CAR_KEYFOB" 1 "KEY_FORM_FACTOR_NFC_CARD" 0 "KEY_FORM_FACTOR_UNKNOWN" ;
VAL_ 857 VCSEC_Device10Role 10 "DEVICE_ROLE_PREDELIVERY_KEY" 9 "DEVICE_ROLE_RIDER_KEY" 8 "DEVICE_ROLE_GUEST_KEY" 7 "DEVICE_ROLE_SERVICE_TECH_KEY" 6 "DEVICE_ROLE_CHARGING_MANAGER_KEY" 5 "DEVICE_ROLE_VEHICLE_MONITOR_KEY" 4 "DEVICE_ROLE_FM_KEY" 3 "DEVICE_ROLE_DRIVER_KEY" 2 "DEVICE_ROLE_OWNER_KEY" 1 "DEVICE_ROLE_SERVICE_KEY" 0 "DEVICE_ROLE_NONE" ;
VAL_ 857 VCSEC_Device11Formfactor 19 "KEY_FORM_FACTOR_HARMONY_OS_NEXT_DEVICE" 18 "KEY_FORM_FACTOR_NFC_CARD_WATCHDATA_PLASTIC_CARD" 17 "KEY_FORM_FACTOR_APPLE_WATCH" 16 "KEY_FORM_FACTOR_NFC_CARD_IDEMIA_PLASTIC_CARD" 15 "KEY_FORM_FACTOR_NFC_CARD_IDEMIA_METAL_CARD" 14 "KEY_FORM_FACTOR_NFC_CARD_P71" 13 "KEY_FORM_FACTOR_3_BUTTON_GEN2_CAR_KEYFOB_P60_V3" 12 "KEY_FORM_FACTOR_3_BUTTON_GEN2_CAR_KEYFOB_P60_V2" 11 "KEY_FORM_FACTOR_5_BUTTON_GEN2_CAR_KEYFOB_P60" 10 "KEY_FORM_FACTOR_3_BUTTON_GEN2_CAR_KEYFOB_P60" 9 "KEY_FORM_FACTOR_CLOUD_KEY" 8 "KEY_FORM_FACTOR_3_BUTTON_BLE_CAR_KEYFOB_P60" 7 "KEY_FORM_FACTOR_ANDROID_DEVICE" 6 "KEY_FORM_FACTOR_IOS_DEVICE" 5 "KEY_FORM_FACTOR_BLE_AND_NFC_DEVICE" 4 "KEY_FORM_FACTOR_NFC_DEVICE" 3 "KEY_FORM_FACTOR_BLE_DEVICE" 2 "KEY_FORM_FACTOR_3_BUTTON_BLE_CAR_KEYFOB" 1 "KEY_FORM_FACTOR_NFC_CARD" 0 "KEY_FORM_FACTOR_UNKNOWN" ;
VAL_ 857 VCSEC_Device11Role 10 "DEVICE_ROLE_PREDELIVERY_KEY" 9 "DEVICE_ROLE_RIDER_KEY" 8 "DEVICE_ROLE_GUEST_KEY" 7 "DEVICE_ROLE_SERVICE_TECH_KEY" 6 "DEVICE_ROLE_CHARGING_MANAGER_KEY" 5 "DEVICE_ROLE_VEHICLE_MONITOR_KEY" 4 "DEVICE_ROLE_FM_KEY" 3 "DEVICE_ROLE_DRIVER_KEY" 2 "DEVICE_ROLE_OWNER_KEY" 1 "DEVICE_ROLE_SERVICE_KEY" 0 "DEVICE_ROLE_NONE" ;
VAL_ 857 VCSEC_Device12Formfactor 19 "KEY_FORM_FACTOR_HARMONY_OS_NEXT_DEVICE" 18 "KEY_FORM_FACTOR_NFC_CARD_WATCHDATA_PLASTIC_CARD" 17 "KEY_FORM_FACTOR_APPLE_WATCH" 16 "KEY_FORM_FACTOR_NFC_CARD_IDEMIA_PLASTIC_CARD" 15 "KEY_FORM_FACTOR_NFC_CARD_IDEMIA_METAL_CARD" 14 "KEY_FORM_FACTOR_NFC_CARD_P71" 13 "KEY_FORM_FACTOR_3_BUTTON_GEN2_CAR_KEYFOB_P60_V3" 12 "KEY_FORM_FACTOR_3_BUTTON_GEN2_CAR_KEYFOB_P60_V2" 11 "KEY_FORM_FACTOR_5_BUTTON_GEN2_CAR_KEYFOB_P60" 10 "KEY_FORM_FACTOR_3_BUTTON_GEN2_CAR_KEYFOB_P60" 9 "KEY_FORM_FACTOR_CLOUD_KEY" 8 "KEY_FORM_FACTOR_3_BUTTON_BLE_CAR_KEYFOB_P60" 7 "KEY_FORM_FACTOR_ANDROID_DEVICE" 6 "KEY_FORM_FACTOR_IOS_DEVICE" 5 "KEY_FORM_FACTOR_BLE_AND_NFC_DEVICE" 4 "KEY_FORM_FACTOR_NFC_DEVICE" 3 "KEY_FORM_FACTOR_BLE_DEVICE" 2 "KEY_FORM_FACTOR_3_BUTTON_BLE_CAR_KEYFOB" 1 "KEY_FORM_FACTOR_NFC_CARD" 0 "KEY_FORM_FACTOR_UNKNOWN" ;
VAL_ 857 VCSEC_Device12Role 10 "DEVICE_ROLE_PREDELIVERY_KEY" 9 "DEVICE_ROLE_RIDER_KEY" 8 "DEVICE_ROLE_GUEST_KEY" 7 "DEVICE_ROLE_SERVICE_TECH_KEY" 6 "DEVICE_ROLE_CHARGING_MANAGER_KEY" 5 "DEVICE_ROLE_VEHICLE_MONITOR_KEY" 4 "DEVICE_ROLE_FM_KEY" 3 "DEVICE_ROLE_DRIVER_KEY" 2 "DEVICE_ROLE_OWNER_KEY" 1 "DEVICE_ROLE_SERVICE_KEY" 0 "DEVICE_ROLE_NONE" ;
VAL_ 857 VCSEC_Device13Formfactor 19 "KEY_FORM_FACTOR_HARMONY_OS_NEXT_DEVICE" 18 "KEY_FORM_FACTOR_NFC_CARD_WATCHDATA_PLASTIC_CARD" 17 "KEY_FORM_FACTOR_APPLE_WATCH" 16 "KEY_FORM_FACTOR_NFC_CARD_IDEMIA_PLASTIC_CARD" 15 "KEY_FORM_FACTOR_NFC_CARD_IDEMIA_METAL_CARD" 14 "KEY_FORM_FACTOR_NFC_CARD_P71" 13 "KEY_FORM_FACTOR_3_BUTTON_GEN2_CAR_KEYFOB_P60_V3" 12 "KEY_FORM_FACTOR_3_BUTTON_GEN2_CAR_KEYFOB_P60_V2" 11 "KEY_FORM_FACTOR_5_BUTTON_GEN2_CAR_KEYFOB_P60" 10 "KEY_FORM_FACTOR_3_BUTTON_GEN2_CAR_KEYFOB_P60" 9 "KEY_FORM_FACTOR_CLOUD_KEY" 8 "KEY_FORM_FACTOR_3_BUTTON_BLE_CAR_KEYFOB_P60" 7 "KEY_FORM_FACTOR_ANDROID_DEVICE" 6 "KEY_FORM_FACTOR_IOS_DEVICE" 5 "KEY_FORM_FACTOR_BLE_AND_NFC_DEVICE" 4 "KEY_FORM_FACTOR_NFC_DEVICE" 3 "KEY_FORM_FACTOR_BLE_DEVICE" 2 "KEY_FORM_FACTOR_3_BUTTON_BLE_CAR_KEYFOB" 1 "KEY_FORM_FACTOR_NFC_CARD" 0 "KEY_FORM_FACTOR_UNKNOWN" ;
VAL_ 857 VCSEC_Device13Role 10 "DEVICE_ROLE_PREDELIVERY_KEY" 9 "DEVICE_ROLE_RIDER_KEY" 8 "DEVICE_ROLE_GUEST_KEY" 7 "DEVICE_ROLE_SERVICE_TECH_KEY" 6 "DEVICE_ROLE_CHARGING_MANAGER_KEY" 5 "DEVICE_ROLE_VEHICLE_MONITOR_KEY" 4 "DEVICE_ROLE_FM_KEY" 3 "DEVICE_ROLE_DRIVER_KEY" 2 "DEVICE_ROLE_OWNER_KEY" 1 "DEVICE_ROLE_SERVICE_KEY" 0 "DEVICE_ROLE_NONE" ;
VAL_ 857 VCSEC_Device14Formfactor 19 "KEY_FORM_FACTOR_HARMONY_OS_NEXT_DEVICE" 18 "KEY_FORM_FACTOR_NFC_CARD_WATCHDATA_PLASTIC_CARD" 17 "KEY_FORM_FACTOR_APPLE_WATCH" 16 "KEY_FORM_FACTOR_NFC_CARD_IDEMIA_PLASTIC_CARD" 15 "KEY_FORM_FACTOR_NFC_CARD_IDEMIA_METAL_CARD" 14 "KEY_FORM_FACTOR_NFC_CARD_P71" 13 "KEY_FORM_FACTOR_3_BUTTON_GEN2_CAR_KEYFOB_P60_V3" 12 "KEY_FORM_FACTOR_3_BUTTON_GEN2_CAR_KEYFOB_P60_V2" 11 "KEY_FORM_FACTOR_5_BUTTON_GEN2_CAR_KEYFOB_P60" 10 "KEY_FORM_FACTOR_3_BUTTON_GEN2_CAR_KEYFOB_P60" 9 "KEY_FORM_FACTOR_CLOUD_KEY" 8 "KEY_FORM_FACTOR_3_BUTTON_BLE_CAR_KEYFOB_P60" 7 "KEY_FORM_FACTOR_ANDROID_DEVICE" 6 "KEY_FORM_FACTOR_IOS_DEVICE" 5 "KEY_FORM_FACTOR_BLE_AND_NFC_DEVICE" 4 "KEY_FORM_FACTOR_NFC_DEVICE" 3 "KEY_FORM_FACTOR_BLE_DEVICE" 2 "KEY_FORM_FACTOR_3_BUTTON_BLE_CAR_KEYFOB" 1 "KEY_FORM_FACTOR_NFC_CARD" 0 "KEY_FORM_FACTOR_UNKNOWN" ;
VAL_ 857 VCSEC_Device14Role 10 "DEVICE_ROLE_PREDELIVERY_KEY" 9 "DEVICE_ROLE_RIDER_KEY" 8 "DEVICE_ROLE_GUEST_KEY" 7 "DEVICE_ROLE_SERVICE_TECH_KEY" 6 "DEVICE_ROLE_CHARGING_MANAGER_KEY" 5 "DEVICE_ROLE_VEHICLE_MONITOR_KEY" 4 "DEVICE_ROLE_FM_KEY" 3 "DEVICE_ROLE_DRIVER_KEY" 2 "DEVICE_ROLE_OWNER_KEY" 1 "DEVICE_ROLE_SERVICE_KEY" 0 "DEVICE_ROLE_NONE" ;
VAL_ 857 VCSEC_Device15Formfactor 19 "KEY_FORM_FACTOR_HARMONY_OS_NEXT_DEVICE" 18 "KEY_FORM_FACTOR_NFC_CARD_WATCHDATA_PLASTIC_CARD" 17 "KEY_FORM_FACTOR_APPLE_WATCH" 16 "KEY_FORM_FACTOR_NFC_CARD_IDEMIA_PLASTIC_CARD" 15 "KEY_FORM_FACTOR_NFC_CARD_IDEMIA_METAL_CARD" 14 "KEY_FORM_FACTOR_NFC_CARD_P71" 13 "KEY_FORM_FACTOR_3_BUTTON_GEN2_CAR_KEYFOB_P60_V3" 12 "KEY_FORM_FACTOR_3_BUTTON_GEN2_CAR_KEYFOB_P60_V2" 11 "KEY_FORM_FACTOR_5_BUTTON_GEN2_CAR_KEYFOB_P60" 10 "KEY_FORM_FACTOR_3_BUTTON_GEN2_CAR_KEYFOB_P60" 9 "KEY_FORM_FACTOR_CLOUD_KEY" 8 "KEY_FORM_FACTOR_3_BUTTON_BLE_CAR_KEYFOB_P60" 7 "KEY_FORM_FACTOR_ANDROID_DEVICE" 6 "KEY_FORM_FACTOR_IOS_DEVICE" 5 "KEY_FORM_FACTOR_BLE_AND_NFC_DEVICE" 4 "KEY_FORM_FACTOR_NFC_DEVICE" 3 "KEY_FORM_FACTOR_BLE_DEVICE" 2 "KEY_FORM_FACTOR_3_BUTTON_BLE_CAR_KEYFOB" 1 "KEY_FORM_FACTOR_NFC_CARD" 0 "KEY_FORM_FACTOR_UNKNOWN" ;
VAL_ 857 VCSEC_Device15Role 10 "DEVICE_ROLE_PREDELIVERY_KEY" 9 "DEVICE_ROLE_RIDER_KEY" 8 "DEVICE_ROLE_GUEST_KEY" 7 "DEVICE_ROLE_SERVICE_TECH_KEY" 6 "DEVICE_ROLE_CHARGING_MANAGER_KEY" 5 "DEVICE_ROLE_VEHICLE_MONITOR_KEY" 4 "DEVICE_ROLE_FM_KEY" 3 "DEVICE_ROLE_DRIVER_KEY" 2 "DEVICE_ROLE_OWNER_KEY" 1 "DEVICE_ROLE_SERVICE_KEY" 0 "DEVICE_ROLE_NONE" ;
VAL_ 857 VCSEC_Device16Formfactor 19 "KEY_FORM_FACTOR_HARMONY_OS_NEXT_DEVICE" 18 "KEY_FORM_FACTOR_NFC_CARD_WATCHDATA_PLASTIC_CARD" 17 "KEY_FORM_FACTOR_APPLE_WATCH" 16 "KEY_FORM_FACTOR_NFC_CARD_IDEMIA_PLASTIC_CARD" 15 "KEY_FORM_FACTOR_NFC_CARD_IDEMIA_METAL_CARD" 14 "KEY_FORM_FACTOR_NFC_CARD_P71" 13 "KEY_FORM_FACTOR_3_BUTTON_GEN2_CAR_KEYFOB_P60_V3" 12 "KEY_FORM_FACTOR_3_BUTTON_GEN2_CAR_KEYFOB_P60_V2" 11 "KEY_FORM_FACTOR_5_BUTTON_GEN2_CAR_KEYFOB_P60" 10 "KEY_FORM_FACTOR_3_BUTTON_GEN2_CAR_KEYFOB_P60" 9 "KEY_FORM_FACTOR_CLOUD_KEY" 8 "KEY_FORM_FACTOR_3_BUTTON_BLE_CAR_KEYFOB_P60" 7 "KEY_FORM_FACTOR_ANDROID_DEVICE" 6 "KEY_FORM_FACTOR_IOS_DEVICE" 5 "KEY_FORM_FACTOR_BLE_AND_NFC_DEVICE" 4 "KEY_FORM_FACTOR_NFC_DEVICE" 3 "KEY_FORM_FACTOR_BLE_DEVICE" 2 "KEY_FORM_FACTOR_3_BUTTON_BLE_CAR_KEYFOB" 1 "KEY_FORM_FACTOR_NFC_CARD" 0 "KEY_FORM_FACTOR_UNKNOWN" ;
VAL_ 857 VCSEC_Device16Role 10 "DEVICE_ROLE_PREDELIVERY_KEY" 9 "DEVICE_ROLE_RIDER_KEY" 8 "DEVICE_ROLE_GUEST_KEY" 7 "DEVICE_ROLE_SERVICE_TECH_KEY" 6 "DEVICE_ROLE_CHARGING_MANAGER_KEY" 5 "DEVICE_ROLE_VEHICLE_MONITOR_KEY" 4 "DEVICE_ROLE_FM_KEY" 3 "DEVICE_ROLE_DRIVER_KEY" 2 "DEVICE_ROLE_OWNER_KEY" 1 "DEVICE_ROLE_SERVICE_KEY" 0 "DEVICE_ROLE_NONE" ;
VAL_ 857 VCSEC_Device17Formfactor 19 "KEY_FORM_FACTOR_HARMONY_OS_NEXT_DEVICE" 18 "KEY_FORM_FACTOR_NFC_CARD_WATCHDATA_PLASTIC_CARD" 17 "KEY_FORM_FACTOR_APPLE_WATCH" 16 "KEY_FORM_FACTOR_NFC_CARD_IDEMIA_PLASTIC_CARD" 15 "KEY_FORM_FACTOR_NFC_CARD_IDEMIA_METAL_CARD" 14 "KEY_FORM_FACTOR_NFC_CARD_P71" 13 "KEY_FORM_FACTOR_3_BUTTON_GEN2_CAR_KEYFOB_P60_V3" 12 "KEY_FORM_FACTOR_3_BUTTON_GEN2_CAR_KEYFOB_P60_V2" 11 "KEY_FORM_FACTOR_5_BUTTON_GEN2_CAR_KEYFOB_P60" 10 "KEY_FORM_FACTOR_3_BUTTON_GEN2_CAR_KEYFOB_P60" 9 "KEY_FORM_FACTOR_CLOUD_KEY" 8 "KEY_FORM_FACTOR_3_BUTTON_BLE_CAR_KEYFOB_P60" 7 "KEY_FORM_FACTOR_ANDROID_DEVICE" 6 "KEY_FORM_FACTOR_IOS_DEVICE" 5 "KEY_FORM_FACTOR_BLE_AND_NFC_DEVICE" 4 "KEY_FORM_FACTOR_NFC_DEVICE" 3 "KEY_FORM_FACTOR_BLE_DEVICE" 2 "KEY_FORM_FACTOR_3_BUTTON_BLE_CAR_KEYFOB" 1 "KEY_FORM_FACTOR_NFC_CARD" 0 "KEY_FORM_FACTOR_UNKNOWN" ;
VAL_ 857 VCSEC_Device17Role 10 "DEVICE_ROLE_PREDELIVERY_KEY" 9 "DEVICE_ROLE_RIDER_KEY" 8 "DEVICE_ROLE_GUEST_KEY" 7 "DEVICE_ROLE_SERVICE_TECH_KEY" 6 "DEVICE_ROLE_CHARGING_MANAGER_KEY" 5 "DEVICE_ROLE_VEHICLE_MONITOR_KEY" 4 "DEVICE_ROLE_FM_KEY" 3 "DEVICE_ROLE_DRIVER_KEY" 2 "DEVICE_ROLE_OWNER_KEY" 1 "DEVICE_ROLE_SERVICE_KEY" 0 "DEVICE_ROLE_NONE" ;
VAL_ 857 VCSEC_Device18Formfactor 19 "KEY_FORM_FACTOR_HARMONY_OS_NEXT_DEVICE" 18 "KEY_FORM_FACTOR_NFC_CARD_WATCHDATA_PLASTIC_CARD" 17 "KEY_FORM_FACTOR_APPLE_WATCH" 16 "KEY_FORM_FACTOR_NFC_CARD_IDEMIA_PLASTIC_CARD" 15 "KEY_FORM_FACTOR_NFC_CARD_IDEMIA_METAL_CARD" 14 "KEY_FORM_FACTOR_NFC_CARD_P71" 13 "KEY_FORM_FACTOR_3_BUTTON_GEN2_CAR_KEYFOB_P60_V3" 12 "KEY_FORM_FACTOR_3_BUTTON_GEN2_CAR_KEYFOB_P60_V2" 11 "KEY_FORM_FACTOR_5_BUTTON_GEN2_CAR_KEYFOB_P60" 10 "KEY_FORM_FACTOR_3_BUTTON_GEN2_CAR_KEYFOB_P60" 9 "KEY_FORM_FACTOR_CLOUD_KEY" 8 "KEY_FORM_FACTOR_3_BUTTON_BLE_CAR_KEYFOB_P60" 7 "KEY_FORM_FACTOR_ANDROID_DEVICE" 6 "KEY_FORM_FACTOR_IOS_DEVICE" 5 "KEY_FORM_FACTOR_BLE_AND_NFC_DEVICE" 4 "KEY_FORM_FACTOR_NFC_DEVICE" 3 "KEY_FORM_FACTOR_BLE_DEVICE" 2 "KEY_FORM_FACTOR_3_BUTTON_BLE_CAR_KEYFOB" 1 "KEY_FORM_FACTOR_NFC_CARD" 0 "KEY_FORM_FACTOR_UNKNOWN" ;
VAL_ 857 VCSEC_Device18Role 10 "DEVICE_ROLE_PREDELIVERY_KEY" 9 "DEVICE_ROLE_RIDER_KEY" 8 "DEVICE_ROLE_GUEST_KEY" 7 "DEVICE_ROLE_SERVICE_TECH_KEY" 6 "DEVICE_ROLE_CHARGING_MANAGER_KEY" 5 "DEVICE_ROLE_VEHICLE_MONITOR_KEY" 4 "DEVICE_ROLE_FM_KEY" 3 "DEVICE_ROLE_DRIVER_KEY" 2 "DEVICE_ROLE_OWNER_KEY" 1 "DEVICE_ROLE_SERVICE_KEY" 0 "DEVICE_ROLE_NONE" ;
VAL_ 857 VCSEC_Device19Formfactor 19 "KEY_FORM_FACTOR_HARMONY_OS_NEXT_DEVICE" 18 "KEY_FORM_FACTOR_NFC_CARD_WATCHDATA_PLASTIC_CARD" 17 "KEY_FORM_FACTOR_APPLE_WATCH" 16 "KEY_FORM_FACTOR_NFC_CARD_IDEMIA_PLASTIC_CARD" 15 "KEY_FORM_FACTOR_NFC_CARD_IDEMIA_METAL_CARD" 14 "KEY_FORM_FACTOR_NFC_CARD_P71" 13 "KEY_FORM_FACTOR_3_BUTTON_GEN2_CAR_KEYFOB_P60_V3" 12 "KEY_FORM_FACTOR_3_BUTTON_GEN2_CAR_KEYFOB_P60_V2" 11 "KEY_FORM_FACTOR_5_BUTTON_GEN2_CAR_KEYFOB_P60" 10 "KEY_FORM_FACTOR_3_BUTTON_GEN2_CAR_KEYFOB_P60" 9 "KEY_FORM_FACTOR_CLOUD_KEY" 8 "KEY_FORM_FACTOR_3_BUTTON_BLE_CAR_KEYFOB_P60" 7 "KEY_FORM_FACTOR_ANDROID_DEVICE" 6 "KEY_FORM_FACTOR_IOS_DEVICE" 5 "KEY_FORM_FACTOR_BLE_AND_NFC_DEVICE" 4 "KEY_FORM_FACTOR_NFC_DEVICE" 3 "KEY_FORM_FACTOR_BLE_DEVICE" 2 "KEY_FORM_FACTOR_3_BUTTON_BLE_CAR_KEYFOB" 1 "KEY_FORM_FACTOR_NFC_CARD" 0 "KEY_FORM_FACTOR_UNKNOWN" ;
VAL_ 857 VCSEC_Device19Role 10 "DEVICE_ROLE_PREDELIVERY_KEY" 9 "DEVICE_ROLE_RIDER_KEY" 8 "DEVICE_ROLE_GUEST_KEY" 7 "DEVICE_ROLE_SERVICE_TECH_KEY" 6 "DEVICE_ROLE_CHARGING_MANAGER_KEY" 5 "DEVICE_ROLE_VEHICLE_MONITOR_KEY" 4 "DEVICE_ROLE_FM_KEY" 3 "DEVICE_ROLE_DRIVER_KEY" 2 "DEVICE_ROLE_OWNER_KEY" 1 "DEVICE_ROLE_SERVICE_KEY" 0 "DEVICE_ROLE_NONE" ;
VAL_ 1066 VCSEC_TPMSSensorState0 5 "SENSOR_WAIT_FOR_NEXT_ADV" 4 "SENSOR_DISCONNECTING" 3 "SENSOR_CONNECTED" 2 "SENSOR_WAIT_FOR_CONN" 1 "SENSOR_WAIT_FOR_ADV" 0 "SENSOR_NOT_PAIRED" ;
VAL_ 1066 VCSEC_TPMSConnectionTypeCurrent0 3 "CONNECTIONTYPE_FAST_SLAVE_LATENCY" 2 "CONNECTIONTYPE_UNKNOWN" 1 "CONNECTIONTYPE_SLOW" 0 "CONNECTIONTYPE_FAST" ;
VAL_ 1066 VCSEC_TPMSConnectionTypeDesired0 3 "CONNECTIONTYPE_FAST_SLAVE_LATENCY" 2 "CONNECTIONTYPE_UNKNOWN" 1 "CONNECTIONTYPE_SLOW" 0 "CONNECTIONTYPE_FAST" ;
VAL_ 1066 VCSEC_TPMSSensorState1 5 "SENSOR_WAIT_FOR_NEXT_ADV" 4 "SENSOR_DISCONNECTING" 3 "SENSOR_CONNECTED" 2 "SENSOR_WAIT_FOR_CONN" 1 "SENSOR_WAIT_FOR_ADV" 0 "SENSOR_NOT_PAIRED" ;
VAL_ 1066 VCSEC_TPMSConnectionTypeCurrent1 3 "CONNECTIONTYPE_FAST_SLAVE_LATENCY" 2 "CONNECTIONTYPE_UNKNOWN" 1 "CONNECTIONTYPE_SLOW" 0 "CONNECTIONTYPE_FAST" ;
VAL_ 1066 VCSEC_TPMSConnectionTypeDesired1 3 "CONNECTIONTYPE_FAST_SLAVE_LATENCY" 2 "CONNECTIONTYPE_UNKNOWN" 1 "CONNECTIONTYPE_SLOW" 0 "CONNECTIONTYPE_FAST" ;
VAL_ 1066 VCSEC_TPMSSensorState2 5 "SENSOR_WAIT_FOR_NEXT_ADV" 4 "SENSOR_DISCONNECTING" 3 "SENSOR_CONNECTED" 2 "SENSOR_WAIT_FOR_CONN" 1 "SENSOR_WAIT_FOR_ADV" 0 "SENSOR_NOT_PAIRED" ;
VAL_ 1066 VCSEC_TPMSConnectionTypeCurrent2 3 "CONNECTIONTYPE_FAST_SLAVE_LATENCY" 2 "CONNECTIONTYPE_UNKNOWN" 1 "CONNECTIONTYPE_SLOW" 0 "CONNECTIONTYPE_FAST" ;
VAL_ 1066 VCSEC_TPMSConnectionTypeDesired2 3 "CONNECTIONTYPE_FAST_SLAVE_LATENCY" 2 "CONNECTIONTYPE_UNKNOWN" 1 "CONNECTIONTYPE_SLOW" 0 "CONNECTIONTYPE_FAST" ;
VAL_ 1066 VCSEC_TPMSSensorState3 5 "SENSOR_WAIT_FOR_NEXT_ADV" 4 "SENSOR_DISCONNECTING" 3 "SENSOR_CONNECTED" 2 "SENSOR_WAIT_FOR_CONN" 1 "SENSOR_WAIT_FOR_ADV" 0 "SENSOR_NOT_PAIRED" ;
VAL_ 1066 VCSEC_TPMSConnectionTypeCurrent3 3 "CONNECTIONTYPE_FAST_SLAVE_LATENCY" 2 "CONNECTIONTYPE_UNKNOWN" 1 "CONNECTIONTYPE_SLOW" 0 "CONNECTIONTYPE_FAST" ;
VAL_ 1066 VCSEC_TPMSConnectionTypeDesired3 3 "CONNECTIONTYPE_FAST_SLAVE_LATENCY" 2 "CONNECTIONTYPE_UNKNOWN" 1 "CONNECTIONTYPE_SLOW" 0 "CONNECTIONTYPE_FAST" ;
VAL_ 1066 VCSEC_TPMSSensorPresence0 2 "PRESENT" 1 "NOT_PRESENT" 0 "NOT_PAIRED" ;
VAL_ 1066 VCSEC_TPMSSensorPresence1 2 "PRESENT" 1 "NOT_PRESENT" 0 "NOT_PAIRED" ;
VAL_ 1066 VCSEC_TPMSSensorPresence2 2 "PRESENT" 1 "NOT_PRESENT" 0 "NOT_PAIRED" ;
VAL_ 1066 VCSEC_TPMSSensorPresence3 2 "PRESENT" 1 "NOT_PRESENT" 0 "NOT_PAIRED" ;
VAL_ 537 VCSEC_TPMSLocation0 4 "LOCATION_UNKNOWN" 3 "LOCATION_RR" 2 "LOCATION_RL" 1 "LOCATION_FR" 0 "LOCATION_FL" ;
VAL_ 537 VCSEC_TPMSLocation1 4 "LOCATION_UNKNOWN" 3 "LOCATION_RR" 2 "LOCATION_RL" 1 "LOCATION_FR" 0 "LOCATION_FL" ;
VAL_ 537 VCSEC_TPMSLocation2 4 "LOCATION_UNKNOWN" 3 "LOCATION_RR" 2 "LOCATION_RL" 1 "LOCATION_FR" 0 "LOCATION_FL" ;
VAL_ 537 VCSEC_TPMSLocation3 4 "LOCATION_UNKNOWN" 3 "LOCATION_RR" 2 "LOCATION_RL" 1 "LOCATION_FR" 0 "LOCATION_FL" ;
VAL_ 537 VCSEC_TPMSFeature0 6 "FEATURE_0_BLOCKED" 5 "FEATURE_0_ACTIVE" 4 "FEATURE_0_READY" 3 "FEATURE_0_WAIT_FOR_STATIONARY" 2 "FEATURE_0_UNAVAILABLE_2" 1 "FEATURE_0_UNAVAILABLE_1" 0 "FEATURE_0_NOT_SUPPORTED" ;
VAL_ 537 VCSEC_TPMSFeature1 5 "FEATURE_1_CLOSE" 4 "FEATURE_1_MEDIUM" 3 "FEATURE_1_FAR_AWAY" 2 "FEATURE_1_INCORRECT" 1 "FEATURE_1_REACHED" 0 "FEATURE_1_NONE" ;
VAL_ 602 VCSEC_TPMSTellTale 2 "TPMS_TELLTALE_FLASHING" 1 "TPMS_TELLTALE_SOLID" 0 "TPMS_TELLTALE_OFF" ;
VAL_ 602 VCSEC_TPMSDisplaySoftWarningIndi 1 "TPMS_PRESSUREWARNING_INDICATED" 0 "TPMS_PRESSUREWARNING_NOT_INDICATED" ;
VAL_ 602 VCSEC_TPMSDisplaySoftWarnin_0001 1 "TPMS_PRESSUREWARNING_INDICATED" 0 "TPMS_PRESSUREWARNING_NOT_INDICATED" ;
VAL_ 602 VCSEC_TPMSDisplaySoftWarnin_0002 1 "TPMS_PRESSUREWARNING_INDICATED" 0 "TPMS_PRESSUREWARNING_NOT_INDICATED" ;
VAL_ 602 VCSEC_TPMSDisplaySoftWarnin_0003 1 "TPMS_PRESSUREWARNING_INDICATED" 0 "TPMS_PRESSUREWARNING_NOT_INDICATED" ;
VAL_ 602 VCSEC_TPMSDisplayHardWarningIndi 1 "TPMS_PRESSUREWARNING_INDICATED" 0 "TPMS_PRESSUREWARNING_NOT_INDICATED" ;
VAL_ 602 VCSEC_TPMSDisplayHardWarnin_0001 1 "TPMS_PRESSUREWARNING_INDICATED" 0 "TPMS_PRESSUREWARNING_NOT_INDICATED" ;
VAL_ 602 VCSEC_TPMSDisplayHardWarnin_0002 1 "TPMS_PRESSUREWARNING_INDICATED" 0 "TPMS_PRESSUREWARNING_NOT_INDICATED" ;
VAL_ 602 VCSEC_TPMSDisplayHardWarnin_0003 1 "TPMS_PRESSUREWARNING_INDICATED" 0 "TPMS_PRESSUREWARNING_NOT_INDICATED" ;
VAL_ 570 VCSEC_TPMSSystemState 1 "TPMS_SYSTEM_STATE_ACTIVE" 0 "TPMS_SYSTEM_STATE_IDLE" ;
VAL_ 570 VCSEC_TPMSGenealogySensorState0 7 "SENSOR_STATE_DONE" 6 "SENSOR_STATE_WAIT_FOR_CAPABILITIES_RESPONSE" 5 "SENSOR_STATE_SEND_CAPABILITIES_REQUEST" 4 "SENSOR_STATE_WAIT_FOR_GENEALOGY_RESPONSE" 3 "SENSOR_STATE_SEND_GENEALOGY_REQUEST" 2 "SENSOR_STATE_WAIT_FOR_CODE_DESCRIPTOR_RESPONSE" 1 "SENSOR_STATE_SEND_CODE_DESCRIPTOR_REQUEST" 0 "SENSOR_STATE_WAIT_FOR_CONNECTION" ;
VAL_ 570 VCSEC_TPMSSensorType0 6 "SENSOR_TYPE_V5" 5 "SENSOR_TYPE_V4" 4 "SENSOR_TYPE_V3" 3 "SENSOR_TYPE_V2" 2 "SENSOR_TYPE_V1" 1 "SENSOR_TYPE_UNKNOWN" 0 "SENSOR_TYPE_NOT_IDENTIFIED" ;
VAL_ 570 VCSEC_TPMSGenealogySensorState1 7 "SENSOR_STATE_DONE" 6 "SENSOR_STATE_WAIT_FOR_CAPABILITIES_RESPONSE" 5 "SENSOR_STATE_SEND_CAPABILITIES_REQUEST" 4 "SENSOR_STATE_WAIT_FOR_GENEALOGY_RESPONSE" 3 "SENSOR_STATE_SEND_GENEALOGY_REQUEST" 2 "SENSOR_STATE_WAIT_FOR_CODE_DESCRIPTOR_RESPONSE" 1 "SENSOR_STATE_SEND_CODE_DESCRIPTOR_REQUEST" 0 "SENSOR_STATE_WAIT_FOR_CONNECTION" ;
VAL_ 570 VCSEC_TPMSSensorType1 6 "SENSOR_TYPE_V5" 5 "SENSOR_TYPE_V4" 4 "SENSOR_TYPE_V3" 3 "SENSOR_TYPE_V2" 2 "SENSOR_TYPE_V1" 1 "SENSOR_TYPE_UNKNOWN" 0 "SENSOR_TYPE_NOT_IDENTIFIED" ;
VAL_ 570 VCSEC_TPMSGenealogySensorState2 7 "SENSOR_STATE_DONE" 6 "SENSOR_STATE_WAIT_FOR_CAPABILITIES_RESPONSE" 5 "SENSOR_STATE_SEND_CAPABILITIES_REQUEST" 4 "SENSOR_STATE_WAIT_FOR_GENEALOGY_RESPONSE" 3 "SENSOR_STATE_SEND_GENEALOGY_REQUEST" 2 "SENSOR_STATE_WAIT_FOR_CODE_DESCRIPTOR_RESPONSE" 1 "SENSOR_STATE_SEND_CODE_DESCRIPTOR_REQUEST" 0 "SENSOR_STATE_WAIT_FOR_CONNECTION" ;
VAL_ 570 VCSEC_TPMSSensorType2 6 "SENSOR_TYPE_V5" 5 "SENSOR_TYPE_V4" 4 "SENSOR_TYPE_V3" 3 "SENSOR_TYPE_V2" 2 "SENSOR_TYPE_V1" 1 "SENSOR_TYPE_UNKNOWN" 0 "SENSOR_TYPE_NOT_IDENTIFIED" ;
VAL_ 570 VCSEC_TPMSGenealogySensorState3 7 "SENSOR_STATE_DONE" 6 "SENSOR_STATE_WAIT_FOR_CAPABILITIES_RESPONSE" 5 "SENSOR_STATE_SEND_CAPABILITIES_REQUEST" 4 "SENSOR_STATE_WAIT_FOR_GENEALOGY_RESPONSE" 3 "SENSOR_STATE_SEND_GENEALOGY_REQUEST" 2 "SENSOR_STATE_WAIT_FOR_CODE_DESCRIPTOR_RESPONSE" 1 "SENSOR_STATE_SEND_CODE_DESCRIPTOR_REQUEST" 0 "SENSOR_STATE_WAIT_FOR_CONNECTION" ;
VAL_ 570 VCSEC_TPMSSensorType3 6 "SENSOR_TYPE_V5" 5 "SENSOR_TYPE_V4" 4 "SENSOR_TYPE_V3" 3 "SENSOR_TYPE_V2" 2 "SENSOR_TYPE_V1" 1 "SENSOR_TYPE_UNKNOWN" 0 "SENSOR_TYPE_NOT_IDENTIFIED" ;
VAL_ 761 VCSEC_bleDisconnectionReason 255 "UNKNOWN_REASON_FF" 62 "CONNECTION_FAILED_TO_ESTABLISH" 61 "MIC_FAILURE" 59 "UNACCEPTABLE_CONNECTION_INTERVAL" 41 "KEY_PAIRING_NOT_SUPPORTED" 40 "CONTROL_PACKET_INSTANT_PASSED" 34 "CONTROL_PACKET_TIMEOUT" 26 "UNSUPPORTED_REMOTE_FEATURE" 22 "HOST_REQUESTED_TERMINATION" 21 "REMOTE_DEVICE_POWER_OFF" 20 "REMOTE_DEVICE_LOW_RESOURCES" 19 "REMOTE_USER_TERMINATED" 8 "CONNECTION_SUPERVISION_TIMEOUT" 5 "AUTHENTICATION_FAILURE" 0 "UNKNOWN_REASON_0" ;
VAL_ 761 VCSEC_activeKeyReason 7 "ACTIVE_KEY_SELECTION_REASON_UWB_DEVICE_CLOSEST_TO_DOOR" 6 "ACTIVE_KEY_SELECTION_REASON_AUTO_PRESENT_DOOR_COMMAND" 5 "ACTIVE_KEY_SELECTION_REASON_ONLY_AUTHED_DEVICE" 4 "ACTIVE_KEY_SELECTION_REASON_RKE_ACTION" 3 "ACTIVE_KEY_SELECTION_REASON_BLE_DEVICE_CLOSEST_TO_DOOR" 2 "ACTIVE_KEY_SELECTION_REASON_RKE_AUTH" 1 "ACTIVE_KEY_SELECTION_REASON_NFC_AUTH" 0 "ACTIVE_KEY_SELECTION_REASON_NONE" ;
VAL_ 761 VCSEC_algoUsedForSummonRange0 1 "SUMMON_RANGE_ALGO_USED_UWB" 0 "SUMMON_RANGE_ALGO_USED_BLE" ;
VAL_ 761 VCSEC_algoUsedForSummonRange1 1 "SUMMON_RANGE_ALGO_USED_UWB" 0 "SUMMON_RANGE_ALGO_USED_BLE" ;
VAL_ 761 VCSEC_algoUsedForSummonRange2 1 "SUMMON_RANGE_ALGO_USED_UWB" 0 "SUMMON_RANGE_ALGO_USED_BLE" ;
VAL_ 761 VCSEC_NFCAuthFromBPillarFormFact 4 "KEY_FORM_FACTOR_COARSE_UNKNOWN" 3 "KEY_FORM_FACTOR_COARSE_ANDROID" 2 "KEY_FORM_FACTOR_COARSE_KEYFOB" 1 "KEY_FORM_FACTOR_COARSE_NFC_CARD" 0 "KEY_FORM_FACTOR_COARSE_NONE" ;
VAL_ 761 VCSEC_NFCAuthFromCenterConsoleFo 4 "KEY_FORM_FACTOR_COARSE_UNKNOWN" 3 "KEY_FORM_FACTOR_COARSE_ANDROID" 2 "KEY_FORM_FACTOR_COARSE_KEYFOB" 1 "KEY_FORM_FACTOR_COARSE_NFC_CARD" 0 "KEY_FORM_FACTOR_COARSE_NONE" ;
